VERSION "created by canmatrix"

NS_ :

BS_:

BU_: FLEA IMU_MMP2 MAP DMS VIC GWS MGW ADAS FVC CR_RL CR_RR CR_FL CR_FR FR_FC

BO_ 1970 SW_ID_Video: 8 FVC

BO_ 1983 DBC_Version: 2 MGW
 SG_ DBC_VersionIdMinor : 8|8@1+ (1,0) [0|255] ""  ADAS,FR_FC
 SG_ DBC_VersionIdMajor : 0|8@1+ (1,0) [0|255] ""  ADAS,FR_FC

BO_ 1969 SW_ID_RadarFront: 12 ADAS

BO_ 1968 SW_ID_DASy: 12 ADAS

BO_ 1793 FleaToDasyTP: 64 FLEA

BO_ 1792 DASyToFleaTP: 64 ADAS

BO_ 30 TimeSync: 8 MGW
 SG_ TimeSync_Type M : 7|8@0+ (1,0) [0|255] ""  ADAS,FVC,CR_RL,CR_RR,CR_FL,CR_FR,FR_FC
 SG_ TimeSync_CRC : 15|8@0+ (1,0) [0|255] ""  ADAS,FVC,CR_RL,CR_RR,CR_FL,CR_FR,FR_FC
 SG_ TimeSync_SequenceCounter : 19|4@0+ (1,0) [0|15] ""  ADAS,FVC,CR_RL,CR_RR,CR_FL,CR_FR,FR_FC
 SG_ TimeSync_TimeDomain : 23|4@0+ (1,0) [0|15] ""  ADAS,FVC,CR_RL,CR_RR,CR_FL,CR_FR,FR_FC
 SG_ TimeSync_UserByte0 m32 : 31|8@0+ (1,0) [0|255] ""  ADAS,FVC,CR_RL,CR_RR,CR_FL,CR_FR,FR_FC
 SG_ TimeSync_SyncTimeSec m32 : 39|32@0+ (1,0) [0|4294967295] ""  ADAS,FVC,CR_RL,CR_RR,CR_FL,CR_FR,FR_FC
 SG_ TimeSync_OverflowOfSeconds m40 : 25|2@0+ (1,0) [0|3] ""  ADAS,FVC,CR_RL,CR_RR,CR_FL,CR_FR,FR_FC
 SG_ TimeSync_SGW m40 : 26|1@0+ (1,0) [0|1] ""  ADAS,FVC,CR_RL,CR_RR,CR_FL,CR_FR,FR_FC
 SG_ TimeSync_Reserved0 m40 : 31|5@0+ (1,0) [0|31] ""  ADAS,FVC,CR_RL,CR_RR,CR_FL,CR_FR,FR_FC
 SG_ TimeSync_SyncTimeNSec m40 : 39|32@0+ (1,0) [0|4294967295] ""  ADAS,FVC,CR_RL,CR_RR,CR_FL,CR_FR,FR_FC

BO_ 1225 EHR_LOC_POSE: 16 MAP
 SG_ EHR_LOC_Status : 80|4@1+ (1,0) [0|15] ""  ADAS
 SG_ EHR_LOC_POSE_YAW : 64|16@1+ (0.01,0) [0|655.35] "degree"  ADAS
 SG_ EHR_LOC_POSE_LONG : 32|32@1+ (1E-007,-180) [-180|249.4967295] ""  ADAS
 SG_ EHR_LOC_POSE_LAT : 0|32@1+ (1E-007,-90) [-90|339.4967295] ""  ADAS

BO_ 1224 EHR_GNSS_POS: 16 MAP
 SG_ EHR_GNSS_Stddev_long : 80|16@1+ (0.001,0) [0|65.535] "m"  ADAS
 SG_ EHR_GNSS_Stddev_lat : 64|16@1+ (0.001,0) [0|65.535] "m"  ADAS
 SG_ EHR_GNSS_POS_LONG : 32|32@1+ (1E-007,-180) [-180|249.4967295] ""  ADAS
 SG_ EHR_GNSS_POS_LAT : 0|32@1+ (1E-007,-90) [-90|339.4967295] ""  ADAS

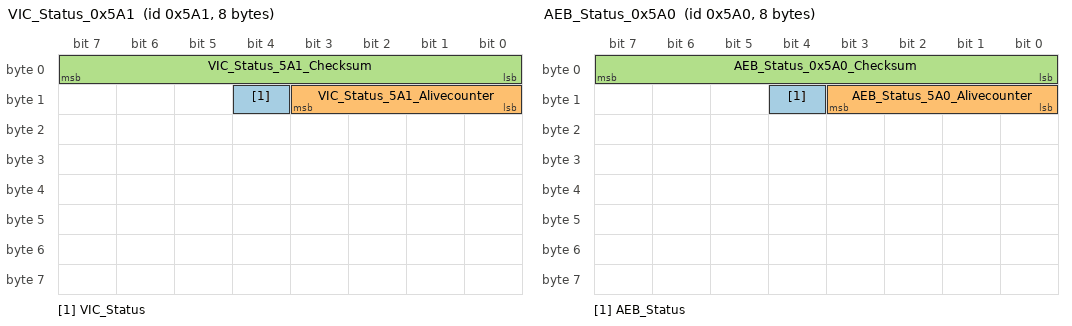
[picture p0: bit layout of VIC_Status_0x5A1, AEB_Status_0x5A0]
BO_ 1441 VIC_Status_0x5A1: 8 VIC
 SG_ VIC_Status : 12|1@1+ (1,0) [0|1] ""  MGW
 SG_ VIC_Status_5A1_Alivecounter : 8|4@1+ (1,0) [0|15] ""  MGW
 SG_ VIC_Status_5A1_Checksum : 0|8@1+ (1,0) [0|255] ""  MGW

BO_ 1440 AEB_Status_0x5A0: 8 MGW
 SG_ AEB_Status : 12|1@1+ (1,0) [0|1] ""  VIC
 SG_ AEB_Status_5A0_Alivecounter : 8|4@1+ (1,0) [0|15] ""  VIC
 SG_ AEB_Status_0x5A0_Checksum : 0|8@1+ (1,0) [0|255] ""  VIC

BO_ 1791 VariantCoding: 8 MGW
 SG_ Vehicle_Variant : 0|4@1+ (1,0) [0|15] ""  ADAS

BO_ 291 ACC_06_DASy: 16 ADAS
 SG_ ADAS_VehSecureReq : 79|2@0+ (1,0) [0|1] ""  MGW
 SG_ ADAS_LimAx_LIM : 119|16@0+ (0.000381,-12) [-12|12.968835] ""  MGW
 SG_ ADAS_ShtDwnStrat_ACC : 65|2@0+ (1,0) [0|3] ""  MGW
 SG_ ADAS_ShtDwnStrat_Lim : 77|2@0+ (1,0) [0|3] ""  MGW
 SG_ ADAS_LimActReq : 75|1@0+ (1,0) [0|1] ""  MGW
 SG_ ADAS_EngStartRun_Req : 74|1@0+ (1,0) [0|1] ""  MGW
 SG_ ADAS_CoastReq_ACC : 72|1@0+ (1,0) [0|1] ""  MGW
 SG_ ADAS_Sts_LIM : 68|3@0+ (1,0) [0|7] ""  MGW
 SG_ LIM_pos_Sollbeschl_Grad_02_D : 111|8@0+ (0.05,0) [0|12.75] "Unit_MeterPerCubicSecon"  MGW
 SG_ LIM_neg_Sollbeschl_Grad_02_D : 103|8@0+ (0.05,0) [0|12.75] "Unit_MeterPerCubicSecon"  MGW
 SG_ LIM_zul_Regelabw_unten_D : 85|6@0+ (0.024,0) [0|1.512] "Unit_MeterPerSeconSquar"  MGW
 SG_ LIM_zul_Regelabw_oben_D : 92|5@0+ (0.0625,0) [0|1.9375] "Unit_MeterPerSeconSquar"  MGW
 SG_ ACC_pos_Sollbeschl_Grad_02_D : 55|8@0+ (0.05,0) [0|12.75] "Unit_MeterPerCubicSecon"  MGW
 SG_ ACC_neg_Sollbeschl_Grad_02_D : 47|8@0+ (0.05,0) [0|12.75] "Unit_MeterPerCubicSecon"  MGW
 SG_ ACC_Minimale_Bremsung_D : 56|1@0+ (1,0) [0|1] ""  MGW
 SG_ ACC_zul_Regelabw_unten_D : 23|6@0+ (0.024,0) [0|1.512] "Unit_MeterPerSeconSquar"  MGW
 SG_ ACC_zul_Regelabw_oben_D : 36|5@0+ (0.0625,0) [0|1.9375] "Unit_MeterPerSeconSquar"  MGW
 SG_ ACC_06_CheckSum_D : 7|8@0+ (1,0) [0|255] ""  MGW
 SG_ ACC_06_AliveCounter_D : 15|4@0+ (1,0) [0|14] ""  MGW

BO_ 842 ADAS_0x34A: 8 ADAS
 SG_ ADAS_Sts_HWA : 2|3@0+ (1,0) [0|7] ""  MGW
 SG_ ADAS_HiwayExitAuxSts : 5|3@0+ (1,0) [0|7] ""  MGW
 SG_ ADAS_ActvBtnDispReq_HEA : 7|2@0+ (1,0) [0|3] ""  MGW
 SG_ ADAS_Sts_ALC : 11|4@0+ (1,0) [0|15] ""  MGW,CR_RR
 SG_ ADAS_HandsOffTakeOverReq_ALC : 15|1@0+ (1,0) [0|1] ""  MGW
 SG_ ADAS_OverMod_ALC : 16|1@0+ (1,0) [0|1] ""  MGW
 SG_ ADAS_ALCAudioWarnLe : 17|1@0+ (1,0) [0|1] ""  MGW
 SG_ ADAS_LCReturnToLane : 19|2@0+ (1,0) [0|3] ""  MGW
 SG_ ADAS_LeLaneOccupied : 20|1@0+ (1,0) [0|1] ""  MGW
 SG_ ADAS_RiLaneOccupied : 21|1@0+ (1,0) [0|1] ""  MGW
 SG_ ADAS_LeLCArrow : 23|2@0+ (1,0) [0|3] ""  MGW
 SG_ ADAS_ALCAudioWarnRi : 24|1@0+ (1,0) [0|1] ""  MGW
 SG_ ADAS_LeLaneOccupiedWarn : 25|1@0+ (1,0) [0|1] ""  MGW
 SG_ ADAS_RiLaneOccupiedWarn : 26|1@0+ (1,0) [0|1] ""  MGW
 SG_ ADAS_ALCTakeOverReq : 27|1@0+ (1,0) [0|1] ""  MGW
 SG_ ADAS_LCSysFlt : 28|1@0+ (1,0) [0|1] ""  MGW
 SG_ ADAS_TurnLampOff : 30|2@0+ (1,0) [0|3] ""  MGW
 SG_ ADAS_CtrlrFlt : 41|2@0+ (1,0) [0|3] ""  MGW,FVC,CR_RL,CR_RR,CR_FL,CR_FR,FR_FC
 SG_ ADAS_RiLCArrow : 49|2@0+ (1,0) [0|3] ""  MGW
 SG_ ADAS_Sts_ESS : 52|3@0+ (1,0) [0|7] ""  MGW
 SG_ ADAS_Warn_ESS : 54|2@0+ (1,0) [0|3] ""  MGW
 SG_ ADAS_DrvrOccpyReq : 55|1@0+ (1,0) [0|1] ""  MGW

BO_ 1184 HMI_0x4A0_ADAS: 8 VIC
 SG_ MainSwitchACC : 0|1@1+ (1,0) [0|1] ""  MGW,ADAS
 SG_ MainSwitchADC : 1|1@1+ (1,0) [0|1] ""  MGW,ADAS
 SG_ MainSwitchACCplus : 2|1@1+ (1,0) [0|1] ""  MGW,ADAS
 SG_ MainSwitchTLR : 3|1@1+ (1,0) [0|1] ""  MGW,ADAS
 SG_ ACCplusActivationSubfeature_SLA : 4|1@1+ (1,0) [0|1] ""  MGW,ADAS
 SG_ ACCplusActivationSubfeatureCSA : 5|1@1+ (1,0) [0|1] ""  MGW,ADAS
 SG_ ACCplusActivationSubfeatureSPA : 6|1@1+ (1,0) [0|1] ""  MGW,ADAS
 SG_ ACCplusActivationSubfeatureFrict : 7|1@1+ (1,0) [0|1] ""  MGW,ADAS
 SG_ ACCDriverInputTimeGapChange : 8|1@1+ (1,0) [0|1] ""  MGW,ADAS
 SG_ ACCDriverInputSet : 9|1@1+ (1,0) [0|1] ""  MGW,ADAS
 SG_ ACCDriverInputResume : 10|1@1+ (1,0) [0|1] ""  MGW,ADAS
 SG_ ACCDriverInputSetSpeedDecrease : 11|1@1+ (1,0) [0|1] ""  MGW,ADAS
 SG_ ACCDriverInputSetSpeedIncrease : 12|1@1+ (1,0) [0|1] ""  MGW,ADAS
 SG_ ACCDriverInputConfirmation : 13|1@1+ (1,0) [0|1] ""  MGW,ADAS
 SG_ ADCVariantSelection : 14|3@1+ (1,0) [0|7] ""  MGW,ADAS
 SG_ ADCDriverInputActivationDeactiva : 17|1@1+ (1,0) [0|1] ""  MGW,ADAS
 SG_ ADCParameterSelection : 18|3@1+ (1,0) [0|7] ""  MGW,ADAS
 SG_ ACFDrivingMode : 21|3@1+ (1,0) [0|7] ""  MGW,ADAS
 SG_ Measurement_label : 60|4@1+ (1,0) [0|15] ""  MGW,ADAS
 SG_ FrontCollisionWarningSensitivity : 24|2@1+ (1,0) [0|3] ""  MGW,ADAS

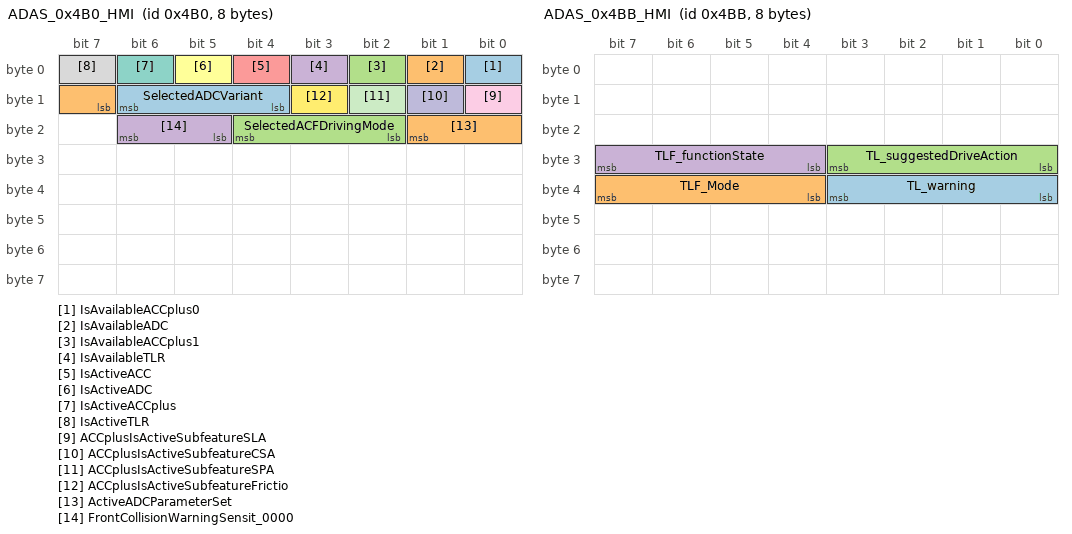
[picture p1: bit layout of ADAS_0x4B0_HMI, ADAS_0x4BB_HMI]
BO_ 1200 ADAS_0x4B0_HMI: 8 ADAS
 SG_ IsAvailableACCplus0 : 0|1@1+ (1,0) [0|1] ""  VIC,MGW
 SG_ IsAvailableADC : 1|1@1+ (1,0) [0|1] ""  VIC,MGW
 SG_ IsAvailableACCplus1 : 2|1@1+ (1,0) [0|1] ""  VIC,MGW
 SG_ IsAvailableTLR : 3|1@1+ (1,0) [0|1] ""  VIC,MGW
 SG_ IsActiveACC : 4|1@1+ (1,0) [0|1] ""  VIC,MGW
 SG_ IsActiveADC : 5|1@1+ (1,0) [0|1] ""  VIC,MGW
 SG_ IsActiveACCplus : 6|1@1+ (1,0) [0|1] ""  VIC,MGW
 SG_ IsActiveTLR : 7|1@1+ (1,0) [0|1] ""  VIC,MGW
 SG_ ACCplusIsActiveSubfeatureSLA : 8|1@1+ (1,0) [0|1] ""  VIC,MGW
 SG_ ACCplusIsActiveSubfeatureCSA : 9|1@1+ (1,0) [0|1] ""  VIC,MGW
 SG_ ACCplusIsActiveSubfeatureSPA : 10|1@1+ (1,0) [0|1] ""  VIC,MGW
 SG_ ACCplusIsActiveSubfeatureFrictio : 11|1@1+ (1,0) [0|1] ""  VIC,MGW
 SG_ SelectedADCVariant : 12|3@1+ (1,0) [0|7] ""  VIC,MGW
 SG_ ActiveADCParameterSet : 15|3@1+ (1,0) [0|7] ""  VIC,MGW
 SG_ SelectedACFDrivingMode : 18|3@1+ (1,0) [0|7] ""  VIC,MGW
 SG_ FrontCollisionWarningSensit_0000 : 21|2@1+ (1,0) [0|3] ""  VIC,MGW

BO_ 1210 ADAS_0x4BA_HMI: 64 ADAS
 SG_ TurnIndicatorSignal : 118|2@1+ (1,0) [0|3] ""  VIC,MGW
 SG_ AlcPremiumState : 116|2@1+ (1,0) [0|3] ""  VIC,MGW
 SG_ AlcPlusState : 114|2@1+ (1,0) [0|3] ""  VIC,MGW
 SG_ AlcEnhancedStatus : 112|2@1+ (1,0) [0|3] ""  VIC,MGW
 SG_ ALCFeatureStatus : 456|8@1+ (1,0) [0|31] ""  VIC,MGW
 SG_ LKAStatus : 464|4@1+ (1,0) [0|15] ""  VIC,MGW
 SG_ LDWStatus : 468|4@1+ (1,0) [0|15] ""  VIC,MGW
 SG_ ELKSLStatus : 472|4@1+ (1,0) [0|15] ""  VIC,MGW
 SG_ ELKHREStatus : 476|4@1+ (1,0) [0|15] ""  VIC,MGW
 SG_ ELKVREStatus : 480|4@1+ (1,0) [0|15] ""  VIC,MGW
 SG_ ELKOTStatus : 484|4@1+ (1,0) [0|15] ""  VIC,MGW
 SG_ ELKOCVStatus : 488|4@1+ (1,0) [0|15] ""  VIC,MGW
 SG_ OffsetReason : 451|4@1+ (1,0) [0|15] ""  VIC,MGW
 SG_ OffsetDirection : 446|2@1+ (1,0) [0|3] ""  VIC,MGW
 SG_ DisplayedLaneMarking4Y : 432|8@1- (0.06,0) [-7.68|7.62] "m"  VIC,MGW
 SG_ DisplayedLaneMarking3Y : 424|8@1- (0.06,0) [-7.68|7.62] "m"  VIC,MGW
 SG_ DisplayedLaneMarking2Y : 416|8@1- (0.06,0) [-7.68|7.62] "m"  VIC,MGW
 SG_ DisplayedLaneMarking1Y : 408|8@1- (0.06,0) [-7.68|7.62] "m"  VIC,MGW
 SG_ DisplayedLaneMarking4Type : 406|2@1+ (1,0) [0|3] ""  VIC,MGW
 SG_ DisplayedLaneMarking3Type : 404|2@1+ (1,0) [0|3] ""  VIC,MGW
 SG_ DisplayedLaneMarking2Type : 402|2@1+ (1,0) [0|3] ""  VIC,MGW
 SG_ DisplayedLaneMarking1Type : 400|2@1+ (1,0) [0|3] ""  VIC,MGW
 SG_ DisplayedLaneMarking4Color : 395|3@1+ (1,0) [0|7] ""  VIC,MGW
 SG_ DisplayedLaneMarking3Color : 392|3@1+ (1,0) [0|7] ""  VIC,MGW
 SG_ DisplayedLaneMarking2Color : 387|3@1+ (1,0) [0|7] ""  VIC,MGW
 SG_ DisplayedLaneMarking1Color : 384|3@1+ (1,0) [0|7] ""  VIC,MGW
 SG_ Number02 : 368|16@1+ (1,0) [0|65535] ""  VIC,MGW
 SG_ Number01 : 352|16@1+ (1,0) [0|65535] ""  VIC,MGW
 SG_ Indicator16 : 351|1@1+ (1,0) [0|1] ""  VIC,MGW
 SG_ Indicator15 : 350|1@1+ (1,0) [0|1] ""  VIC,MGW
 SG_ Indicator14 : 349|1@1+ (1,0) [0|1] ""  VIC,MGW
 SG_ Indicator13 : 348|1@1+ (1,0) [0|1] ""  VIC,MGW
 SG_ Indicator12 : 347|1@1+ (1,0) [0|1] ""  VIC,MGW
 SG_ Indicator11 : 346|1@1+ (1,0) [0|1] ""  VIC,MGW
 SG_ Indicator10 : 345|1@1+ (1,0) [0|1] ""  VIC,MGW
 SG_ Indicator09 : 344|1@1+ (1,0) [0|1] ""  VIC,MGW
 SG_ Indicator08 : 343|1@1+ (1,0) [0|1] ""  VIC,MGW
 SG_ Indicator07 : 342|1@1+ (1,0) [0|1] ""  VIC,MGW
 SG_ Indicator06 : 341|1@1+ (1,0) [0|1] ""  VIC,MGW
 SG_ Indicator05 : 340|1@1+ (1,0) [0|1] ""  VIC,MGW
 SG_ Indicator04 : 339|1@1+ (1,0) [0|1] ""  VIC,MGW
 SG_ Indicator03 : 338|1@1+ (1,0) [0|1] ""  VIC,MGW
 SG_ Indicator02 : 337|1@1+ (1,0) [0|1] ""  VIC,MGW
 SG_ Indicator01 : 336|1@1+ (1,0) [0|1] ""  VIC,MGW
 SG_ ACC_ICON_LADI : 334|2@1+ (1,0) [0|3] ""  VIC,MGW
 SG_ ADAS_4BA_CheckSum : 0|16@1+ (1,0) [0|65535] ""  VIC,MGW
 SG_ CurvatureInformation : 120|8@1- (25,0) [-3200|3175] "m"  VIC,MGW
 SG_ TrafficSignSpeedLimit : 128|5@1+ (5,0) [0|150] "kph"  VIC,MGW
 SG_ TrafficLightStatus : 140|2@1+ (1,0) [0|3] ""  VIC,MGW
 SG_ TrafficLightDisplayRequest : 136|2@1+ (1,0) [0|3] ""  VIC,MGW
 SG_ ACCTrafficLightReaction : 138|2@1+ (1,0) [0|3] ""  VIC,MGW
 SG_ SensorConeFrontCenter : 133|2@1+ (1,0) [0|3] ""  VIC,MGW
 SG_ NeighboringVehicle1VehicleType : 163|3@1+ (1,0) [0|7] ""  VIC,MGW
 SG_ NeighboringVehicle1X : 144|8@1+ (1.2,-50.4) [-50.4|255.6] "m"  VIC,MGW
 SG_ NeighboringVehicle1Y : 152|8@1- (0.06,0) [-7.68|7.62] "m"  VIC,MGW
 SG_ NeighboringVehicle1AugmentedData : 160|3@1+ (1,0) [0|7] ""  VIC,MGW
 SG_ NeighboringVehicle2VehicleType : 187|3@1+ (1,0) [0|7] ""  VIC,MGW
 SG_ NeighboringVehicle2X : 168|8@1+ (1.2,-50.4) [-50.4|255.6] "m"  VIC,MGW
 SG_ NeighboringVehicle2Y : 176|8@1- (0.06,0) [-7.68|7.62] "m"  VIC,MGW
 SG_ ADAS_4BA_AliveCounter : 16|8@1+ (1,0) [0|255] ""  VIC,MGW
 SG_ NeighboringVehicle2AugmentedData : 184|3@1+ (1,0) [0|7] ""  VIC,MGW
 SG_ NeighboringVehicle3VehicleType : 211|3@1+ (1,0) [0|7] ""  VIC,MGW
 SG_ NeighboringVehicle3X : 192|8@1+ (1.2,-50.4) [-50.4|255.6] "m"  VIC,MGW
 SG_ NeighboringVehicle3Y : 200|8@1- (0.06,0) [-7.68|7.62] "m"  VIC,MGW
 SG_ NeighboringVehicle3AugmentedData : 208|3@1+ (1,0) [0|7] ""  VIC,MGW
 SG_ NeighboringVehicle4VehicleType : 235|3@1+ (1,0) [0|7] ""  VIC,MGW
 SG_ NeighboringVehicle4X : 216|8@1+ (1.2,-50.4) [-50.4|255.6] "m"  VIC,MGW
 SG_ NeighboringVehicle4Y : 224|8@1- (0.06,0) [-7.68|7.62] "m"  VIC,MGW
 SG_ NeighboringVehicle4AugmentedData : 232|3@1+ (1,0) [0|7] ""  VIC,MGW
 SG_ NeighboringVehicle5VehicleType : 259|3@1+ (1,0) [0|7] ""  VIC,MGW
 SG_ NeighboringVehicle5X : 240|8@1+ (1.2,-50.4) [-50|250] "m"  VIC,MGW
 SG_ NeighboringVehicle5Y : 248|8@1- (0.06,0) [-7.68|7.62] "m"  VIC,MGW
 SG_ NeighboringVehicle5AugmentedData : 256|3@1+ (1,0) [0|7] ""  VIC,MGW
 SG_ NeighboringVehicle6VehicleType : 283|3@1+ (1,0) [0|7] ""  VIC,MGW
 SG_ NeighboringVehicle6X : 264|8@1+ (1.2,-50.4) [-50|250] "m"  VIC,MGW
 SG_ LedHadState : 24|4@1+ (1,0) [0|15] ""  VIC,MGW
 SG_ NeighboringVehicle6Y : 272|8@1- (0.06,0) [-7.68|7.62] "m"  VIC,MGW
 SG_ NeighboringVehicle6AugmentedData : 280|3@1+ (1,0) [0|7] ""  VIC,MGW
 SG_ NeighboringVehicle7VehicleType : 307|3@1+ (1,0) [0|7] ""  VIC,MGW
 SG_ NeighboringVehicle7X : 288|8@1+ (1.2,-50.4) [-50|250] "m"  VIC,MGW
 SG_ NeighboringVehicle7Y : 296|8@1- (0.06,0) [-7.68|7.62] "m"  VIC,MGW
 SG_ NeighboringVehicle7AugmentedData : 304|3@1+ (1,0) [0|7] ""  VIC,MGW
 SG_ NeighboringVehicle8VehicleType : 331|3@1+ (1,0) [0|7] ""  VIC,MGW
 SG_ HwaHfStatus : 28|3@1+ (1,0) [0|7] ""  VIC,MGW
 SG_ NeighboringVehicle8X : 312|8@1+ (1.2,-50.4) [-50.4|255.6] "m"  VIC,MGW
 SG_ NeighboringVehicle8Y : 320|8@1- (0.06,0) [-7.68|7.62] "m"  VIC,MGW
 SG_ NeighboringVehicle8AugmentedData : 328|3@1+ (1,0) [0|7] ""  VIC,MGW
 SG_ HwaHonStatus : 32|3@1+ (1,0) [0|7] ""  VIC,MGW
 SG_ HwaAccStatus : 35|3@1+ (1,0) [0|7] ""  VIC,MGW
 SG_ SetSpeed : 40|8@1+ (1,0) [0|255] "kph"  VIC,MGW
 SG_ SetSpeedColor : 48|3@1+ (1,0) [0|7] ""  VIC,MGW
 SG_ DisplayedEgoSpeed : 56|8@1+ (1,0) [0|255] "kph"  VIC,MGW
 SG_ DisplayedEgoSpeedColor : 64|3@1+ (1,0) [0|7] ""  VIC,MGW
 SG_ DisplayedLaneMarkingLeftType : 67|2@1+ (1,0) [0|3] ""  MGW
 SG_ DisplayedLaneMarkingLeftColor : 69|3@1+ (1,0) [0|7] ""  MGW
 SG_ DisplayedLaneMarkingRightType : 72|2@1+ (1,0) [0|3] ""  MGW
 SG_ DisplayedLaneMarkingRightColor : 74|3@1+ (1,0) [0|7] ""  MGW
 SG_ TimeGapSetValue : 77|3@1+ (1,0) [0|7] ""  VIC,MGW
 SG_ TimeGapColor : 80|3@1+ (1,0) [0|7] ""  VIC,MGW
 SG_ ReducedTimeGap : 440|6@1+ (1,0) [0|63] "s"  VIC,MGW
 SG_ AdcStateInformation : 448|3@1+ (1,0) [0|7] ""  VIC,MGW
 SG_ EgoLaneChange : 83|3@1+ (1,0) [0|7] ""  VIC,MGW
 SG_ DisplayedTextMessageId : 88|8@1+ (1,0) [0|255] ""  VIC,MGW
 SG_ PopupTextMessage : 86|2@1+ (1,0) [0|3] ""  VIC,MGW
 SG_ AudioNotificationId : 51|4@1+ (1,0) [0|15] ""  VIC,MGW
 SG_ AuxiliarySymbol : 96|6@1+ (1,0) [0|63] ""  VIC,MGW
 SG_ EgoLaneAssignment : 102|2@1+ (1,0) [0|3] ""  VIC,MGW
 SG_ TrafficLightDistance : 104|4@1+ (1,0) [0|15] "m"  VIC,MGW

BO_ 1211 ADAS_0x4BB_HMI: 8 MGW
 SG_ TL_warning : 35|4@0+ (1,0) [0|15] ""  ADAS,FR_FC
 SG_ TLF_Mode : 39|4@0+ (1,0) [0|15] ""  ADAS,FR_FC
 SG_ TL_suggestedDriveAction : 27|4@0+ (1,0) [0|15] ""  ADAS,FR_FC
 SG_ TLF_functionState : 31|4@0+ (1,0) [0|15] ""  ADAS,FR_FC

BO_ 1212 ADAS_0x4BC_HMI: 64 ADAS
 SG_ ADAS_TrafficSign1_Main : 0|8@1+ (1,0) [0|255] ""  VIC,MGW
 SG_ ADAS_TrafficSign1_AdditionalSign : 8|5@1+ (1,0) [0|31] ""  VIC,MGW
 SG_ ADAS_TrafficSign1_Distance : 13|5@1+ (1,0) [0|31] ""  VIC,MGW
 SG_ ADAS_TrafficSign1_Status : 18|3@1+ (1,0) [0|7] ""  VIC,MGW
 SG_ ADAS_TrafficSign2_Main : 21|8@1+ (1,0) [0|255] ""  VIC,MGW
 SG_ ADAS_TrafficSign2_AdditionalSign : 29|5@1+ (1,0) [0|31] ""  VIC,MGW
 SG_ ADAS_TrafficSign2_Distance : 34|5@1+ (1,0) [0|31] ""  VIC,MGW
 SG_ ADAS_TrafficSign2_Status : 39|3@1+ (1,0) [0|7] ""  VIC,MGW
 SG_ ADAS_TrafficSign3_Main : 42|8@1+ (1,0) [0|255] ""  VIC,MGW
 SG_ ADAS_TrafficSign3_AdditionalSign : 50|5@1+ (1,0) [0|31] ""  VIC,MGW
 SG_ ADAS_TrafficSign3_Distance : 55|5@1+ (1,0) [0|31] ""  VIC,MGW
 SG_ ADAS_TrafficSign3_Status : 60|3@1+ (1,0) [0|7] ""  VIC,MGW
 SG_ ADAS_RSF_Status : 63|3@1+ (1,0) [0|7] ""  VIC,MGW
 SG_ ADAS_Curv_1_dy_00 : 66|9@1+ (0.1,-25.6) [-25.6|25.5] "m"  VIC,MGW
 SG_ ADAS_Curv_1_dy_01 : 75|9@1+ (0.1,-25.6) [-25.6|25.5] "m"  VIC,MGW
 SG_ ADAS_Curv_1_dy_02 : 84|9@1+ (0.1,-25.6) [-25.6|25.5] "m"  VIC,MGW
 SG_ ADAS_Curv_1_dy_03 : 93|9@1+ (0.1,-25.6) [-25.6|25.5] "m"  VIC,MGW
 SG_ ADAS_Curv_1_dy_04 : 102|9@1+ (0.1,-25.6) [-25.6|25.5] "m"  VIC,MGW
 SG_ ADAS_Curv_1_dy_05 : 111|9@1+ (0.1,-25.6) [-25.6|25.5] "m"  VIC,MGW
 SG_ ADAS_Curv_1_dy_06 : 120|9@1+ (0.1,-25.6) [-25.6|25.5] "m"  VIC,MGW
 SG_ ADAS_Curv_1_dy_07 : 129|9@1+ (0.1,-25.6) [-25.6|25.5] "m"  VIC,MGW
 SG_ ADAS_Curv_1_dy_08 : 138|9@1+ (0.1,-25.6) [-25.6|25.5] "m"  VIC,MGW
 SG_ ADAS_Curv_1_dy_09 : 147|9@1+ (0.1,-25.6) [-25.6|25.5] "m"  VIC,MGW
 SG_ ADAS_Curv_1_dy_10 : 156|9@1+ (0.1,-25.6) [-25.6|25.5] "m"  VIC,MGW
 SG_ ADAS_Curv_1_dy_11 : 165|9@1+ (0.1,-25.6) [-25.6|25.5] "m"  VIC,MGW
 SG_ ADAS_Curv_1_dy_12 : 174|9@1+ (0.1,-25.6) [-25.6|25.5] "m"  VIC,MGW
 SG_ ADAS_Curv_1_dy_13 : 183|9@1+ (0.1,-25.6) [-25.6|25.5] "m"  VIC,MGW
 SG_ ADAS_Curv_1_dy_14 : 192|9@1+ (0.1,-25.6) [-25.6|25.5] "m"  VIC,MGW
 SG_ ADAS_Curv_1_dy_15 : 201|9@1+ (0.1,-25.6) [-25.6|25.5] "m"  VIC,MGW
 SG_ ADAS_Curv_2_dy_00 : 210|9@1+ (0.1,-25.6) [-25.6|25.5] "m"  VIC,MGW
 SG_ ADAS_Curv_2_dy_01 : 219|9@1+ (0.1,-25.6) [-25.6|25.5] "m"  VIC,MGW
 SG_ ADAS_Curv_2_dy_02 : 228|9@1+ (0.1,-25.6) [-25.6|25.5] "m"  VIC,MGW
 SG_ ADAS_Curv_2_dy_03 : 237|9@1+ (0.1,-25.6) [-25.6|25.5] "m"  VIC,MGW
 SG_ ADAS_Curv_2_dy_04 : 246|9@1+ (0.1,-25.6) [-25.6|25.5] "m"  VIC,MGW
 SG_ ADAS_Curv_2_dy_05 : 255|9@1+ (0.1,-25.6) [-25.6|25.5] "m"  VIC,MGW
 SG_ ADAS_Curv_2_dy_06 : 264|9@1+ (0.1,-25.6) [-25.6|25.5] "m"  VIC,MGW
 SG_ ADAS_Curv_2_dy_07 : 273|9@1+ (0.1,-25.6) [-25.6|25.5] "m"  VIC,MGW
 SG_ ADAS_Curv_2_dy_08 : 282|9@1+ (0.1,-25.6) [-25.6|25.5] "m"  VIC,MGW
 SG_ ADAS_Curv_2_dy_09 : 291|9@1+ (0.1,-25.6) [-25.6|25.5] "m"  VIC,MGW
 SG_ ADAS_Curv_2_dy_10 : 300|9@1+ (0.1,-25.6) [-25.6|25.5] "m"  VIC,MGW
 SG_ ADAS_Curv_2_dy_11 : 309|9@1+ (0.1,-25.6) [-25.6|25.5] "m"  VIC,MGW
 SG_ ADAS_Curv_2_dy_12 : 318|9@1+ (0.1,-25.6) [-25.6|25.5] "m"  VIC,MGW
 SG_ ADAS_Curv_2_dy_13 : 327|9@1+ (0.1,-25.6) [-25.6|25.5] "m"  VIC,MGW
 SG_ ADAS_Curv_2_dy_14 : 336|9@1+ (0.1,-25.6) [-25.6|25.5] "m"  VIC,MGW
 SG_ ADAS_Curv_2_dy_15 : 345|9@1+ (0.1,-25.6) [-25.6|25.5] "m"  VIC,MGW
 SG_ ADAS_Curv_3_dy_00 : 354|9@1+ (0.1,-25.6) [-25.6|25.5] "m"  VIC,MGW
 SG_ ADAS_Curv_3_dy_01 : 363|9@1+ (0.1,-25.6) [-25.6|25.5] "m"  VIC,MGW
 SG_ ADAS_Curv_3_dy_02 : 372|9@1+ (0.1,-25.6) [-25.6|25.5] "m"  VIC,MGW
 SG_ ADAS_Curv_3_dy_03 : 381|9@1+ (0.1,-25.6) [-25.6|25.5] "m"  VIC,MGW
 SG_ ADAS_Curv_3_dy_04 : 390|9@1+ (0.1,-25.6) [-25.6|25.5] "m"  VIC,MGW
 SG_ ADAS_Curv_3_dy_05 : 399|9@1+ (0.1,-25.6) [-25.6|25.5] "m"  VIC,MGW
 SG_ ADAS_Curv_3_dy_06 : 408|9@1+ (0.1,-25.6) [-25.6|25.5] "m"  VIC,MGW
 SG_ ADAS_Curv_3_dy_07 : 417|9@1+ (0.1,-25.6) [-25.6|25.5] "m"  VIC,MGW
 SG_ ADAS_Curv_3_dy_08 : 426|9@1+ (0.1,-25.6) [-25.6|25.5] "m"  VIC,MGW
 SG_ ADAS_Curv_3_dy_09 : 435|9@1+ (0.1,-25.6) [-25.6|25.5] "m"  VIC,MGW
 SG_ ADAS_Curv_3_dy_10 : 444|9@1+ (0.1,-25.6) [-25.6|25.5] "m"  VIC,MGW
 SG_ ADAS_Curv_3_dy_11 : 453|9@1+ (0.1,-25.6) [-25.6|25.5] "m"  VIC,MGW
 SG_ ADAS_Curv_3_dy_12 : 462|9@1+ (0.1,-25.6) [-25.6|25.5] "m"  VIC,MGW
 SG_ ADAS_Curv_3_dy_13 : 471|9@1+ (0.1,-25.6) [-25.6|25.5] "m"  VIC,MGW
 SG_ ADAS_Curv_3_dy_14 : 480|9@1+ (0.1,-25.6) [-25.6|25.5] "m"  VIC,MGW
 SG_ ADAS_Curv_3_dy_15 : 489|9@1+ (0.1,-25.6) [-25.6|25.5] "m"  VIC,MGW
 SG_ ADAS_Curv_1_NumValidPoints : 498|4@1+ (1,0) [0|15] ""  VIC,MGW
 SG_ ADAS_Curv_2_NumValidPoints : 502|4@1+ (1,0) [0|15] ""  VIC,MGW
 SG_ ADAS_Curv_3_NumValidPoints : 506|4@1+ (1,0) [0|15] ""  VIC,MGW

BO_ 1213 ADAS_0x4BD_HMI: 64 ADAS
 SG_ ADAS_Curv_4_NumValidPoints : 0|4@1+ (1,0) [0|15] ""  VIC,MGW
 SG_ ADAS_Curv_RefLine_NumValidPoints : 4|4@1+ (1,0) [0|15] ""  VIC,MGW
 SG_ ADAS_Curv_4_dy_00 : 8|9@1+ (0.1,-25.6) [-25.6|25.5] "m"  VIC,MGW
 SG_ ADAS_Curv_4_dy_01 : 17|9@1+ (0.1,-25.6) [-25.6|25.5] "m"  VIC,MGW
 SG_ ADAS_Curv_4_dy_02 : 26|9@1+ (0.1,-25.6) [-25.6|25.5] "m"  VIC,MGW
 SG_ ADAS_Curv_4_dy_03 : 35|9@1+ (0.1,-25.6) [-25.6|25.5] "m"  VIC,MGW
 SG_ ADAS_Curv_4_dy_04 : 44|9@1+ (0.1,-25.6) [-25.6|25.5] "m"  VIC,MGW
 SG_ ADAS_Curv_4_dy_05 : 53|9@1+ (0.1,-25.6) [-25.6|25.5] "m"  VIC,MGW
 SG_ ADAS_Curv_4_dy_06 : 62|9@1+ (0.1,-25.6) [-25.6|25.5] "m"  VIC,MGW
 SG_ ADAS_Curv_4_dy_07 : 71|9@1+ (0.1,-25.6) [-25.6|25.5] "m"  VIC,MGW
 SG_ ADAS_Curv_4_dy_08 : 80|9@1+ (0.1,-25.6) [-25.6|25.5] "m"  VIC,MGW
 SG_ ADAS_Curv_4_dy_09 : 89|9@1+ (0.1,-25.6) [-25.6|25.5] "m"  VIC,MGW
 SG_ ADAS_Curv_4_dy_10 : 98|9@1+ (0.1,-25.6) [-25.6|25.5] "m"  VIC,MGW
 SG_ ADAS_Curv_4_dy_11 : 107|9@1+ (0.1,-25.6) [-25.6|25.5] "m"  VIC,MGW
 SG_ ADAS_Curv_4_dy_12 : 116|9@1+ (0.1,-25.6) [-25.6|25.5] "m"  VIC,MGW
 SG_ ADAS_Curv_4_dy_13 : 125|9@1+ (0.1,-25.6) [-25.6|25.5] "m"  VIC,MGW
 SG_ ADAS_Curv_4_dy_14 : 134|9@1+ (0.1,-25.6) [-25.6|25.5] "m"  VIC,MGW
 SG_ ADAS_Curv_4_dy_15 : 143|9@1+ (0.1,-25.6) [-25.6|25.5] "m"  VIC,MGW
 SG_ ADAS_Curv_RefLine_dy_00 : 152|9@1+ (0.1,-25.6) [-25.6|25.5] "m"  VIC,MGW
 SG_ ADAS_Curv_RefLine_dy_01 : 161|9@1+ (0.1,-25.6) [-25.6|25.5] "m"  VIC,MGW
 SG_ ADAS_Curv_RefLine_dy_02 : 170|9@1+ (0.1,-25.6) [-25.6|25.5] "m"  VIC,MGW
 SG_ ADAS_Curv_RefLine_dy_03 : 179|9@1+ (0.1,-25.6) [-25.6|25.5] "m"  VIC,MGW
 SG_ ADAS_Curv_RefLine_dy_04 : 188|9@1+ (0.1,-25.6) [-25.6|25.5] "m"  VIC,MGW
 SG_ ADAS_Curv_RefLine_dy_05 : 197|9@1+ (0.1,-25.6) [-25.6|25.5] "m"  VIC,MGW
 SG_ ADAS_Curv_RefLine_dy_06 : 206|9@1+ (0.1,-25.6) [-25.6|25.5] "m"  VIC,MGW
 SG_ ADAS_Curv_RefLine_dy_07 : 215|9@1+ (0.1,-25.6) [-25.6|25.5] "m"  VIC,MGW
 SG_ ADAS_Curv_RefLine_dy_08 : 224|9@1+ (0.1,-25.6) [-25.6|25.5] "m"  VIC,MGW
 SG_ ADAS_Curv_RefLine_dy_09 : 233|9@1+ (0.1,-25.6) [-25.6|25.5] "m"  VIC,MGW
 SG_ ADAS_Curv_RefLine_dy_10 : 242|9@1+ (0.1,-25.6) [-25.6|25.5] "m"  VIC,MGW
 SG_ ADAS_Curv_RefLine_dy_11 : 251|9@1+ (0.1,-25.6) [-25.6|25.5] "m"  VIC,MGW
 SG_ ADAS_Curv_RefLine_dy_12 : 260|9@1+ (0.1,-25.6) [-25.6|25.5] "m"  VIC,MGW
 SG_ ADAS_Curv_RefLine_dy_13 : 269|9@1+ (0.1,-25.6) [-25.6|25.5] "m"  VIC,MGW
 SG_ ADAS_Curv_RefLine_dy_14 : 278|9@1+ (0.1,-25.6) [-25.6|25.5] "m"  VIC,MGW
 SG_ ADAS_Curv_RefLine_dy_15 : 287|9@1+ (0.1,-25.6) [-25.6|25.5] "m"  VIC,MGW

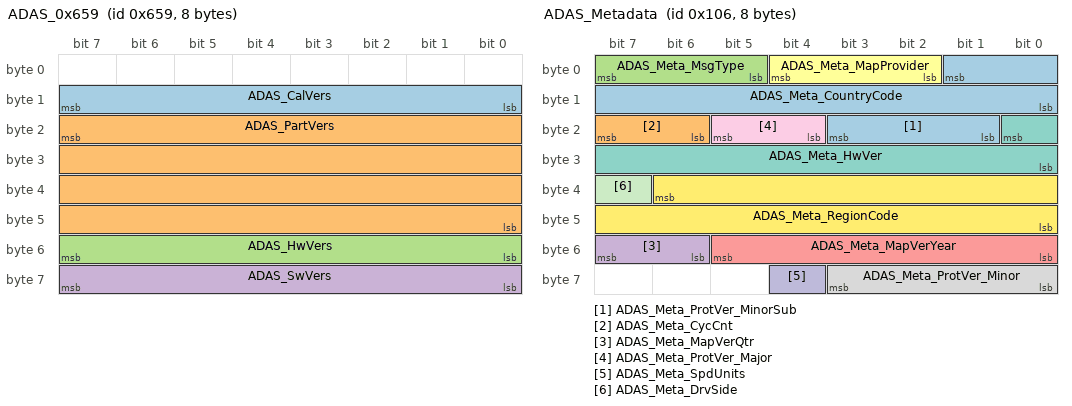
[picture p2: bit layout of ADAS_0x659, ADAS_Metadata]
BO_ 1625 ADAS_0x659: 8 ADAS
 SG_ ADAS_CalVers : 15|8@0+ (1,0) [0|255] ""  MGW
 SG_ ADAS_PartVers : 23|32@0+ (1,0) [0|4294967295] ""  MGW
 SG_ ADAS_HwVers : 55|8@0+ (1,0) [0|255] ""  MGW
 SG_ ADAS_SwVers : 63|8@0+ (1,0) [0|255] ""  MGW

BO_ 262 ADAS_Metadata: 8 MGW
 SG_ ADAS_Meta_ProtVer_MinorSub : 19|3@0+ (1,0) [0|7] ""  ADAS
 SG_ ADAS_Meta_CycCnt : 23|2@0+ (1,0) [0|3] ""  ADAS
 SG_ ADAS_Meta_MsgType : 7|3@0+ (1,0) [0|7] ""  ADAS
 SG_ ADAS_Meta_MapVerQtr : 55|2@0+ (1,1) [1|4] "Qtr"  ADAS
 SG_ ADAS_Meta_MapVerYear : 53|6@0+ (1,2000) [2000|2063] "Year"  ADAS
 SG_ ADAS_Meta_MapProvider : 4|3@0+ (1,0) [0|7] ""  ADAS
 SG_ ADAS_Meta_HwVer : 16|9@0+ (1,0) [0|511] ""  ADAS
 SG_ ADAS_Meta_ProtVer_Minor : 59|4@0+ (1,0) [0|15] ""  ADAS
 SG_ ADAS_Meta_ProtVer_Major : 21|2@0+ (1,0) [0|3] ""  ADAS
 SG_ ADAS_Meta_SpdUnits : 60|1@0+ (1,0) [0|1] ""  ADAS
 SG_ ADAS_Meta_DrvSide : 39|1@0+ (1,0) [0|1] ""  ADAS
 SG_ ADAS_Meta_RegionCode : 38|15@0+ (1,0) [0|32767] ""  ADAS
 SG_ ADAS_Meta_CountryCode : 1|10@0+ (1,0) [0|1023] ""  ADAS

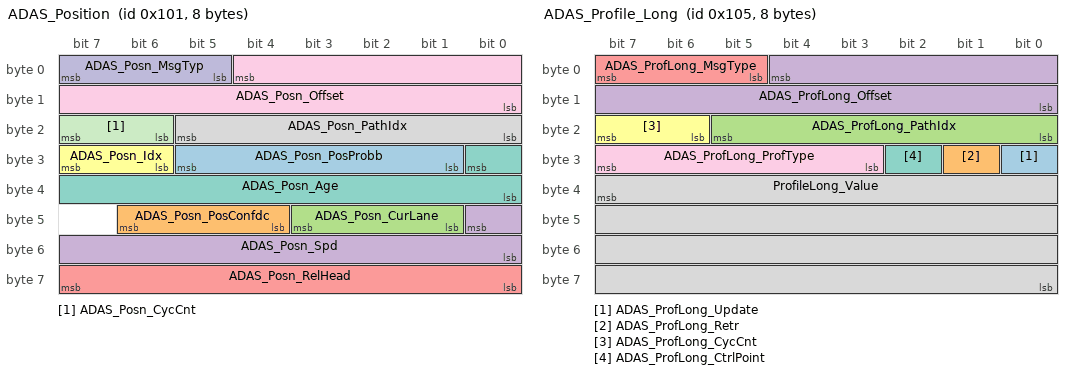
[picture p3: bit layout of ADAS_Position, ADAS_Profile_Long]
BO_ 257 ADAS_Position: 8 MGW
 SG_ ADAS_Posn_PosProbb : 29|5@0+ (3.333,0) [0|100] "%"  ADAS
 SG_ ADAS_Posn_PosConfdc : 46|3@0+ (1,0) [0|7] ""  ADAS
 SG_ ADAS_Posn_CurLane : 43|3@0+ (1,0) [0|7] ""  ADAS
 SG_ ADAS_Posn_Spd : 40|9@0+ (0.2,-12.8) [-12.8|89.2] "m/s"  ADAS
 SG_ ADAS_Posn_RelHead : 63|8@0+ (1.417,0) [0|358] "deg"  ADAS
 SG_ ADAS_Posn_Idx : 31|2@0+ (1,0) [0|3] ""  ADAS
 SG_ ADAS_Posn_Age : 24|9@0+ (5,0) [0|2545] "ms"  ADAS
 SG_ ADAS_Posn_PathIdx : 21|6@0+ (1,0) [8|63] ""  ADAS
 SG_ ADAS_Posn_Offset : 4|13@0+ (1,0) [0|8190] "m"  ADAS
 SG_ ADAS_Posn_MsgTyp : 7|3@0+ (1,0) [0|7] ""  ADAS
 SG_ ADAS_Posn_CycCnt : 23|2@0+ (1,0) [0|3] ""  ADAS

BO_ 261 ADAS_Profile_Long: 8 MGW
 SG_ ADAS_ProfLong_Update : 24|1@0+ (1,0) [0|1] ""  ADAS
 SG_ ADAS_ProfLong_Retr : 25|1@0+ (1,0) [0|1] ""  ADAS
 SG_ ADAS_ProfLong_PathIdx : 21|6@0+ (1,0) [8|63] ""  ADAS
 SG_ ADAS_ProfLong_Offset : 4|13@0+ (1,0) [0|8190] "m"  ADAS
 SG_ ADAS_ProfLong_MsgType : 7|3@0+ (1,0) [0|7] ""  ADAS
 SG_ ADAS_ProfLong_CycCnt : 23|2@0+ (1,0) [0|3] ""  ADAS
 SG_ ADAS_ProfLong_CtrlPoint : 26|1@0+ (1,0) [0|1] ""  ADAS
 SG_ ProfileLong_Value : 39|32@0+ (1,0) [0|4290000000] ""  ADAS
 SG_ ADAS_ProfLong_ProfType : 31|5@0+ (1,0) [0|31] ""  ADAS

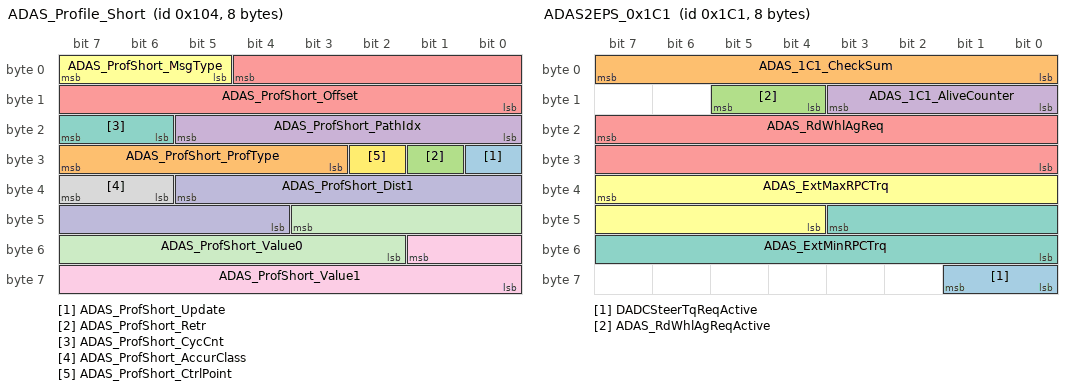
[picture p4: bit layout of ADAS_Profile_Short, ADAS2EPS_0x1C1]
BO_ 260 ADAS_Profile_Short: 8 MGW
 SG_ ADAS_ProfShort_Update : 24|1@0+ (1,0) [0|1] ""  ADAS
 SG_ ADAS_ProfShort_ProfType : 31|5@0+ (1,0) [0|31] ""  ADAS
 SG_ ADAS_ProfShort_Retr : 25|1@0+ (1,0) [0|1] ""  ADAS
 SG_ ADAS_ProfShort_PathIdx : 21|6@0+ (1,0) [8|63] ""  ADAS
 SG_ ADAS_ProfShort_Offset : 4|13@0+ (1,0) [0|8190] "m"  ADAS
 SG_ ADAS_ProfShort_MsgType : 7|3@0+ (1,0) [0|7] ""  ADAS
 SG_ ADAS_ProfShort_CycCnt : 23|2@0+ (1,0) [0|3] ""  ADAS
 SG_ ADAS_ProfShort_AccurClass : 39|2@0+ (1,0) [0|3] ""  ADAS
 SG_ ADAS_ProfShort_Value1 : 49|10@0+ (1,0) [0|1023] ""  ADAS
 SG_ ADAS_ProfShort_Dist1 : 37|10@0+ (1,0) [0|1022] "m"  ADAS
 SG_ ADAS_ProfShort_Value0 : 43|10@0+ (1,0) [0|1023] ""  ADAS
 SG_ ADAS_ProfShort_CtrlPoint : 26|1@0+ (1,0) [0|1] ""  ADAS

BO_ 258 ADAS_Segment: 8 MGW
 SG_ ADAS_Seg_PartOfCalcRoute : 47|2@0+ (1,0) [0|3] ""  ADAS
 SG_ ADAS_Seg_RelProbb : 39|5@0+ (3.333,0) [0|100] "%"  ADAS
 SG_ ADAS_Seg_Offset : 4|13@0+ (1,0) [0|8190] "m"  ADAS
 SG_ ADAS_Seg_Retr : 25|1@0+ (1,0) [0|1] ""  ADAS
 SG_ ADAS_Seg_PathIdx : 21|6@0+ (1,0) [8|63] ""  ADAS
 SG_ ADAS_Seg_MsgType : 7|3@0+ (1,0) [0|7] ""  ADAS
 SG_ ADAS_Seg_FormOfWay : 43|4@0+ (1,0) [0|14] ""  ADAS
 SG_ ADAS_Seg_CycCnt : 23|2@0+ (1,0) [0|3] ""  ADAS
 SG_ ADAS_Seg_CmplxInsct : 45|2@0+ (1,0) [0|3] ""  ADAS
 SG_ ADAS_Seg_BuildUpArea : 27|2@0+ (1,0) [0|3] ""  ADAS
 SG_ ADAS_Seg_DividedRoad : 62|2@0+ (1,0) [0|3] ""  ADAS
 SG_ ADAS_Seg_Bridge : 29|2@0+ (1,0) [0|3] ""  ADAS
 SG_ ADAS_Seg_Tunnel : 31|2@0+ (1,0) [0|3] ""  ADAS
 SG_ ADAS_Seg_NumOfLaneOppDir : 60|2@0+ (1,0) [0|3] ""  ADAS
 SG_ ADAS_Seg_NumOfLaneDrvDir : 58|3@0+ (1,0) [0|7] ""  ADAS
 SG_ ADAS_Seg_EffSpdLmtType : 50|3@0+ (1,0) [0|7] ""  ADAS
 SG_ ADAS_Seg_EffSpdLmt : 55|5@0+ (1,0) [0|255] "(k)mp/h"  ADAS
 SG_ ADAS_Seg_FuncRoadClass : 34|3@0+ (1,0) [0|6] ""  ADAS
 SG_ ADAS_Seg_Update : 24|1@0+ (1,0) [0|1] ""  ADAS

BO_ 259 ADAS_Stub: 8 MGW
 SG_ ADAS_Stub_PartOfCalcRoute : 47|2@0+ (1,0) [0|3] ""  ADAS
 SG_ ADAS_Stub_FuncRoadClass : 34|3@0+ (1,0) [0|6] ""  ADAS
 SG_ ADAS_Stub_LastStub : 63|1@0+ (1,0) [0|1] ""  ADAS
 SG_ ADAS_Stub_Update : 24|1@0+ (1,0) [0|1] ""  ADAS
 SG_ ADAS_Stub_SubPathIdx : 31|6@0+ (1,0) [8|63] ""  ADAS
 SG_ ADAS_Stub_Retr : 25|1@0+ (1,0) [0|1] ""  ADAS
 SG_ ADAS_Stub_PathIdx : 21|6@0+ (1,0) [8|63] ""  ADAS
 SG_ ADAS_Stub_Offset : 4|13@0+ (1,0) [0|8190] "m"  ADAS
 SG_ ADAS_Stub_NumOfLaneOppDir : 60|2@0+ (1,0) [0|3] ""  ADAS
 SG_ ADAS_Stub_NumOfLaneDrvDir : 58|3@0+ (1,0) [0|7] ""  ADAS
 SG_ ADAS_Stub_MsgType : 7|3@0+ (1,0) [0|7] ""  ADAS
 SG_ ADAS_Stub_FormOfWay : 43|4@0+ (1,0) [0|14] ""  ADAS
 SG_ ADAS_Stub_CycCnt : 23|2@0+ (1,0) [0|3] ""  ADAS
 SG_ ADAS_Stub_RtOfWay : 62|2@0+ (1,0) [0|3] ""  ADAS
 SG_ ADAS_Stub_CmplxInsct : 45|2@0+ (1,0) [0|3] ""  ADAS
 SG_ ADAS_Stub_RelProbb : 39|5@0+ (3.333,0) [0|100] "%"  ADAS
 SG_ ADAS_Stub_TurnAngl : 55|8@0+ (1.417,0) [0|358] "deg"  ADAS

BO_ 449 ADAS2EPS_0x1C1: 8 ADAS
 SG_ DADCSteerTqReqActive : 57|2@0+ (1,0) [0|3] ""  MGW
 SG_ ADAS_1C1_CheckSum : 7|8@0+ (1,0) [0|255] ""  MGW
 SG_ ADAS_RdWhlAgReqActive : 13|2@0+ (1,0) [0|3] ""  MGW
 SG_ ADAS_1C1_AliveCounter : 11|4@0+ (1,0) [0|15] ""  MGW
 SG_ ADAS_RdWhlAgReq : 23|16@0+ (0.005,-45) [-45|45] "degree"  MGW
 SG_ ADAS_ExtMaxRPCTrq : 39|12@0+ (0.02,-20.48) [-20.48|20.46] "Nm"  MGW
 SG_ ADAS_ExtMinRPCTrq : 43|12@0+ (0.02,-20.48) [-20.48|20.46] "Nm"  MGW

BO_ 272 ADASLong_Mux: 8 MGW
 SG_ ADASLONG_Mux_MsgTyp : 7|3@0+ (1,0) [0|7] ""  ADAS

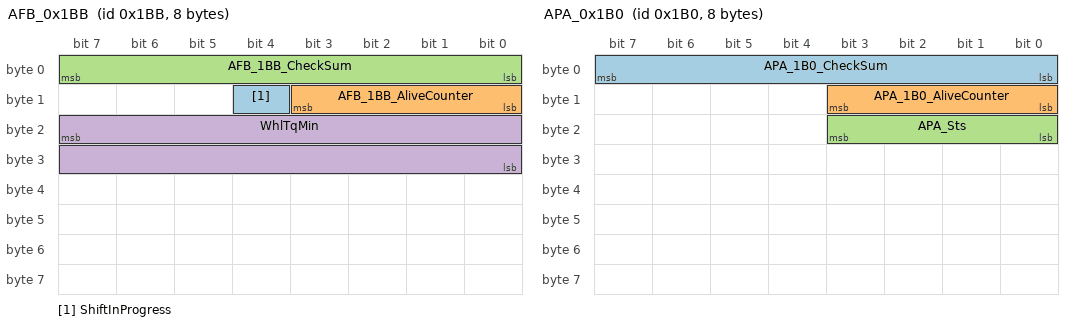
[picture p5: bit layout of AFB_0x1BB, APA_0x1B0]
BO_ 443 AFB_0x1BB: 8 MGW
 SG_ ShiftInProgress : 12|1@0+ (1,0) [0|1] ""  ADAS
 SG_ AFB_1BB_AliveCounter : 11|4@0+ (1,0) [0|14] ""  ADAS
 SG_ AFB_1BB_CheckSum : 7|8@0+ (1,0) [0|255] ""  ADAS
 SG_ WhlTqMin : 23|16@0+ (1,-32768) [-32768|32767] "Nm"  ADAS

BO_ 432 APA_0x1B0: 8 MGW
 SG_ APA_1B0_CheckSum : 7|8@0+ (1,0) [0|255] ""  ADAS
 SG_ APA_1B0_AliveCounter : 11|4@0+ (1,0) [0|14] ""  ADAS
 SG_ APA_Sts : 19|4@0+ (1,0) [0|15] ""  ADAS

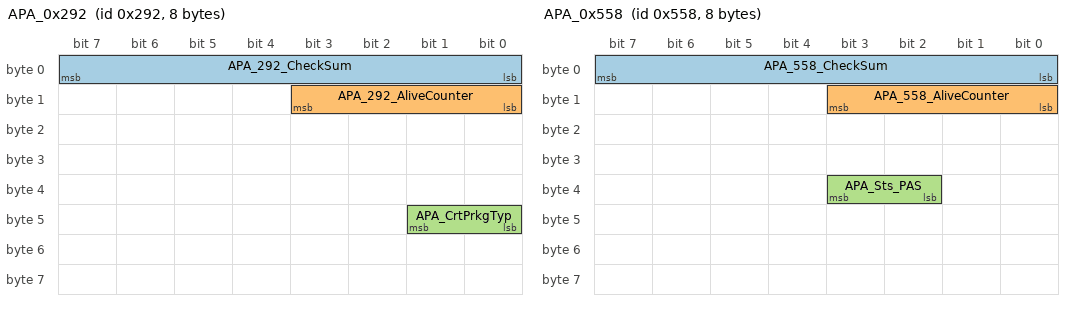
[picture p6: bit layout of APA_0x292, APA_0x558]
BO_ 658 APA_0x292: 8 MGW
 SG_ APA_292_CheckSum : 7|8@0+ (1,0) [0|255] ""  ADAS
 SG_ APA_292_AliveCounter : 11|4@0+ (1,0) [0|14] ""  ADAS
 SG_ APA_CrtPrkgTyp : 41|2@0+ (1,0) [0|3] ""  ADAS

BO_ 672 APA_0x2A0: 8 MGW
 SG_ APA_FMEBSts : 47|4@0+ (1,0) [0|15] ""  ADAS
 SG_ APA_RMEBSts : 53|4@0+ (1,0) [0|15] ""  ADAS

BO_ 1368 APA_0x558: 8 MGW
 SG_ APA_558_CheckSum : 7|8@0+ (1,0) [0|255] ""  ADAS
 SG_ APA_558_AliveCounter : 11|4@0+ (1,0) [0|14] ""  ADAS
 SG_ APA_Sts_PAS : 35|2@0+ (1,0) [0|3] ""  ADAS

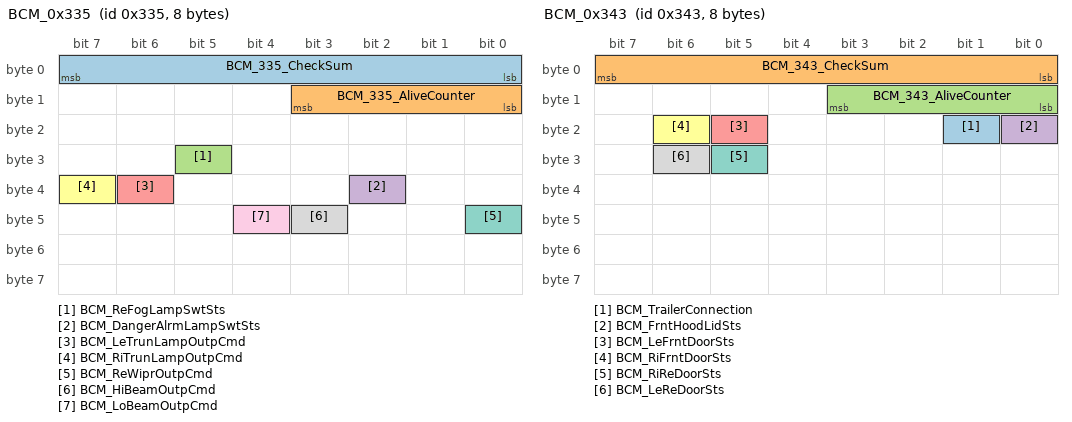
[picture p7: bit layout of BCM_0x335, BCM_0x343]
BO_ 821 BCM_0x335: 8 MGW
 SG_ BCM_335_CheckSum : 7|8@0+ (1,0) [0|255] ""  ADAS,FVC,CR_RL,CR_RR
 SG_ BCM_335_AliveCounter : 11|4@0+ (1,0) [0|14] ""  ADAS,FVC,CR_RL,CR_RR
 SG_ BCM_ReFogLampSwtSts : 29|1@0+ (1,0) [0|1] ""  ADAS,FVC
 SG_ BCM_DangerAlrmLampSwtSts : 34|1@0+ (1,0) [0|1] ""  ADAS
 SG_ BCM_LeTrunLampOutpCmd : 38|1@0+ (1,0) [0|1] ""  ADAS
 SG_ BCM_RiTrunLampOutpCmd : 39|1@0+ (1,0) [0|1] ""  ADAS
 SG_ BCM_ReWiprOutpCmd : 40|1@0+ (1,0) [0|1] ""  ADAS
 SG_ BCM_HiBeamOutpCmd : 43|1@0+ (1,0) [0|1] ""  ADAS,FVC
 SG_ BCM_LoBeamOutpCmd : 44|1@0+ (1,0) [0|1] ""  ADAS,FVC

BO_ 835 BCM_0x343: 8 MGW
 SG_ BCM_TrailerConnection : 17|1@0+ (1,0) [0|1] ""  ADAS
 SG_ BCM_343_CheckSum : 7|8@0+ (1,0) [0|255] ""  ADAS,CR_RL,CR_RR,FR_FC
 SG_ BCM_343_AliveCounter : 11|4@0+ (1,0) [0|14] ""  ADAS,CR_RL,CR_RR,FR_FC
 SG_ BCM_FrntHoodLidSts : 16|1@0+ (1,0) [0|1] ""  ADAS
 SG_ BCM_LeFrntDoorSts : 21|1@0+ (1,0) [0|1] ""  ADAS,CR_RL,FR_FC
 SG_ BCM_RiFrntDoorSts : 22|1@0+ (1,0) [0|1] ""  ADAS,CR_RR
 SG_ BCM_RiReDoorSts : 29|1@0+ (1,0) [0|1] ""  ADAS,CR_RR
 SG_ BCM_LeReDoorSts : 30|1@0+ (1,0) [0|1] ""  ADAS,CR_RL

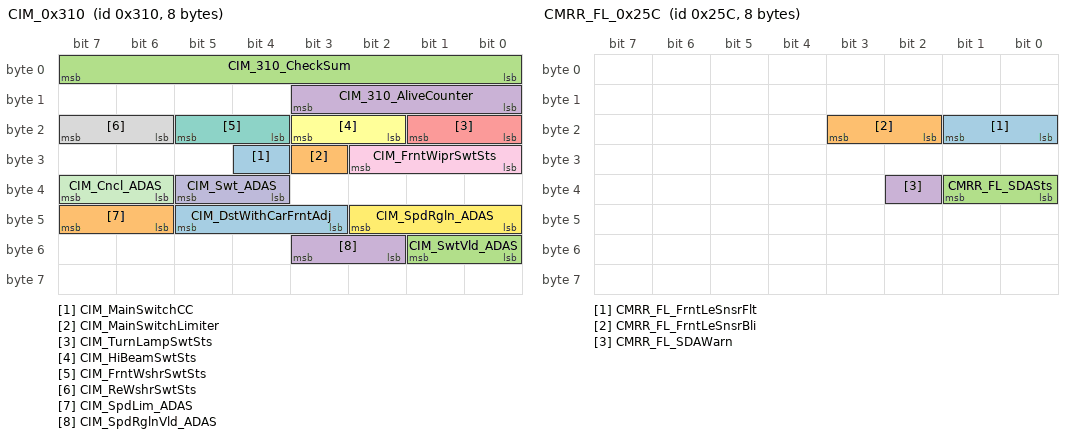
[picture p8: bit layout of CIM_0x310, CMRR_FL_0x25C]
BO_ 784 CIM_0x310: 8 MGW
 SG_ CIM_MainSwitchCC : 28|1@0+ (1,0) [0|1] ""  ADAS
 SG_ CIM_MainSwitchLimiter : 27|1@0+ (1,0) [0|1] ""  ADAS
 SG_ CIM_310_CheckSum : 7|8@0+ (1,0) [0|255] ""  ADAS,FVC,CR_RL,CR_RR,CR_FL,CR_FR,FR_FC
 SG_ CIM_310_AliveCounter : 11|4@0+ (1,0) [0|14] ""  ADAS,FVC,CR_RL,CR_RR,CR_FL,CR_FR,FR_FC
 SG_ CIM_TurnLampSwtSts : 17|2@0+ (1,0) [0|3] ""  ADAS,FVC,CR_RL,CR_RR,CR_FL,CR_FR,FR_FC
 SG_ CIM_HiBeamSwtSts : 19|2@0+ (1,0) [0|3] ""  ADAS,FVC
 SG_ CIM_FrntWshrSwtSts : 21|2@0+ (1,0) [0|3] ""  ADAS,FVC
 SG_ CIM_ReWshrSwtSts : 23|2@0+ (1,0) [0|3] ""  ADAS
 SG_ CIM_FrntWiprSwtSts : 26|3@0+ (1,0) [0|7] ""  ADAS,FVC
 SG_ CIM_Swt_ADAS : 37|2@0+ (1,0) [0|3] ""  ADAS
 SG_ CIM_Cncl_ADAS : 39|2@0+ (1,0) [0|3] ""  ADAS
 SG_ CIM_SpdRgln_ADAS : 42|3@0+ (1,0) [0|7] ""  ADAS
 SG_ CIM_DstWithCarFrntAdj : 45|3@0+ (1,0) [0|7] ""  ADAS
 SG_ CIM_SpdLim_ADAS : 47|2@0+ (1,0) [0|3] ""  ADAS,FVC
 SG_ CIM_SwtVld_ADAS : 49|2@0+ (1,0) [0|3] ""  ADAS
 SG_ CIM_SpdRglnVld_ADAS : 51|2@0+ (1,0) [0|3] ""  ADAS

BO_ 604 CMRR_FL_0x25C: 8 MGW
 SG_ CMRR_FL_FrntLeSnsrFlt : 17|2@0+ (1,0) [0|3] ""  ADAS
 SG_ CMRR_FL_FrntLeSnsrBli : 19|2@0+ (1,0) [0|3] ""  ADAS
 SG_ CMRR_FL_SDASts : 33|2@0+ (1,0) [0|3] ""  ADAS
 SG_ CMRR_FL_SDAWarn : 34|1@0+ (1,0) [0|1] ""  ADAS

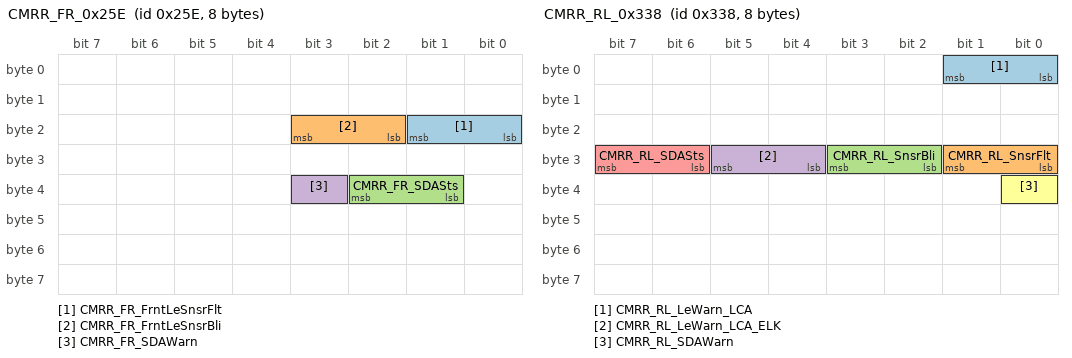
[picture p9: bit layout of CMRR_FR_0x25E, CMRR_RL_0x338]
BO_ 606 CMRR_FR_0x25E: 8 MGW
 SG_ CMRR_FR_FrntLeSnsrFlt : 17|2@0+ (1,0) [0|3] ""  ADAS
 SG_ CMRR_FR_FrntLeSnsrBli : 19|2@0+ (1,0) [0|3] ""  ADAS
 SG_ CMRR_FR_SDASts : 34|2@0+ (1,0) [0|3] ""  ADAS
 SG_ CMRR_FR_SDAWarn : 35|1@0+ (1,0) [0|1] ""  ADAS

BO_ 824 CMRR_RL_0x338: 8 MGW
 SG_ CMRR_RL_LeWarn_LCA : 1|2@0+ (1,0) [0|3] ""  ADAS
 SG_ CMRR_RL_SnsrFlt : 25|2@0+ (1,0) [0|3] ""  ADAS
 SG_ CMRR_RL_SnsrBli : 27|2@0+ (1,0) [0|3] ""  ADAS
 SG_ CMRR_RL_LeWarn_LCA_ELK : 29|2@0+ (1,0) [0|3] ""  ADAS
 SG_ CMRR_RL_SDASts : 31|2@0+ (1,0) [0|3] ""  ADAS
 SG_ CMRR_RL_SDAWarn : 32|1@0+ (1,0) [0|1] ""  ADAS

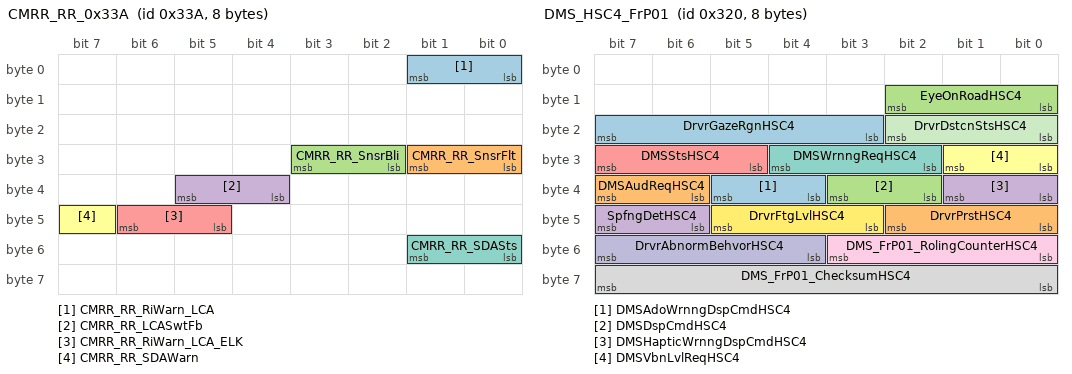
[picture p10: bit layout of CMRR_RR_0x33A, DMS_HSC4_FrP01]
BO_ 826 CMRR_RR_0x33A: 8 MGW
 SG_ CMRR_RR_RiWarn_LCA : 1|2@0+ (1,0) [0|3] ""  ADAS
 SG_ CMRR_RR_SnsrFlt : 25|2@0+ (1,0) [0|3] ""  ADAS
 SG_ CMRR_RR_SnsrBli : 27|2@0+ (1,0) [0|3] ""  ADAS
 SG_ CMRR_RR_LCASwtFb : 37|2@0+ (1,0) [0|3] ""  ADAS
 SG_ CMRR_RR_RiWarn_LCA_ELK : 46|2@0+ (1,0) [0|3] ""  ADAS
 SG_ CMRR_RR_SDAWarn : 47|1@0+ (1,0) [0|1] ""  ADAS
 SG_ CMRR_RR_SDASts : 49|2@0+ (1,0) [0|3] ""  ADAS

BO_ 1958 Diag_ADAS_Req: 64 ADAS

BO_ 1966 Diag_ADAS_Resp: 64 ADAS

BO_ 800 DMS_HSC4_FrP01: 8 DMS
 SG_ DMSAdoWrnngDspCmdHSC4 : 37|2@0+ (1,0) [0|3] ""  ADAS
 SG_ DMSAudReqHSC4 : 39|2@0+ (1,0) [0|3] ""  ADAS
 SG_ DMSDspCmdHSC4 : 35|2@0+ (1,0) [0|3] ""  ADAS
 SG_ DMSHapticWrnngDspCmdHSC4 : 33|2@0+ (1,0) [0|3] ""  ADAS
 SG_ DMSStsHSC4 : 31|3@0+ (1,0) [0|7] ""  ADAS
 SG_ DMSVbnLvlReqHSC4 : 25|2@0+ (1,0) [0|3] ""  ADAS
 SG_ DMSWrnngReqHSC4 : 28|3@0+ (1,0) [0|7] ""  ADAS
 SG_ DMS_FrP01_ChecksumHSC4 : 63|8@0+ (1,0) [0|255] ""  ADAS
 SG_ DMS_FrP01_RolingCounterHSC4 : 51|4@0+ (1,0) [0|15] "count value"  ADAS
 SG_ DrvrAbnormBehvorHSC4 : 55|4@0+ (1,0) [0|15] ""  ADAS
 SG_ DrvrDstcnStsHSC4 : 18|3@0+ (1,0) [0|7] ""  ADAS
 SG_ DrvrFtgLvlHSC4 : 45|3@0+ (1,0) [0|7] ""  ADAS
 SG_ DrvrGazeRgnHSC4 : 23|5@0+ (1,0) [0|31] ""  ADAS
 SG_ DrvrPrstHSC4 : 42|3@0+ (1,0) [0|7] ""  ADAS
 SG_ EyeOnRoadHSC4 : 10|3@0+ (1,0) [0|7] ""  ADAS
 SG_ SpfngDetHSC4 : 47|2@0+ (1,0) [0|3] ""  ADAS

BO_ 883 ECC_0x373: 8 MGW
 SG_ ECC_OutdT : 47|8@0+ (0.5,-48) [-48|79.5] "degree celsius"  ADAS,FVC,CR_RL,CR_RR,CR_FL,CR_FR,FR_FC
 SG_ ECC_OutdTVld : 49|2@0+ (1,0) [0|3] ""  ADAS,FVC,CR_RL,CR_RR,CR_FL,CR_FR,FR_FC

BO_ 1410 ECC_0x582: 8 MGW
 SG_ ECC_InsdT : 7|8@0+ (0.5,-48) [-48|79] "degree celsius"  ADAS

BO_ 1228 EHR_Ego_Lane_Info1_0x4CC: 48 MAP
 SG_ Ego_Lane_Info1_CRC : 0|16@1+ (1,0) [0|65535] ""  ADAS
 SG_ Ego_Lane_Info1_AliveCtr : 16|8@1+ (1,0) [0|255] ""  ADAS
 SG_ Ego_Lane_Info1_TimeStamp : 24|20@1+ (0.00065536,0) [0|687.194112] "s"  ADAS
 SG_ Ego_Lane_Map_Status : 44|2@1+ (1,0) [0|1] ""  ADAS
 SG_ Ego_Lane_CurrentSpeedLimit : 46|5@1+ (5,0) [0|130] "km/h"  ADAS
 SG_ Ego_Lane_CurrentSpeedLimit_Type : 51|2@1+ (1,0) [0|3] ""  ADAS
 SG_ Ego_Lane_NextSpeedLimit_Value_1 : 53|5@1+ (5,0) [0|130] "km/h"  ADAS
 SG_ Ego_Lane_NextSpeedLimit_Loc_1 : 58|12@1+ (1,0) [0|4000] "m"  ADAS
 SG_ Ego_Lane_NextSpeedLimit_Type_1 : 70|2@1+ (1,0) [0|3] ""  ADAS
 SG_ Ego_Lane_NextSpeedLimit_Value_2 : 72|5@1+ (5,0) [0|130] "km/h"  ADAS
 SG_ Ego_Lane_NextSpeedLimit_Loc_2 : 77|12@1+ (1,0) [0|4000] "m"  ADAS
 SG_ Ego_Lane_NextSpeedLimit_Type_2 : 89|2@1+ (1,0) [0|3] ""  ADAS
 SG_ Ego_Lane_NextSpeedLimit_Value_3 : 91|5@1+ (5,0) [0|130] "km/h"  ADAS
 SG_ Ego_Lane_NextSpeedLimit_Loc_3 : 96|12@1+ (1,0) [0|4000] "m"  ADAS
 SG_ Ego_Lane_NextSpeedLimit_Type_3 : 108|2@1+ (1,0) [0|3] ""  ADAS
 SG_ Ego_Lane_NextSpeedLimit_Value_4 : 110|5@1+ (5,0) [0|130] "km/h"  ADAS
 SG_ Ego_Lane_NextSpeedLimit_Loc_4 : 115|12@1+ (1,0) [0|4000] "m"  ADAS
 SG_ Ego_Lane_NextSpeedLimit_Type_4 : 127|2@1+ (1,0) [0|3] ""  ADAS
 SG_ Ego_Lane_NextTopoLocation_1 : 129|11@1+ (1,0) [0|2000] "m"  ADAS
 SG_ Ego_Lane_NextTopoType_1 : 140|3@1+ (1,0) [0|6] ""  ADAS
 SG_ Ego_Lane_NextTopoSide_1 : 143|1@1+ (1,0) [0|1] ""  ADAS
 SG_ Ego_Lane_NextTopoLocation_2 : 144|11@1+ (1,0) [0|2000] "m"  ADAS
 SG_ Ego_Lane_NextTopoType_2 : 155|3@1+ (1,0) [0|6] ""  ADAS
 SG_ Ego_Lane_NextTopoSide_2 : 158|1@1+ (1,0) [0|1] ""  ADAS
 SG_ Ego_Lane_NextTopoLocation_3 : 159|11@1+ (1,0) [0|2000] "m"  ADAS
 SG_ Ego_Lane_NextTopoType_3 : 170|3@1+ (1,0) [0|6] ""  ADAS
 SG_ Ego_Lane_NextTopoSide_3 : 173|1@1+ (1,0) [0|1] ""  ADAS
 SG_ Ego_Lane_NextTopoLocation_4 : 174|11@1+ (1,0) [0|2000] "m"  ADAS
 SG_ Ego_Lane_NextTopoType_4 : 185|3@1+ (1,0) [0|6] ""  ADAS
 SG_ Ego_Lane_NextTopoSide_4 : 188|1@1+ (1,0) [0|1] ""  ADAS
 SG_ Ego_Lane_CurrBoundary_Type_R : 189|5@1+ (1,0) [0|19] ""  ADAS
 SG_ Ego_Lane_NextBoundary_Loc_R_1 : 194|11@1+ (1,0) [0|2000] "m"  ADAS
 SG_ Ego_Lane_NextBoundary_Type_R_1 : 205|5@1+ (1,0) [0|19] ""  ADAS
 SG_ Ego_Lane_NextBoundary_Loc_R_2 : 210|11@1+ (1,0) [0|2000] "m"  ADAS
 SG_ Ego_Lane_NextBoundary_Type_R_2 : 221|5@1+ (1,0) [0|19] ""  ADAS
 SG_ Ego_Lane_NextBoundary_Loc_R_3 : 226|11@1+ (1,0) [0|2000] "m"  ADAS
 SG_ Ego_Lane_NextBoundary_Type_R_3 : 237|5@1+ (1,0) [0|19] ""  ADAS
 SG_ Ego_Lane_NextBoundary_Loc_R_4 : 242|11@1+ (1,0) [0|2000] "m"  ADAS
 SG_ Ego_Lane_NextBoundary_Type_R_4 : 253|5@1+ (1,0) [0|19] ""  ADAS
 SG_ Ego_Lane_CurrBoundary_Type_L : 258|5@1+ (1,0) [0|19] ""  ADAS
 SG_ Ego_Lane_NextBoundary_Loc_L_1 : 263|11@1+ (1,0) [0|2000] "m"  ADAS
 SG_ Ego_Lane_NextBoundary_Type_L_1 : 274|5@1+ (1,0) [0|19] ""  ADAS
 SG_ Ego_Lane_NextBoundary_Loc_L_2 : 279|11@1+ (1,0) [0|2000] "m"  ADAS
 SG_ Ego_Lane_NextBoundary_Type_L_2 : 290|5@1+ (1,0) [0|19] ""  ADAS
 SG_ Ego_Lane_NextBoundary_Loc_L_3 : 295|11@1+ (1,0) [0|2000] "m"  ADAS
 SG_ Ego_Lane_NextBoundary_Type_L_3 : 306|5@1+ (1,0) [0|19] ""  ADAS
 SG_ Ego_Lane_NextBoundary_Loc_L_4 : 311|11@1+ (1,0) [0|2000] "m"  ADAS
 SG_ Ego_Lane_NextBoundary_Type_L_4 : 322|5@1+ (1,0) [0|19] ""  ADAS

BO_ 1229 EHR_Ego_Lane_Info2_0x4CD: 64 MAP
 SG_ Ego_Lane_Info2_CRC : 0|16@1+ (1,0) [0|65535] ""  ADAS
 SG_ Ego_Lane_Info2_AliveCtr : 16|8@1+ (1,0) [0|255] ""  ADAS
 SG_ Ego_Lane_Info2_TimeStamp : 24|20@1+ (0.00065536,0) [0|687.194112] "s"  ADAS
 SG_ Ego_Lane_SpeedProfile_Near_N : 44|5@1+ (1,0) [0|31] ""  ADAS
 SG_ Ego_Lane_SpeedProfile_Near_00 : 49|7@1+ (2,0) [0|200] "km/h"  ADAS
 SG_ Ego_Lane_SpeedProfile_Near_01 : 56|7@1+ (2,0) [0|200] "km/h"  ADAS
 SG_ Ego_Lane_SpeedProfile_Near_02 : 63|7@1+ (2,0) [0|200] "km/h"  ADAS
 SG_ Ego_Lane_SpeedProfile_Near_03 : 70|7@1+ (2,0) [0|200] "km/h"  ADAS
 SG_ Ego_Lane_SpeedProfile_Near_04 : 77|7@1+ (2,0) [0|200] "km/h"  ADAS
 SG_ Ego_Lane_SpeedProfile_Near_05 : 84|7@1+ (2,0) [0|200] "km/h"  ADAS
 SG_ Ego_Lane_SpeedProfile_Near_06 : 91|7@1+ (2,0) [0|200] "km/h"  ADAS
 SG_ Ego_Lane_SpeedProfile_Near_07 : 98|7@1+ (2,0) [0|200] "km/h"  ADAS
 SG_ Ego_Lane_SpeedProfile_Near_08 : 105|7@1+ (2,0) [0|200] "km/h"  ADAS
 SG_ Ego_Lane_SpeedProfile_Near_09 : 112|7@1+ (2,0) [0|200] "km/h"  ADAS
 SG_ Ego_Lane_SpeedProfile_Near_10 : 119|7@1+ (2,0) [0|200] "km/h"  ADAS
 SG_ Ego_Lane_SpeedProfile_Near_11 : 126|7@1+ (2,0) [0|200] "km/h"  ADAS
 SG_ Ego_Lane_SpeedProfile_Near_12 : 133|7@1+ (2,0) [0|200] "km/h"  ADAS
 SG_ Ego_Lane_SpeedProfile_Near_13 : 140|7@1+ (2,0) [0|200] "km/h"  ADAS
 SG_ Ego_Lane_SpeedProfile_Near_14 : 147|7@1+ (2,0) [0|200] "km/h"  ADAS
 SG_ Ego_Lane_SpeedProfile_Near_15 : 154|7@1+ (2,0) [0|200] "km/h"  ADAS
 SG_ Ego_Lane_SpeedProfile_Near_16 : 161|7@1+ (2,0) [0|200] "km/h"  ADAS
 SG_ Ego_Lane_SpeedProfile_Near_17 : 168|7@1+ (2,0) [0|200] "km/h"  ADAS
 SG_ Ego_Lane_SpeedProfile_Near_18 : 175|7@1+ (2,0) [0|200] "km/h"  ADAS
 SG_ Ego_Lane_SpeedProfile_Near_19 : 182|7@1+ (2,0) [0|200] "km/h"  ADAS
 SG_ Ego_Lane_SpeedProfile_Near_20 : 189|7@1+ (2,0) [0|200] "km/h"  ADAS
 SG_ Ego_Lane_SpeedProfile_Near_21 : 196|7@1+ (2,0) [0|200] "km/h"  ADAS
 SG_ Ego_Lane_SpeedProfile_Near_22 : 203|7@1+ (2,0) [0|200] "km/h"  ADAS
 SG_ Ego_Lane_SpeedProfile_Far_N : 210|5@1+ (1,0) [0|31] ""  ADAS
 SG_ Ego_Lane_SpeedProfile_Far_00 : 215|7@1+ (2,0) [0|200] "km/h"  ADAS
 SG_ Ego_Lane_SpeedProfile_Far_01 : 222|7@1+ (2,0) [0|200] "km/h"  ADAS
 SG_ Ego_Lane_SpeedProfile_Far_02 : 229|7@1+ (2,0) [0|200] "km/h"  ADAS
 SG_ Ego_Lane_SpeedProfile_Far_03 : 236|7@1+ (2,0) [0|200] "km/h"  ADAS
 SG_ Ego_Lane_SpeedProfile_Far_04 : 243|7@1+ (2,0) [0|200] "km/h"  ADAS
 SG_ Ego_Lane_SpeedProfile_Far_05 : 250|7@1+ (2,0) [0|200] "km/h"  ADAS
 SG_ Ego_Lane_SpeedProfile_Far_06 : 257|7@1+ (2,0) [0|200] "km/h"  ADAS
 SG_ Ego_Lane_SpeedProfile_Far_07 : 264|7@1+ (2,0) [0|200] "km/h"  ADAS
 SG_ Ego_Lane_SpeedProfile_Far_08 : 271|7@1+ (2,0) [0|200] "km/h"  ADAS
 SG_ Ego_Lane_SpeedProfile_Far_09 : 278|7@1+ (2,0) [0|200] "km/h"  ADAS
 SG_ Ego_Lane_SpeedProfile_Far_10 : 285|7@1+ (2,0) [0|200] "km/h"  ADAS
 SG_ Ego_Lane_SpeedProfile_Far_11 : 292|7@1+ (2,0) [0|200] "km/h"  ADAS
 SG_ Ego_Lane_SpeedProfile_Far_12 : 299|7@1+ (2,0) [0|200] "km/h"  ADAS
 SG_ Ego_Lane_SpeedProfile_Far_13 : 306|7@1+ (2,0) [0|200] "km/h"  ADAS
 SG_ Ego_Lane_SpeedProfile_Far_14 : 313|7@1+ (2,0) [0|200] "km/h"  ADAS
 SG_ Ego_Lane_SpeedProfile_Far_15 : 320|7@1+ (2,0) [0|200] "km/h"  ADAS
 SG_ Ego_Lane_SpeedProfile_Far_16 : 327|7@1+ (2,0) [0|200] "km/h"  ADAS
 SG_ Ego_Lane_NextHotspot_Type_1 : 334|3@1+ (1,0) [0|3] ""  ADAS
 SG_ Ego_Lane_NextHotspot_Loc_1 : 337|11@1+ (1,0) [0|2000] "m"  ADAS
 SG_ Ego_Lane_NextHotspot_Length_1 : 348|8@1+ (10,0) [0|2000] "m"  ADAS
 SG_ Ego_Lane_NextHotspot_Int_1 : 356|6@1+ (0.015873,0) [0|1] ""  ADAS
 SG_ Ego_Lane_NextHotspot_Prob_1 : 362|8@1+ (0.00392157,0) [0|1] ""  ADAS
 SG_ Ego_Lane_NextHotspot_Side_1 : 370|1@1+ (1,0) [0|1] ""  ADAS
 SG_ Ego_Lane_NextHotspot_Type_2 : 371|3@1+ (1,0) [0|3] ""  ADAS
 SG_ Ego_Lane_NextHotspot_Loc_2 : 374|11@1+ (1,0) [0|2000] "m"  ADAS
 SG_ Ego_Lane_NextHotspot_Length_2 : 385|8@1+ (10,0) [0|2000] "m"  ADAS
 SG_ Ego_Lane_NextHotspot_Int_2 : 393|6@1+ (0.015873,0) [0|1] ""  ADAS
 SG_ Ego_Lane_NextHotspot_Prob_2 : 399|8@1+ (0.00392157,0) [0|1] ""  ADAS
 SG_ Ego_Lane_NextHotspot_Side_2 : 407|1@1+ (1,0) [0|1] ""  ADAS
 SG_ Ego_Lane_NextHotspot_Type_3 : 408|3@1+ (1,0) [0|3] ""  ADAS
 SG_ Ego_Lane_NextHotspot_Loc_3 : 411|11@1+ (1,0) [0|2000] "m"  ADAS
 SG_ Ego_Lane_NextHotspot_Length_3 : 422|8@1+ (10,0) [0|2000] "m"  ADAS
 SG_ Ego_Lane_NextHotspot_Int_3 : 430|6@1+ (0.015873,0) [0|1] ""  ADAS
 SG_ Ego_Lane_NextHotspot_Prob_3 : 436|8@1+ (0.00392157,0) [0|1] ""  ADAS
 SG_ Ego_Lane_NextHotspot_Side_3 : 444|1@1+ (1,0) [0|1] ""  ADAS
 SG_ Ego_Lane_NextHotspot_Type_4 : 445|3@1+ (1,0) [0|3] ""  ADAS
 SG_ Ego_Lane_NextHotspot_Loc_4 : 448|11@1+ (1,0) [0|2000] "m"  ADAS
 SG_ Ego_Lane_NextHotspot_Length_4 : 459|8@1+ (10,0) [0|2000] "m"  ADAS
 SG_ Ego_Lane_NextHotspot_Int_4 : 467|6@1+ (0.015873,0) [0|1] ""  ADAS
 SG_ Ego_Lane_NextHotspot_Prob_4 : 473|8@1+ (0.00392157,0) [0|1] ""  ADAS
 SG_ Ego_Lane_NextHotspot_Side_4 : 481|1@1+ (1,0) [0|1] ""  ADAS

BO_ 1230 EHR_Left_Lane_info_0x4CE: 48 MAP
 SG_ Left_Lane_Info_CRC : 0|16@1+ (1,0) [0|65535] ""  ADAS
 SG_ Left_Lane_Info_AliveCtr : 16|8@1+ (1,0) [0|255] ""  ADAS
 SG_ Left_Lane_Info_TimeStamp : 24|20@1+ (0.00065536,0) [0|687.194112] "s"  ADAS
 SG_ Left_Lane_Exists : 44|1@1+ (1,0) [0|1] ""  ADAS
 SG_ Left_Lane_isOvertakeLane : 45|1@1+ (1,0) [0|1] ""  ADAS
 SG_ Left_Lane_Start_dx : 46|12@1+ (1,0) [0|4000] ""  ADAS
 SG_ Left_CurrentSpeedLimit : 58|5@1+ (5,0) [0|130] "km/h"  ADAS
 SG_ Left_CurrentSpeedLimit_Type : 63|2@1+ (1,0) [0|3] ""  ADAS
 SG_ Left_NextSpeedLimit_Value_1 : 65|5@1+ (5,0) [0|130] "km/h"  ADAS
 SG_ Left_NextSpeedLimit_Location_1 : 70|12@1+ (1,0) [0|4000] "m"  ADAS
 SG_ Left_NextSpeedLimit_Type_1 : 82|2@1+ (1,0) [0|3] ""  ADAS
 SG_ Left_NextSpeedLimit_Value_2 : 84|5@1+ (5,0) [0|130] "km/h"  ADAS
 SG_ Left_NextSpeedLimit_Location_2 : 89|12@1+ (1,0) [0|4000] "m"  ADAS
 SG_ Left_NextSpeedLimit_Type_2 : 101|2@1+ (1,0) [0|3] ""  ADAS
 SG_ Left_NextSpeedLimit_Value_3 : 103|5@1+ (5,0) [0|130] "km/h"  ADAS
 SG_ Left_NextSpeedLimit_Location_3 : 108|12@1+ (1,0) [0|4000] "m"  ADAS
 SG_ Left_NextSpeedLimit_Type_3 : 120|2@1+ (1,0) [0|3] ""  ADAS
 SG_ Left_NextSpeedLimit_Value_4 : 122|5@1+ (5,0) [0|130] "km/h"  ADAS
 SG_ Left_NextSpeedLimit_Location_4 : 127|12@1+ (1,0) [0|4000] "m"  ADAS
 SG_ Left_NextSpeedLimit_Type_4 : 139|2@1+ (1,0) [0|3] ""  ADAS
 SG_ Left_SpeedProfile_Far_N : 141|5@1+ (1,0) [0|31] ""  ADAS
 SG_ Left_SpeedProfile_Far_00 : 146|7@1+ (2,0) [0|200] "km/h"  ADAS
 SG_ Left_SpeedProfile_Far_01 : 153|7@1+ (2,0) [0|200] "km/h"  ADAS
 SG_ Left_SpeedProfile_Far_02 : 160|7@1+ (2,0) [0|200] "km/h"  ADAS
 SG_ Left_SpeedProfile_Far_03 : 167|7@1+ (2,0) [0|200] "km/h"  ADAS
 SG_ Left_SpeedProfile_Far_04 : 174|7@1+ (2,0) [0|200] "km/h"  ADAS
 SG_ Left_SpeedProfile_Far_05 : 181|7@1+ (2,0) [0|200] "km/h"  ADAS
 SG_ Left_SpeedProfile_Far_06 : 188|7@1+ (2,0) [0|200] "km/h"  ADAS
 SG_ Left_SpeedProfile_Far_07 : 195|7@1+ (2,0) [0|200] "km/h"  ADAS
 SG_ Left_SpeedProfile_Far_08 : 202|7@1+ (2,0) [0|200] "km/h"  ADAS
 SG_ Left_SpeedProfile_Far_09 : 209|7@1+ (2,0) [0|200] "km/h"  ADAS
 SG_ Left_SpeedProfile_Far_10 : 216|7@1+ (2,0) [0|200] "km/h"  ADAS
 SG_ Left_SpeedProfile_Far_11 : 223|7@1+ (2,0) [0|200] "km/h"  ADAS
 SG_ Left_SpeedProfile_Far_12 : 230|7@1+ (2,0) [0|200] "km/h"  ADAS
 SG_ Left_SpeedProfile_Far_13 : 237|7@1+ (2,0) [0|200] "km/h"  ADAS
 SG_ Left_SpeedProfile_Far_14 : 244|7@1+ (2,0) [0|200] "km/h"  ADAS
 SG_ Left_SpeedProfile_Far_15 : 251|7@1+ (2,0) [0|200] "km/h"  ADAS
 SG_ Left_SpeedProfile_Far_16 : 258|7@1+ (2,0) [0|200] "km/h"  ADAS
 SG_ Left_NextTopo_Loc_1 : 265|11@1+ (1,0) [0|2000] "m"  ADAS
 SG_ Left_NextTopo_Type_1 : 276|3@1+ (1,0) [0|6] ""  ADAS
 SG_ Left_NextTopo_Side_1 : 279|1@1+ (1,0) [0|1] ""  ADAS
 SG_ Left_NextTopo_Loc_2 : 280|11@1+ (1,0) [0|2000] "m"  ADAS
 SG_ Left_NextTopo_Type_2 : 291|3@1+ (1,0) [0|6] ""  ADAS
 SG_ Left_NextTopo_Side_2 : 294|1@1+ (1,0) [0|1] ""  ADAS
 SG_ Left_NextTopo_Loc_3 : 295|11@1+ (1,0) [0|2000] "m"  ADAS
 SG_ Left_NextTopo_Type_3 : 306|3@1+ (1,0) [0|6] ""  ADAS
 SG_ Left_NextTopo_Side_3 : 309|1@1+ (1,0) [0|1] ""  ADAS
 SG_ Left_NextTopo_Loc_4 : 310|11@1+ (1,0) [0|2000] "m"  ADAS
 SG_ Left_NextTopo_Type_4 : 321|3@1+ (1,0) [0|6] ""  ADAS
 SG_ Left_NextTopo_Side_4 : 324|1@1+ (1,0) [0|1] ""  ADAS

BO_TX_BU_ 1970 : MGW,FVC;

CM_ "dbc based on BJEV ADAS-CANFD (BJEV_N60AB(EP2)_ADASBUS_V2.2_ODS)";
CM_ BU_ IMU_MMP2 "Additional reference inertial sensor Bosch MMP2";
CM_ BU_ MAP "HD map data from MAP PC (for Geofence, Centerline)";
CM_ BU_ DMS "Driver Monitoring Sensor
only for Golf architecture, for Defender DMS is on HMI-CANFD over MGW";
CM_ BU_ VIC "Visualization Computer
only for Golf architecture, for Defender VIC is on HMI-CANFD over MGW";
CM_ BU_ GWS "Gateway Safety (AEB GW on Golf)";
CM_ BU_ MGW "Mapping Gateway between vehicle and ADAS layer";
CM_ BU_ ADAS "DASy";
CM_ BU_ FVC "Front Video Camera - MPC3/SVC3";
CM_ BU_ CR_RL "Corner Radar - Rear Left";
CM_ BU_ CR_RR "Corner Radar - Rear Right";
CM_ BU_ CR_FL "Corner Radar - Front Left";
CM_ BU_ CR_FR "Corner Radar - Front Right";
CM_ BU_ FR_FC "Front Radar - Front Center";
CM_ BO_ 1970 "8 byte short commit ID from Video: converted ASCII Text String, written in little-endian byte order (Intel)
Byte order has to be reversed when converting HEX bytes to ASCII";
CM_ BO_ 1983 "Version information of the interface. e. g. version 1.0: Major = 1. ISO 23150:2022(E): Interface version ID {major, minor, patch} (A.1.1)";
CM_ SG_ 1983 DBC_VersionIdMinor "Version information of the interface. e. g. version 1.0: Major = 1. ISO 23150:2022(E): Interface version ID {major, minor, patch} (A.1.1)";
CM_ SG_ 1983 DBC_VersionIdMajor "Version information of the interface. e. g. version 1.0: Major = 1. ISO 23150:2022(E): Interface version ID {major, minor, patch} (A.1.1)";
CM_ BO_ 1969 "12 byte short commit ID from Front Radar: converted ASCII Text String, written in little-endian byte order (Intel)
Byte order has to be reversed when converting HEX bytes to ASCII";
CM_ BO_ 1968 "12 byte short commit ID from DASy: converted ASCII Text String, written in little-endian byte order (Intel)
Byte order has to be reversed when converting HEX bytes to ASCII";
CM_ BO_ 1793 "Fleabox communication to DASy to set up communication, uses AUTOSAR CAN Transport Layer";
CM_ BO_ 1792 "DASy field data collection for Fleabox, uses AUTOSAR CAN Transport Layer";
CM_ BO_ 30 "TimeSync for Sensors on public CAN (MGW is Master)";
CM_ SG_ 30 TimeSync_Type "Multiplexer: 0x20 = SYNC with CRC, 0x28 = FUP with CRC, 0x10 = SYNC, 0x18 = FUP";
CM_ SG_ 30 TimeSync_CRC "CRC calculation: AUTOSAR_SWS_CRCLibrary.pdf number 490
10, 90, 149, 154, 192, 228, 12, 92, 225, 93, 230, 6, 173, 5, 236, 55";
CM_ SG_ 30 TimeSync_SequenceCounter "SC = Sequence Counter";
CM_ SG_ 30 TimeSync_TimeDomain "Time Domain 0 to 15";
CM_ SG_ 30 TimeSync_UserByte0 "UserByte0";
CM_ SG_ 30 TimeSync_SyncTimeSec "SyncTime: seconds";
CM_ SG_ 30 TimeSync_OverflowOfSeconds "OVS = Overflow of seconds, must be added to SyncTimeSec";
CM_ SG_ 30 TimeSync_SGW "SyncToGTM = 0
SyncToSubDomain = 1";
CM_ SG_ 30 TimeSync_Reserved0 "FUP Byte3: Bit7 to Bit3 reserved area";
CM_ SG_ 30 TimeSync_SyncTimeNSec "SyncTime: nanoseconds";
CM_ BO_ 1225 "MAP info for HF and BDA";
CM_ SG_ 1225 EHR_LOC_Status "Init state, Active state, etc.";
CM_ SG_ 1225 EHR_LOC_POSE_YAW "Localization yaw angle (heading)";
CM_ SG_ 1225 EHR_LOC_POSE_LONG "Localization position coordinate longitude";
CM_ SG_ 1225 EHR_LOC_POSE_LAT "Localization position coordinate latitude";
CM_ BO_ 1224 "MAP info for HF and BDA";
CM_ SG_ 1224 EHR_GNSS_Stddev_long "GNSS receiver expected error of longitude";
CM_ SG_ 1224 EHR_GNSS_Stddev_lat "GNSS receiver expected error of latitude";
CM_ SG_ 1224 EHR_GNSS_POS_LONG "Raw GNSS Position coordinate longitude from ADMA";
CM_ SG_ 1224 EHR_GNSS_POS_LAT "Raw GNSS Position coordinate latitude from ADMA";
CM_ BO_ 1441 "VIC status - computer and docker for visualization (Safety concept)";
CM_ SG_ 1441 VIC_Status "VIC availability for feedback to Safety GW (MGW)  for AEB enabling";
CM_ SG_ 1441 VIC_Status_5A1_Alivecounter "Alivecounter VIC_Status_5A1 E2E profile02";
CM_ SG_ 1441 VIC_Status_5A1_Checksum "Checksum VIC_Status_5A1 Autosar E2E profile 2 DataID=0";
CM_ BO_ 1440 "AEB status - for visualization on cluster intrument (Safety concept)";
CM_ SG_ 1440 AEB_Status "AEB availability for visualization on HMI (over VIC)";
CM_ SG_ 1440 AEB_Status_5A0_Alivecounter "Alivecounter AEB_Status_5A0 E2E profile02";
CM_ SG_ 1440 AEB_Status_0x5A0_Checksum "Checksum AEB_Status_0x5A0 Autosar E2E profile 2 DataID=0";
CM_ BO_ 1791 "Variant coding Golf or Defender";
CM_ SG_ 1791 Vehicle_Variant "Type of vehicle - signal defined in MGW or HASy";
CM_ BO_ 291 "Longitudinal actuation request DASy to brake (ACC and LIM interfaces)
TBD if rename of message to a more apropriate name, e.g. ADAS_VMC_Long";
CM_ SG_ 291 ADAS_VehSecureReq "Request to secure the vehicle activating the park brake after comming in standstill
Mapped to JLR Flexray::DADCVehSecureReq
internal EMG output.m_portLongitudinalKinematicRequest.get().m_targetRequest.m_stationaryHoldMode";
CM_ SG_ 291 ADAS_LimAx_LIM "Longitudinal Acceleration Limit Request from DASy
Takeover JLR Flexray::DADCAxLmtIT4";
CM_ SG_ 291 ADAS_ShtDwnStrat_ACC "Shutdown Strategy
Takeover JLR Flexray::MTLongShutdwnStrat";
CM_ SG_ 291 ADAS_ShtDwnStrat_Lim "Shutdown Strategy
Takeover JLR Flexray::MTLongLmtShutdwnStrat";
CM_ SG_ 291 ADAS_LimActReq "Signal indicating the DADC speed limiter is active
Takeover JLR Flexray::DADCAxLmtActive";
CM_ SG_ 291 ADAS_EngStartRun_Req "Information if EnablePwtrnTrq is requested by VMC in DASy. If requested, then no engine stop / engine start desired (control of start/stop feature)
Takeover JLR Flexray::DADCCoastReq";
CM_ SG_ 291 ADAS_CoastReq_ACC "Information if Coast is requested by VMC in DASy
Takeover JLR Flexray::DADCCoastReq";
CM_ SG_ 291 ADAS_Sts_LIM "Status LIM";
CM_ SG_ 291 LIM_pos_Sollbeschl_Grad_02_D "Empfehlung an den Triebstrangkoordinator , mit welchem betragsmaessig maximalen positiven Gradienten eine ACC-Anforderung 'ACC_Sollbeschleunigung_02' einzuregeln ist.";
CM_ SG_ 291 LIM_neg_Sollbeschl_Grad_02_D "Empfehlung an den Triebstrangkoordinator , mit welchem betragsmaessig maximalen negativen Gradienten eine ACC-Anforderung 'ACC_Sollbeschleunigung_02' einzuregeln ist.";
CM_ SG_ 291 LIM_zul_Regelabw_unten_D "Anforderung an den Triebstrangkoordinator. Zulaessiger Betrag der Abweichung zwischen angeforderter 'ACC_Sollbeschleunigung(_02)' und umzusetzender Sollbeschleunigung  im TSK. Im TSK wird, abhaengig vom Arbeitspunkt die Toleranz und die Sollbeschleunigung f";
CM_ SG_ 291 LIM_zul_Regelabw_oben_D "Anforderung an den Triebstrangkoordinator. Zulaessiger Betrag der Abweichung zwischen angeforderter 'ACC_Sollbeschleunigung(_02)' und umzusetzender Sollbeschleunigung  im TSK. Im TSK wird, abhaengig vom Arbeitspunkt die Toleranz und die Sollbeschleunigung f";
CM_ SG_ 291 ACC_pos_Sollbeschl_Grad_02_D "Empfehlung an den Triebstrangkoordinator , mit welchem betragsmaessig maximalen positiven Gradienten eine ACC-Anforderung 'ACC_Sollbeschleunigung_02' einzuregeln ist.";
CM_ SG_ 291 ACC_neg_Sollbeschl_Grad_02_D "Empfehlung an den Triebstrangkoordinator , mit welchem betragsmaessig maximalen negativen Gradienten eine ACC-Anforderung 'ACC_Sollbeschleunigung_02' einzuregeln ist.";
CM_ SG_ 291 ACC_Minimale_Bremsung_D "Im Falle eines gesetzten Bits wird vom ACC dem TSK angezeigt, dass es sich im Resume_Suspend_Mode befindet. In diesem Mode darf der TSK keine ECD-Bremsung anfordern, unabhaengig von der 'ACC_Sollbeschleunigungsanforderung'.";
CM_ SG_ 291 ACC_zul_Regelabw_unten_D "Anforderung an den Triebstrangkoordinator. Zulaessiger Betrag der Abweichung zwischen angeforderter 'ACC_Sollbeschleunigung(_02)' und umzusetzender Sollbeschleunigung  im TSK. Im TSK wird, abhaengig vom Arbeitspunkt die Toleranz und die Sollbeschleunigung f";
CM_ SG_ 291 ACC_zul_Regelabw_oben_D "Anforderung an den Triebstrangkoordinator. Zulaessiger Betrag der Abweichung zwischen angeforderter 'ACC_Sollbeschleunigung(_02)' und umzusetzender Sollbeschleunigung  im TSK. Im TSK wird, abhaengig vom Arbeitspunkt die Toleranz und die Sollbeschleunigung f";
CM_ SG_ 291 ACC_06_CheckSum_D "CheckSum ACC_06 - AUTOSAR E2E Profile 1";
CM_ SG_ 291 ACC_06_AliveCounter_D "AliveCounter ACC_06 - AUTOSAR E2E Profile 1";
CM_ BO_ 842 "TDB if still needed
old HMI interface, not linked in Flux";
CM_ SG_ 842 ADAS_Sts_HWA "HWA status (observed quantity)";
CM_ SG_ 842 ADAS_HiwayExitAuxSts "Freeway exit assist status";
CM_ SG_ 842 ADAS_ActvBtnDispReq_HEA "TBD
HEA Activate button to display request";
CM_ SG_ 842 ADAS_Sts_ALC "ALC Status";
CM_ SG_ 842 ADAS_HandsOffTakeOverReq_ALC "ALC off-hand takeover request (reserved)";
CM_ SG_ 842 ADAS_OverMod_ALC "ALC override mode (reserved, not addressed by ICC at this time)";
CM_ SG_ 842 ADAS_ALCAudioWarnLe "ADAS Active lane change sound warning left";
CM_ SG_ 842 ADAS_LCReturnToLane "Target lane occupied, change lanes back to home lane";
CM_ SG_ 842 ADAS_LeLaneOccupied "ADAS Active Lane Change Left Occupancy";
CM_ SG_ 842 ADAS_RiLaneOccupied "ADAS Active Lane Change Right Occupancy";
CM_ SG_ 842 ADAS_LeLCArrow "Left lane change arrow";
CM_ SG_ 842 ADAS_ALCAudioWarnRi "ADAS Active lane change sound warning right";
CM_ SG_ 842 ADAS_LeLaneOccupiedWarn "Left lane occupied, wait until free before changing lanes";
CM_ SG_ 842 ADAS_RiLaneOccupiedWarn "Right lane occupied, wait until free before changing lanes";
CM_ SG_ 842 ADAS_ALCTakeOverReq "ALC Request for driver takeover (reserved, ICC is not processing for now)";
CM_ SG_ 842 ADAS_LCSysFlt "System failure during lane change (observation)";
CM_ SG_ 842 ADAS_TurnLampOff "Turn off turn signal alert";
CM_ SG_ 842 ADAS_CtrlrFlt "ADAS controller failure";
CM_ SG_ 842 ADAS_RiLCArrow "Right lane change arrow";
CM_ SG_ 842 ADAS_Sts_ESS "ESS status (reserved)";
CM_ SG_ 842 ADAS_Warn_ESS "ESS alarm (reserved)";
CM_ SG_ 842 ADAS_DrvrOccpyReq "ADAS request for DMC seat do-it-yourself testing (reserved)";
CM_ BO_ 1184 "HMI touch interface - requests from user over display";
CM_ SG_ 1184 MainSwitchACC "Indicates ACC mainSwitch state";
CM_ SG_ 1184 MainSwitchADC "Indicates ADC mainSwitch state";
CM_ SG_ 1184 MainSwitchACCplus "Indicates ACCplus mainSwitch state";
CM_ SG_ 1184 MainSwitchTLR "Indicates Treffic Sign Reaction mainSwitch state";
CM_ SG_ 1184 ACCplusActivationSubfeature_SLA "Indicates ACC mainSwitch state";
CM_ SG_ 1184 ACCplusActivationSubfeatureCSA "Indicates ACC mainSwitch state";
CM_ SG_ 1184 ACCplusActivationSubfeatureSPA "Indicates ACC mainSwitch state";
CM_ SG_ 1184 ACCplusActivationSubfeatureFrict "Indicates ACC mainSwitch state";
CM_ SG_ 1184 ACCDriverInputTimeGapChange "Not yet used";
CM_ SG_ 1184 ACCDriverInputSet "Not yet used";
CM_ SG_ 1184 ACCDriverInputResume "Not yet used";
CM_ SG_ 1184 ACCDriverInputSetSpeedDecrease "Not yet used";
CM_ SG_ 1184 ACCDriverInputSetSpeedIncrease "Not yet used";
CM_ SG_ 1184 ADCDriverInputActivationDeactiva "Not yet used";
CM_ SG_ 1184 ADCParameterSelection "Indicates selected ADC parameter Set";
CM_ SG_ 1184 Measurement_label "This signal can be used for endurance/Apollo run labelling purposes";
CM_ BO_ 1200 "HMI touch interface - response and display info from ADAS";
CM_ SG_ 1200 IsAvailableACCplus0 "Indicates ACC availability";
CM_ SG_ 1200 IsAvailableADC "Indicates ADC availability";
CM_ SG_ 1200 IsAvailableACCplus1 "Indicates ACCplus availability";
CM_ SG_ 1200 IsAvailableTLR "Indicates TLR availability";
CM_ SG_ 1200 IsActiveACC "Indicates active ACC";
CM_ SG_ 1200 IsActiveADC "Indicates active ADC";
CM_ SG_ 1200 IsActiveACCplus "Indicates active ACCplus";
CM_ SG_ 1200 IsActiveTLR "Indicates active TLR";
CM_ SG_ 1200 ACCplusIsActiveSubfeatureSLA "Indicates active SLA subfeature";
CM_ SG_ 1200 ACCplusIsActiveSubfeatureCSA "Indicates active CSA subfeature";
CM_ SG_ 1200 ACCplusIsActiveSubfeatureSPA "Indicates active SPA subfeature";
CM_ SG_ 1200 ACCplusIsActiveSubfeatureFrictio "Indicates active Friction subfeature";
CM_ SG_ 1200 SelectedADCVariant "Indicates selected ADC variant";
CM_ SG_ 1200 ActiveADCParameterSet "Indicates selected ADC parameter set";
CM_ SG_ 1200 SelectedACFDrivingMode "Indicates selected ACF driving mode";
CM_ SG_ 1200 FrontCollisionWarningSensit_0000 "Indicates selected FCW sensitivity";
CM_ BO_ 1210 "HMI interface for ADAS Tx information";
CM_ SG_ 1210 TurnIndicatorSignal "Information on turn indicator state";
CM_ SG_ 1210 AlcPremiumState "status information on AlcPremium function";
CM_ SG_ 1210 AlcPlusState "status information on AlcPlus function";
CM_ SG_ 1210 AlcEnhancedStatus "status information on AlcEnhanced function";
CM_ SG_ 1210 ALCFeatureStatus "bit array for indicating ALC status
    0 bit: Left feasibility (false = not feasible: true = feasible)
    1 bit: Right feasibility (false = not feasible: true = feasible)
    2 bit: TAD premium status (false = disabled: true = enabled)
    3 bit: ALC side (false = left: true = right)
    4-7 bit: Backup";
CM_ SG_ 1210 LKAStatus "Indicates status / availability of the Lane Keeping Assist";
CM_ SG_ 1210 LDWStatus "Indicates status / availability of the Lane Depature Warning";
CM_ SG_ 1210 ELKSLStatus "Indicates status / availability of the Emergency Lane Keeping Solid Line";
CM_ SG_ 1210 ELKHREStatus "Indicates status / availability of the Emergency Lane Keeping Horizontal Road Edge";
CM_ SG_ 1210 ELKVREStatus "Indicates status / availability of the Emergency Lane Keeping Vertical Road Edge";
CM_ SG_ 1210 ELKOTStatus "Indicates status / availability of the Emergency Lane Keeping Overtaking";
CM_ SG_ 1210 ELKOCVStatus "Indicates status / availability of the Emergency Lane Keeping Oncoming Vehicle";
CM_ SG_ 1210 OffsetReason "VehicleLateralOffset offset reason";
CM_ SG_ 1210 OffsetDirection "VehicleLateralOffset offset direction";
CM_ SG_ 1210 DisplayedLaneMarking4Y "Provides the location of the lane 4 as a lateral distance from ego center";
CM_ SG_ 1210 DisplayedLaneMarking3Y "Provides the location of lane 3 as a lateral distance from ego center";
CM_ SG_ 1210 DisplayedLaneMarking2Y "Provides the location of lane 2 as a lateral distance from ego center";
CM_ SG_ 1210 DisplayedLaneMarking1Y "Provides the location of lane 1 as a lateral distance from ego center";
CM_ SG_ 1210 DisplayedLaneMarking4Type "Indicates the style of lane 4 marking";
CM_ SG_ 1210 DisplayedLaneMarking3Type "Indicates the style of lane 3 marking";
CM_ SG_ 1210 DisplayedLaneMarking2Type "Indicates the style of lane 2 marking";
CM_ SG_ 1210 DisplayedLaneMarking1Type "Indicates the style of lane 1 marking";
CM_ SG_ 1210 DisplayedLaneMarking4Color "Indicates the color of lane 4 marking";
CM_ SG_ 1210 DisplayedLaneMarking3Color "Indicates the color of lane 3 marking";
CM_ SG_ 1210 DisplayedLaneMarking2Color "Indicates the color of lane 1 marking";
CM_ SG_ 1210 DisplayedLaneMarking1Color "Indicates the color of lane1  marking";
CM_ SG_ 1210 Number02 "Representation of a displayed number - Speed profile ACC+";
CM_ SG_ 1210 Number01 "Representation of a displayed number - NextSpeedLimit ACC+";
CM_ SG_ 1210 Indicator16 "display indicator";
CM_ SG_ 1210 Indicator15 "display indicator";
CM_ SG_ 1210 Indicator14 "display indicator";
CM_ SG_ 1210 Indicator13 "display indicator";
CM_ SG_ 1210 Indicator12 "display indicator";
CM_ SG_ 1210 Indicator11 "display indicator";
CM_ SG_ 1210 Indicator10 "display indicator";
CM_ SG_ 1210 Indicator09 "display indicator";
CM_ SG_ 1210 Indicator08 "display indicator - ACC+ roundabout icon";
CM_ SG_ 1210 Indicator07 "display indicator - ACC+ cloud off icon";
CM_ SG_ 1210 Indicator06 "display indicator - ACC+ cloud icon";
CM_ SG_ 1210 Indicator05 "display indicator - adc_icon";
CM_ SG_ 1210 Indicator04 "display indicator - friction_icon";
CM_ SG_ 1210 Indicator03 "display indicator - csa_icon";
CM_ SG_ 1210 Indicator02 "display indicator - sla_icon";
CM_ SG_ 1210 Indicator01 "display indicator - lss_elk_icon";
CM_ SG_ 1210 ACC_ICON_LADI "Displays the LADI-Icon in the bottom row as an indicator for lateral-danger";
CM_ SG_ 1210 ADAS_4BA_CheckSum "CheckSum ADAS_4BA";
CM_ SG_ 1210 CurvatureInformation "Provides the curve radius in m";
CM_ SG_ 1210 TrafficSignSpeedLimit "Displays the legal speed limit according to traffic signs";
CM_ SG_ 1210 TrafficLightStatus "Status of relevant traffic light";
CM_ SG_ 1210 TrafficLightDisplayRequest "Request signal for visualizing traffic light symbol";
CM_ SG_ 1210 ACCTrafficLightReaction "Display state of the ACC+ Traffic light reaction feature";
CM_ SG_ 1210 SensorConeFrontCenter "Displays the sensing area of the front center radar";
CM_ SG_ 1210 NeighboringVehicle1VehicleType "Provides the type of the neihboring vehicle no. 1";
CM_ SG_ 1210 NeighboringVehicle1X "Provides the location of the neighboring vehicle no.1 as a longitudinal distance from ego center";
CM_ SG_ 1210 NeighboringVehicle1Y "Provides the location of the neighboring vehicle no.1 as a lateral distance from ego center";
CM_ SG_ 1210 NeighboringVehicle1AugmentedData "Provides additional information of the surrounding vehicle no. 1";
CM_ SG_ 1210 NeighboringVehicle2VehicleType "Provides the type of the neihboring vehicle no. 2";
CM_ SG_ 1210 NeighboringVehicle2X "Provides the location of the neighboring vehicle no.2 as a longitudinal distance from ego center";
CM_ SG_ 1210 NeighboringVehicle2Y "Provides the location of the neighboring vehicle no.2 as a lateral distance from ego center";
CM_ SG_ 1210 ADAS_4BA_AliveCounter "AliveCounter ADAS_4BA";
CM_ SG_ 1210 NeighboringVehicle2AugmentedData "Provides additional information of the surrounding vehicle no. 2";
CM_ SG_ 1210 NeighboringVehicle3VehicleType "Provides the type of the neihboring vehicle no. 3";
CM_ SG_ 1210 NeighboringVehicle3X "Provides the location of the neighboring vehicle no.3 as a longitudinal distance from ego center";
CM_ SG_ 1210 NeighboringVehicle3Y "Provides the location of the neighboring vehicle no.3 as a lateral distance from ego center";
CM_ SG_ 1210 NeighboringVehicle3AugmentedData "Provides additional information of the surrounding vehicle no. 3";
CM_ SG_ 1210 NeighboringVehicle4VehicleType "Provides the type of the neihboring vehicle no. 4";
CM_ SG_ 1210 NeighboringVehicle4X "Provides the location of the neighboring vehicle no.4 as a longitudinal distance from ego center";
CM_ SG_ 1210 NeighboringVehicle4Y "Provides the location of the neighboring vehicle no.4 as a lateral distance from ego center";
CM_ SG_ 1210 NeighboringVehicle4AugmentedData "Provides additional information of the surrounding vehicle no. 4";
CM_ SG_ 1210 NeighboringVehicle5VehicleType "Provides the type of the neihboring vehicle no. 5";
CM_ SG_ 1210 NeighboringVehicle5X "Provides the location of the neighboring vehicle no.5 as a longitudinal distance from ego center";
CM_ SG_ 1210 NeighboringVehicle5Y "Provides the location of the neighboring vehicle no.5 as a lateral distance from ego center";
CM_ SG_ 1210 NeighboringVehicle5AugmentedData "Provides additional information of the surrounding vehicle no. 5";
CM_ SG_ 1210 NeighboringVehicle6VehicleType "Provides the type of the neihboring vehicle no. 6";
CM_ SG_ 1210 NeighboringVehicle6X "Provides the location of the neighboring vehicle no.6 as a longitudinal distance from ego center";
CM_ SG_ 1210 LedHadState "Displays the HWA-hf system state visually by using two LED-panels on the cockpit";
CM_ SG_ 1210 NeighboringVehicle6Y "Provides the location of the neighboring vehicle no.6 as a lateral distance from ego center";
CM_ SG_ 1210 NeighboringVehicle6AugmentedData "Provides additional information of the surrounding vehicle no. 6";
CM_ SG_ 1210 NeighboringVehicle7VehicleType "Provides the type of the neihboring vehicle no. 7";
CM_ SG_ 1210 NeighboringVehicle7X "Provides the location of the neighboring vehicle no.7 as a longitudinal distance from ego center";
CM_ SG_ 1210 NeighboringVehicle7Y "Provides the location of the neighboring vehicle no.7 as a lateral distance from ego center";
CM_ SG_ 1210 NeighboringVehicle7AugmentedData "Provides additional information of the surrounding vehicle no. 7";
CM_ SG_ 1210 NeighboringVehicle8VehicleType "Provides the type of the neihboring vehicle no. 8";
CM_ SG_ 1210 HwaHfStatus "Indicates status / availability of the hands free control";
CM_ SG_ 1210 NeighboringVehicle8X "Provides the location of the neighboring vehicle no.8 as a longitudinal distance from ego center";
CM_ SG_ 1210 NeighboringVehicle8Y "Provides the location of the neighboring vehicle no.8 as a lateral distance from ego center";
CM_ SG_ 1210 NeighboringVehicle8AugmentedData "Provides additional information of the surrounding vehicle no. 8";
CM_ SG_ 1210 HwaHonStatus "Indicates status / availability of the hands on control";
CM_ SG_ 1210 HwaAccStatus "Indicates status / availability of the ACC control";
CM_ SG_ 1210 SetSpeed "Indicates the set speed for hands free control";
CM_ SG_ 1210 SetSpeedColor "Sets the color of the set speed digits";
CM_ SG_ 1210 DisplayedEgoSpeed "Indicates the actual speed";
CM_ SG_ 1210 DisplayedEgoSpeedColor "Sets the color of the set speed digits";
CM_ SG_ 1210 DisplayedLaneMarkingLeftType "Indicates the style of left lane marking";
CM_ SG_ 1210 DisplayedLaneMarkingLeftColor "Indicates the color of left lane marking";
CM_ SG_ 1210 DisplayedLaneMarkingRightType "Indicates the style of right lane marking";
CM_ SG_ 1210 DisplayedLaneMarkingRightColor "Indicates the color of right lane marking";
CM_ SG_ 1210 TimeGapSetValue "Indicates the set value for the time gap by using visual bars and/or a range symbol in front of the ego vehicle";
CM_ SG_ 1210 TimeGapColor "Sets the color of the displayed time gap";
CM_ SG_ 1210 ReducedTimeGap "The amount by how much the time gap should be reduced. Time gap change between 0s and 3,15s. The factor/min/max to reach that range will be coded in DASy.";
CM_ SG_ 1210 AdcStateInformation "Represents the current state of the ADC feature (off, active, failure etc...)";
CM_ SG_ 1210 EgoLaneChange "Indicates when the ego vehicle plans or performs a lane change";
CM_ SG_ 1210 DisplayedTextMessageId "Displays visual text notfications on the cockpit";
CM_ SG_ 1210 PopupTextMessage "Displays the text notification of ADAS_hmiDisplayedTextMessageId in pop-up style";
CM_ SG_ 1210 AudioNotificationId "Plays back an auditory sound notification, e.g. warning sound or speech message";
CM_ SG_ 1210 AuxiliarySymbol "Displays additional symbols or animations, e.g. coffee cup (fatigue detection), collision warning, hands-on animation, etc.)";
CM_ SG_ 1210 EgoLaneAssignment "determines in which lane ego is driving";
CM_ SG_ 1210 TrafficLightDistance "Distance information from ACC+ traffic light reaction feature";
CM_ BO_ 1211 "HMI interface for ADAS Tx information";
CM_ SG_ 1211 TL_warning "Traffic lights";
CM_ SG_ 1211 TLF_Mode "Traffic lights";
CM_ SG_ 1211 TL_suggestedDriveAction "Traffic lights";
CM_ SG_ 1211 TLF_functionState "Traffic lights";
CM_ BO_ 1212 "HMI interface for ADAS Tx information - traffic rule and lane curvature";
CM_ SG_ 1212 ADAS_TrafficSign1_Main "Traffic Sign to be visualized in TS1 Slot";
CM_ SG_ 1212 ADAS_TrafficSign1_AdditionalSign "Type of the additional sign corresponding to TS1 Slot";
CM_ SG_ 1212 ADAS_TrafficSign1_Distance "Distance information corresponding to TS1 Additional sign";
CM_ SG_ 1212 ADAS_TrafficSign1_Status "Requested visualization mode for TS1 slot";
CM_ SG_ 1212 ADAS_TrafficSign2_Main "Traffic Sign to be visualized in TS2 Slot";
CM_ SG_ 1212 ADAS_TrafficSign2_AdditionalSign "Type of the additional sign corresponding to TS2 Slot";
CM_ SG_ 1212 ADAS_TrafficSign2_Distance "Distance information corresponding to TS2 Additional sign";
CM_ SG_ 1212 ADAS_TrafficSign2_Status "Requested visualization mode for TS2 slot";
CM_ SG_ 1212 ADAS_TrafficSign3_Main "Traffic Sign to be visualized in TS3 Slot";
CM_ SG_ 1212 ADAS_TrafficSign3_AdditionalSign "Type of the additional sign corresponding to TS3 Slot";
CM_ SG_ 1212 ADAS_TrafficSign3_Distance "Distance information corresponding to TS3 Additional sign";
CM_ SG_ 1212 ADAS_TrafficSign3_Status "Requested visualization mode for TS3 slot";
CM_ SG_ 1212 ADAS_RSF_Status "Status of RSF function";
CM_ BO_ 1213 "HMI interface for ADAS Tx information - lane curvature";
CM_ BO_ 1625 "TDF if still needed";
CM_ SG_ 1625 ADAS_PartVers "ADAS part number";
CM_ SG_ 1625 ADAS_HwVers "Last two digits of ADAS hardware version number";
CM_ BO_ 262 "HEP data transfered over MGW";
CM_ SG_ 262 ADAS_Meta_ProtVer_MinorSub "Contains Sub-Minor protocol version";
CM_ SG_ 262 ADAS_Meta_CycCnt "Cyclic counter of this message type: reconstructor can use this value to detect missing messages";
CM_ SG_ 262 ADAS_Meta_MsgType "Used for multiplexed ADASIS messages or for verification purposes. See value descriptions for details";
CM_ SG_ 262 ADAS_Meta_MapVerQtr "Content of this field is Year quarter of release of map of current area.
For example, Q4/2007 map will be
MAP VERSION (Y) = 7
MAP VERSION (Q) = 3
Value of this field could vary between messages if map uses data with different release dates";
CM_ SG_ 262 ADAS_Meta_MapVerYear "Content of this field is Year of release of map of current area. For 2007, this field will contain value 7.
Value of this field could vary between messages if map uses data with different release dates";
CM_ SG_ 262 ADAS_Meta_MapProvider "Map Provider of current area (map tile, region, country, etc)";
CM_ SG_ 262 ADAS_Meta_HwVer "This field is ADAS Horizon Provider specific.";
CM_ SG_ 262 ADAS_Meta_ProtVer_Minor "Contains Minor protocol version;
For instance, for protocol version 0.15 Major Protocol Version will be 0 and Minor Protocol Version 15.";
CM_ SG_ 262 ADAS_Meta_ProtVer_Major "Contains Minor protocol version;
For instance, for protocol version 0.15 Major Protocol Version will be 0 and Minor Protocol Version 15.";
CM_ SG_ 262 ADAS_Meta_SpdUnits "Specifies whether miles or kilometers are used as units (speed limits, etc.)";
CM_ SG_ 262 ADAS_Meta_DrvSide "Specifies the driving side of the road";
CM_ SG_ 262 ADAS_Meta_RegionCode "For a given Country Code, specifies region of a country.
0 stands for unknown, all other values are system specific.";
CM_ SG_ 262 ADAS_Meta_CountryCode "ISO 3166-1 country code";
CM_ BO_ 257 "HEP data transfered over MGW";
CM_ SG_ 257 ADAS_Posn_PosProbb "Probability of this position candidate";
CM_ SG_ 257 ADAS_Posn_PosConfdc "Position confidence: this field contain Av2HP implementation specific values. Use 0 for highest confidence, 6 for lowest confidence, 7 means SNA.";
CM_ SG_ 257 ADAS_Posn_CurLane "Current lane; for details, see value descriptions for current Lane values";
CM_ SG_ 257 ADAS_Posn_Spd "Speed of the vehicle projected to the path";
CM_ SG_ 257 ADAS_Posn_RelHead "Heading relative to path:
0 in path direction
1 .. 126: right from path direction
253 .. 128: left from link direction
127 in opposite direction
253 unknown";
CM_ SG_ 257 ADAS_Posn_Idx "If Av2HP supports positioning alternatives, contains index of this Position Candidate. Candidate 0 is always most probable position candidate,
candidate 1 second etc. If Av2HP does not support positioning alternatives, it will be always 0.";
CM_ SG_ 257 ADAS_Posn_Age "Time difference between the moment the message is sent and the moment the vehicle position is calculated by the positioning sub-system.  510 means older than 2545 ms, 511 means invalid.";
CM_ SG_ 257 ADAS_Posn_PathIdx "Index of current path: If this number differs from one specified in previous POSITION message, vehicle left the original path
Indices 0-7 have special meaning: see value descriptions for details";
CM_ SG_ 257 ADAS_Posn_Offset "Offset of current position from the current path's start point modulo 8191. Offset 8191 is invalid.";
CM_ SG_ 257 ADAS_Posn_MsgTyp "Used for multiplexed ADASIS messages or for verification purposes. See value descriptions for details";
CM_ SG_ 257 ADAS_Posn_CycCnt "Cyclic counter of this message type: reconstructor can use this value to detect missing messages";
CM_ BO_ 261 "HEP data transfered over MGW";
CM_ SG_ 261 ADAS_ProfLong_Retr "If true, this message was sent already at least once before";
CM_ SG_ 261 ADAS_ProfLong_PathIdx "Index of current path: If this number differs from one specified in previous PROFILE message, vehicle left the original path
Indices 0-7 have special meaning: see value descriptions for details";
CM_ SG_ 261 ADAS_ProfLong_Offset "Offset of position of the first profile spot from start position modulo 8191. Offset 8191 is invalid.";
CM_ SG_ 261 ADAS_ProfLong_MsgType "Used for multiplexed ADASIS messages or for verification purposes. See value descriptions for details";
CM_ SG_ 261 ADAS_ProfLong_CycCnt "Cyclic counter of this message type: reconstructor can use this value to detect missing messages";
CM_ SG_ 261 ADAS_ProfLong_CtrlPoint "If true, values in this message specifies additional control points required for certain interpolation types;
if false, actual profile values are specified";
CM_ SG_ 261 ProfileLong_Value "Profile value at Offset";
CM_ SG_ 261 ADAS_ProfLong_ProfType "Type of the Profile. See value descriptions for details";
CM_ BO_ 260 "HEP data transfered over MGW";
CM_ SG_ 260 ADAS_ProfShort_ProfType "Type of the Profile. See value descriptions for details";
CM_ SG_ 260 ADAS_ProfShort_Retr "If true, this message was sent already at least once before";
CM_ SG_ 260 ADAS_ProfShort_PathIdx "Index of current path: If this number differs from one specified in previous PROFILE message, vehicle left the original path
Indices 0-7 have special meaning: see value descriptions for details";
CM_ SG_ 260 ADAS_ProfShort_Offset "Offset of position of the first profile spot from start position modulo 8191. Offset 8191 is invalid.";
CM_ SG_ 260 ADAS_ProfShort_MsgType "Used for multiplexed ADASIS messages or for verification purposes. See value descriptions for details";
CM_ SG_ 260 ADAS_ProfShort_CycCnt "Cyclic counter of this message type: reconstructor can use this value to detect missing messages";
CM_ SG_ 260 ADAS_ProfShort_Value1 "Profile value at Offset+Distance1, if Distance1 > 0";
CM_ SG_ 260 ADAS_ProfShort_Dist1 "Distance from first profile spot to the second one.
If 0, no other profile values are defined in this message.";
CM_ SG_ 260 ADAS_ProfShort_Value0 "Profile value at Offset";
CM_ SG_ 260 ADAS_ProfShort_CtrlPoint "If true, values in this message specifies additional control points required for certain interpolation types;
if false, actual profile values are specified";
CM_ BO_ 258 "HEP data transfered over MGW";
CM_ SG_ 258 ADAS_Seg_PartOfCalcRoute "Whether segment is part of calculated route";
CM_ SG_ 258 ADAS_Seg_RelProbb "Relative probability of the path on the crossing: continuation of the path at an intersection can be calculated as 100 - sum (probability of all stubs)
Value 0 indicates that turn is not allowed.
Value 30 is not allowed.
Value 31 means unknown";
CM_ SG_ 258 ADAS_Seg_Offset "Offset of position of the first profile spot from start position modulo 8191. Offset 8191 is invalid.";
CM_ SG_ 258 ADAS_Seg_Retr "If true, this message was sent already at least once before";
CM_ SG_ 258 ADAS_Seg_PathIdx "Index of current path: If this number differs from one specified in previous SEGMENT message, vehicle left the original path
Indices 0-7 have special meaning: see value descriptions for details";
CM_ SG_ 258 ADAS_Seg_MsgType "Used for multiplexed ADASIS messages or for verification purposes. See value descriptions for details";
CM_ SG_ 258 ADAS_Seg_FormOfWay "Describes the form of way of the segment. See value descriptions for details";
CM_ SG_ 258 ADAS_Seg_CycCnt "Cyclic counter of this message type: reconstructor can use this value to detect missing messages";
CM_ SG_ 258 ADAS_Seg_CmplxInsct "Whether segment is part of a complex intersection";
CM_ SG_ 258 ADAS_Seg_BuildUpArea "Whether segment is part of a build-up area (driving in city)";
CM_ SG_ 258 ADAS_Seg_DividedRoad "Whether segment is part of a divided road";
CM_ SG_ 258 ADAS_Seg_Bridge "Whether segment is part of a bridge";
CM_ SG_ 258 ADAS_Seg_Tunnel "Whether segment is part of a tunnel";
CM_ SG_ 258 ADAS_Seg_NumOfLaneOppDir "Number of lanes in opposite direction. 0 denotes one-direction road, 1 for one lane only; 2 indicates 2 or more lanes.
Value 3 means unknown.";
CM_ SG_ 258 ADAS_Seg_NumOfLaneDrvDir "Number of lanes in driving direction: also implies driving direction. 0 denotes driving in wrong direction, 1-5 are verbatim values, and 6 indicate 6 or more lanes.
Value 7 means unknown.";
CM_ SG_ 258 ADAS_Seg_EffSpdLmtType "Describes what kind of Speed Limit is in effect. See value descriptions for details";
CM_ SG_ 258 ADAS_Seg_EffSpdLmt "Current Speed Limit: May be implicit (for instance, in cities), or explicit.
Current time of day, day of week and weather conditions are taken in account by Horizon Provider in determining effective speed limit.";
CM_ SG_ 258 ADAS_Seg_FuncRoadClass "Functional class of the segment";
CM_ SG_ 258 ADAS_Seg_Update "Value true indicates that this message contains updated information of already transmitted SEGMENT";
CM_ BO_ 259 "HEP data transfered over MGW";
CM_ SG_ 259 ADAS_Stub_PartOfCalcRoute "Whether segment is part of calculated route";
CM_ SG_ 259 ADAS_Stub_FuncRoadClass "Functional class of the segment";
CM_ SG_ 259 ADAS_Stub_LastStub "Indicates that this STUB message is the last one that refers to given path and offset; if false more STUB messages for this offset will be sent.";
CM_ SG_ 259 ADAS_Stub_Update "Value true indicates that this message contains updated information of already transmitted STUB.";
CM_ SG_ 259 ADAS_Stub_SubPathIdx "This is Index of new path.";
CM_ SG_ 259 ADAS_Stub_Retr "If true, this message was sent already at least once before";
CM_ SG_ 259 ADAS_Stub_PathIdx "This is Index of parent path.";
CM_ SG_ 259 ADAS_Stub_Offset "Offset of position of the first profile spot from start position modulo 8191. Offset 8191 is invalid.";
CM_ SG_ 259 ADAS_Stub_NumOfLaneOppDir "Number of lanes in opposite direction. 0 denotes one-direction road, 1 for one lane only; 2 indicates 2 or more lanes.
Value 3 means unknown.";
CM_ SG_ 259 ADAS_Stub_NumOfLaneDrvDir "Number of lanes in driving direction: also implies driving direction. 0 denotes driving in wrong direction, 1-5 are verbatim values, and 6 indicate 6 or more lanes.
Value 7 means unknown.";
CM_ SG_ 259 ADAS_Stub_MsgType "Used for multiplexed ADASIS messages or for verification purposes. See value descriptions for details";
CM_ SG_ 259 ADAS_Stub_FormOfWay "Describes the form of way of the stub. See value descriptions for details";
CM_ SG_ 259 ADAS_Stub_CycCnt "Cyclic counter of this message type: reconstructor can use this value to detect missing messages";
CM_ SG_ 259 ADAS_Stub_RtOfWay "Whether this stub has the right of way. See value descriptions for details";
CM_ SG_ 259 ADAS_Stub_CmplxInsct "Describes whether stub is part of a complex intersection";
CM_ SG_ 259 ADAS_Stub_RelProbb "Relative probability of the path on the crossing: continuation of the path at an intersection can be calculated as 100 - sum (probability of all stubs)
Value 0 indicates that turn is not allowed.
Value 30 is not allowed.
Value 31 means unknown";
CM_ SG_ 259 ADAS_Stub_TurnAngl "Turn angle of the stub
0 = straight
90 = right turn
180 = U-turn
270 = left turn
etc";
CM_ BO_ 449 "Lateral actuation request DASy to Steering";
CM_ SG_ 449 DADCSteerTqReqActive "DADC request flag for Hands-on/Hands-Free steering torque control to be enabled";
CM_ SG_ 449 ADAS_1C1_CheckSum "CheckSum ADAS_1C1";
CM_ SG_ 449 ADAS_RdWhlAgReqActive "DASy request flag for road wheel angle control to be enabled
(expected calibration setting from the Lateral Motion Controller)";
CM_ SG_ 449 ADAS_1C1_AliveCounter "AliveCounter ADAS_1C1 - AUTOSAR E2E Profile 1";
CM_ SG_ 449 ADAS_RdWhlAgReq "DASy send road wheel angle request to EPS";
CM_ SG_ 449 ADAS_ExtMaxRPCTrq "Maximum externally allowed RPC torque for Level 2 (TBT Level)";
CM_ SG_ 449 ADAS_ExtMinRPCTrq "Minimum externally allowed RPC torque for Level 2 (TBT Level)";
CM_ BO_ 272 "Fully multiplexed long ADASIS horizon (values to be interpreted depending on MsgTyp)";
CM_ SG_ 272 ADASLONG_Mux_MsgTyp "Used for multiplexed ADASIS messages or for verification purposes. See value descriptions for details";
CM_ BO_ 443 "AFB: Actuator Feedback";
CM_ SG_ 443 AFB_1BB_AliveCounter "AliveCounter AFB_1BB
overtaken from VCU_1BA_AliveCounter";
CM_ SG_ 443 AFB_1BB_CheckSum "CheckSum AFB_1BB
overtaken from VCU_1BA_CheckSum";
CM_ BO_ 432 "TBD if still needed
Automated parking - status";
CM_ SG_ 432 APA_1B0_CheckSum "CheckSum APA_1B0";
CM_ SG_ 432 APA_1B0_AliveCounter "AliveCounter APA_1B0";
CM_ SG_ 432 APA_Sts "APA Status - System provides the current state of the Active Feature.";
CM_ BO_ 658 "TBD if still needed
Automated parking - type, not linked in Flux";
CM_ SG_ 658 APA_292_CheckSum "CheckSum APA_292";
CM_ SG_ 658 APA_292_AliveCounter "AliveCounter APA_292";
CM_ SG_ 658 APA_CrtPrkgTyp "Indicates current parking type, as APA, RPA, Assist.";
CM_ BO_ 672 "TBD if still needed
Automated parking - type, not linked in Flux";
CM_ SG_ 672 APA_FMEBSts "Front low-speed auxiliary brake system status signal";
CM_ SG_ 672 APA_RMEBSts "Rear low-speed auxiliary brake system status signal";
CM_ BO_ 1368 "TBD if still needed
Automated parking - type, not linked in Flux";
CM_ SG_ 1368 APA_558_CheckSum "CheckSum APA_558";
CM_ SG_ 1368 APA_558_AliveCounter "AliveCounter APA_558";
CM_ SG_ 1368 APA_Sts_PAS "Parking Assistant System Status";
CM_ BO_ 821 "Vehicle info (wiper, turn indication, lights status)";
CM_ SG_ 821 BCM_335_CheckSum "CheckSum BCM_335";
CM_ SG_ 821 BCM_335_AliveCounter "AliveCounter BCM_335";
CM_ SG_ 821 BCM_ReFogLampSwtSts "Rear fog light switch status";
CM_ SG_ 821 BCM_DangerAlrmLampSwtSts "Danger warning light switch status";
CM_ SG_ 821 BCM_LeTrunLampOutpCmd "Left turn signal output command";
CM_ SG_ 821 BCM_RiTrunLampOutpCmd "Right turn signal output command";
CM_ SG_ 821 BCM_ReWiprOutpCmd "Rear wiper output command";
CM_ SG_ 821 BCM_HiBeamOutpCmd "High beam output command";
CM_ SG_ 821 BCM_LoBeamOutpCmd "Low beam output command";
CM_ BO_ 835 "Vehicle info (door open/close)";
CM_ SG_ 835 BCM_TrailerConnection "Trailer connection status";
CM_ SG_ 835 BCM_343_CheckSum "CheckSum BCM_0x343";
CM_ SG_ 835 BCM_343_AliveCounter "AliveCounter BCM_0x343";
CM_ SG_ 835 BCM_FrntHoodLidSts "Front hood (engine bonnet) opening status";
CM_ SG_ 835 BCM_LeFrntDoorSts "Front left door opening status";
CM_ SG_ 835 BCM_RiFrntDoorSts "Front right door opening status";
CM_ SG_ 835 BCM_RiReDoorSts "Rear right door opening status";
CM_ SG_ 835 BCM_LeReDoorSts "Rear left door opening status";
CM_ BO_ 784 "Vehicle information (ADAS buttons, turn indication, wiper)";
CM_ SG_ 784 CIM_MainSwitchCC "Main switch to activate / deactivate limiter feature";
CM_ SG_ 784 CIM_MainSwitchLimiter "Main switch to activate / deactivate limiter feature";
CM_ SG_ 784 CIM_310_CheckSum "CheckSum CIM_0x310";
CM_ SG_ 784 CIM_310_AliveCounter "AliveCounter CIM_0x310";
CM_ SG_ 784 CIM_TurnLampSwtSts "Turn indication lever status";
CM_ SG_ 784 CIM_HiBeamSwtSts "TBD if used?
High beam switch status";
CM_ SG_ 784 CIM_FrntWshrSwtSts "TBD if used?
Front window washer status";
CM_ SG_ 784 CIM_ReWshrSwtSts "TBD if used?
Rear window washer status";
CM_ SG_ 784 CIM_FrntWiprSwtSts "TBD if used?
front wiper status";
CM_ SG_ 784 CIM_Swt_ADAS "ADAS button for Long and Lat";
CM_ SG_ 784 CIM_Cncl_ADAS "ADAS cancel button used for Long features";
CM_ SG_ 784 CIM_SpdRgln_ADAS "ADAS speed setting for Long features";
CM_ SG_ 784 CIM_DstWithCarFrntAdj "ADAS time gap for Long features";
CM_ SG_ 784 CIM_SpdLim_ADAS "ADAS limiter button switches between Long features CC ACC LIM ADC";
CM_ SG_ 784 CIM_SwtVld_ADAS "TBD if used?
ADAS control button validity signal";
CM_ SG_ 784 CIM_SpdRglnVld_ADAS "TBD if used?
ADAS speed setting validity";
CM_ BO_ 604 "TBD if still needed
Corner sensor status and blindness. Not transmitted by CR, but hard coded in MGW, as the info is now transmitted over CR-private-CANFD
not linked in Flux";
CM_ SG_ 604 CMRR_FL_FrntLeSnsrFlt "Front left radar malfunction (ICC not dealing with it yet)";
CM_ SG_ 604 CMRR_FL_FrntLeSnsrBli "Front left corner radar obscured (ICC not dealing with it yet)";
CM_ SG_ 604 CMRR_FL_SDASts "SDA Status";
CM_ SG_ 604 CMRR_FL_SDAWarn "SDA Alarm";
CM_ BO_ 606 "TBD if still needed
Corner sensor status and blindness. Not transmitted by CR, but hard coded in MGW, as the info is now transmitted over CR-private-CANFD
not linked in Flux";
CM_ SG_ 606 CMRR_FR_FrntLeSnsrFlt "Front right radar malfunction (ICC not dealing with it yet)";
CM_ SG_ 606 CMRR_FR_FrntLeSnsrBli "Front right corner radar obscured (ICC not dealing with it yet)";
CM_ SG_ 606 CMRR_FR_SDASts "SDA Status";
CM_ SG_ 606 CMRR_FR_SDAWarn "SDA Alarm";
CM_ BO_ 824 "TBD if still needed
Corner sensor status and blindness. Not transmitted by CR, but hard coded in MGW, as the info is now transmitted over CR-private-CANFD
not linked in Flux";
CM_ SG_ 824 CMRR_RL_LeWarn_LCA "LCA left side alarm";
CM_ SG_ 824 CMRR_RL_SnsrFlt "Rear left radar failure (ICC not dealing with it yet)";
CM_ SG_ 824 CMRR_RL_SnsrBli "Rear left radar obscured (ICC not dealing with it yet)";
CM_ SG_ 824 CMRR_RL_LeWarn_LCA_ELK "LCA left side alarm_ELK";
CM_ SG_ 824 CMRR_RL_SDASts "SDA Status";
CM_ SG_ 824 CMRR_RL_SDAWarn "SDA Alarm";
CM_ BO_ 826 "TBD if still needed
Corner sensor status and blindness. Not transmitted by CR, but hard coded in MGW, as the info is now transmitted over CR-private-CANFD
not linked in Flux";
CM_ SG_ 826 CMRR_RR_RiWarn_LCA "LCA right side alarm";
CM_ SG_ 826 CMRR_RR_SnsrFlt "Rear right radar failure (ICC not dealing with it yet)";
CM_ SG_ 826 CMRR_RR_SnsrBli "Rear right radar obscured (ICC not dealing with it yet)";
CM_ SG_ 826 CMRR_RR_LCASwtFb "Lane change warning switch feedback";
CM_ SG_ 826 CMRR_RR_RiWarn_LCA_ELK "LCA right alarm_ELK";
CM_ SG_ 826 CMRR_RR_SDAWarn "SDA Alarm";
CM_ SG_ 826 CMRR_RR_SDASts "SDA Status";
CM_ BO_ 1958 "Diagnostic request for ADAS (e.g. front radar coding and SDA)";
CM_ BO_ 1966 "Diagnostic response for ADAS (e.g. front radar coding and SDA)";
CM_ BO_ 800 "DMS information (status, gaze zones, eyes on road)";
CM_ BO_ 883 "TBD if still needed
not linked in Flux";
CM_ SG_ 883 ECC_OutdT "Ambient temperature outside the vehicle";
CM_ SG_ 883 ECC_OutdTVld "Ambient temperature outside the vehicle effective level";
CM_ BO_ 1410 "TBD if still needed
not linked in Flux";
CM_ SG_ 1410 ECC_InsdT "Temperature inside the car";
CM_ BO_ 1228 "MAP info for HF and BDA";
CM_ SG_ 1228 Ego_Lane_Info1_CRC "CRC - Autosar E2E Profile 5";
CM_ SG_ 1228 Ego_Lane_Info1_AliveCtr "Alive counter - Autosar E2E Profile 5";
CM_ SG_ 1228 Ego_Lane_Info1_TimeStamp "Map data timestamp for synchronization";
CM_ SG_ 1228 Ego_Lane_Map_Status "Validity of RSD map";
CM_ SG_ 1228 Ego_Lane_CurrentSpeedLimit "Current speed limit on the Ego Lane
159 indicates an unknown speed";
CM_ SG_ 1228 Ego_Lane_CurrentSpeedLimit_Type "type of the speed limit";
CM_ SG_ 1228 Ego_Lane_NextSpeedLimit_Value_1 "Next speed limit on ego lane";
CM_ SG_ 1228 Ego_Lane_NextSpeedLimit_Loc_1 "Next speed limit location on ego lane";
CM_ SG_ 1228 Ego_Lane_NextTopoLocation_1 "Next location of topology change";
CM_ SG_ 1228 Ego_Lane_NextTopoType_1 "Next type of topology change";
CM_ SG_ 1228 Ego_Lane_NextTopoSide_1 "Side of the next topology change";
CM_ SG_ 1228 Ego_Lane_NextTopoSide_2 "Side of the next topology change";
CM_ SG_ 1228 Ego_Lane_NextTopoSide_3 "Side of the next topology change";
CM_ SG_ 1228 Ego_Lane_NextTopoSide_4 "Side of the next topology change";
CM_ SG_ 1228 Ego_Lane_CurrBoundary_Type_R "Type of the boundary";
CM_ SG_ 1228 Ego_Lane_NextBoundary_Loc_R_1 "location of the next lane boundary change";
CM_ SG_ 1228 Ego_Lane_NextBoundary_Type_R_1 "Type of the boundary";
CM_ SG_ 1228 Ego_Lane_NextBoundary_Loc_R_2 "location of the next lane boundary change";
CM_ SG_ 1228 Ego_Lane_NextBoundary_Type_R_2 "Type of the boundary";
CM_ SG_ 1228 Ego_Lane_NextBoundary_Loc_R_3 "location of the next lane boundary change";
CM_ SG_ 1228 Ego_Lane_NextBoundary_Type_R_3 "Type of the boundary";
CM_ SG_ 1228 Ego_Lane_NextBoundary_Loc_R_4 "location of the next lane boundary change";
CM_ SG_ 1228 Ego_Lane_NextBoundary_Type_R_4 "Type of the boundary";
CM_ SG_ 1228 Ego_Lane_CurrBoundary_Type_L "Type of the boundary";
CM_ SG_ 1228 Ego_Lane_NextBoundary_Loc_L_1 "location of the next lane boundary change";
CM_ SG_ 1228 Ego_Lane_NextBoundary_Type_L_1 "Type of the boundary";
CM_ SG_ 1228 Ego_Lane_NextBoundary_Loc_L_2 "location of the next lane boundary change";
CM_ SG_ 1228 Ego_Lane_NextBoundary_Type_L_2 "Type of the boundary";
CM_ SG_ 1228 Ego_Lane_NextBoundary_Loc_L_3 "location of the next lane boundary change";
CM_ SG_ 1228 Ego_Lane_NextBoundary_Type_L_3 "Type of the boundary";
CM_ SG_ 1228 Ego_Lane_NextBoundary_Loc_L_4 "location of the next lane boundary change";
CM_ SG_ 1228 Ego_Lane_NextBoundary_Type_L_4 "Type of the boundary";
CM_ BO_ 1229 "MAP info for HF and BDA";
CM_ SG_ 1229 Ego_Lane_Info2_CRC "CRC - Autosar E2E Profile 5";
CM_ SG_ 1229 Ego_Lane_Info2_AliveCtr "Alive counter - Autosar E2E Profile 5";
CM_ SG_ 1229 Ego_Lane_Info2_TimeStamp "Map data timestamp for synchronization";
CM_ SG_ 1229 Ego_Lane_SpeedProfile_Near_N "Number of valid elements in speed profile";
CM_ SG_ 1229 Ego_Lane_SpeedProfile_Near_00 "Speed Profile from vehicle crowd";
CM_ SG_ 1229 Ego_Lane_SpeedProfile_Far_N "Number of valid elements in speed profile";
CM_ SG_ 1229 Ego_Lane_NextHotspot_Int_1 "intensity of the hotspot";
CM_ SG_ 1229 Ego_Lane_NextHotspot_Prob_1 "probability of the hotspot";
CM_ SG_ 1229 Ego_Lane_NextHotspot_Side_1 "Side of the lane change";
CM_ SG_ 1229 Ego_Lane_NextHotspot_Int_2 "intensity of the hotspot";
CM_ SG_ 1229 Ego_Lane_NextHotspot_Prob_2 "probability of the hotspot";
CM_ SG_ 1229 Ego_Lane_NextHotspot_Side_2 "Side of the lane change";
CM_ SG_ 1229 Ego_Lane_NextHotspot_Int_3 "intensity of the hotspot";
CM_ SG_ 1229 Ego_Lane_NextHotspot_Prob_3 "probability of the hotspot";
CM_ SG_ 1229 Ego_Lane_NextHotspot_Side_3 "Side of the lane change";
CM_ SG_ 1229 Ego_Lane_NextHotspot_Int_4 "intensity of the hotspot";
CM_ SG_ 1229 Ego_Lane_NextHotspot_Prob_4 "probability of the hotspot";
CM_ SG_ 1229 Ego_Lane_NextHotspot_Side_4 "Side of the lane change";
CM_ BO_ 1230 "MAP info for HF and BDA";
CM_ SG_ 1230 Left_Lane_Info_CRC "CRC - Autosar E2E Profile 5";
CM_ SG_ 1230 Left_Lane_Info_AliveCtr "Alive counter - Autosar E2E Profile 5";
CM_ SG_ 1230 Left_Lane_Info_TimeStamp "Map data timestamp for synchronization";
CM_ SG_ 1230 Left_Lane_Exists "Indicates if the lane exists";
CM_ SG_ 1230 Left_Lane_isOvertakeLane "Indicates if the lane is the overtake lane";
CM_ SG_ 1230 Left_Lane_Start_dx "Indicates when this lane starts";
CM_ SG_ 1230 Left_CurrentSpeedLimit "Current speed limit on the Ego Lane
159 indicates an unknown speed";
CM_ SG_ 1230 Left_CurrentSpeedLimit_Type "type of the speed limit";
CM_ SG_ 1230 Left_NextSpeedLimit_Value_1 "Next speed limit on left lane";
CM_ SG_ 1230 Left_NextSpeedLimit_Location_1 "Next speed limit location on left lane";
CM_ SG_ 1230 Left_NextSpeedLimit_Type_1 "type of the next speed limit";
CM_ SG_ 1230 Left_SpeedProfile_Far_N "Number of valid elements in speed profile";
CM_ SG_ 1230 Left_NextTopo_Loc_1 "Next location of topology change";
CM_ SG_ 1230 Left_NextTopo_Type_1 "Next type of topology change";
CM_ SG_ 1230 Left_NextTopo_Side_1 "Side of the next topology change";
CM_ SG_ 1230 Left_NextTopo_Side_2 "Side of the next topology change";
CM_ SG_ 1230 Left_NextTopo_Loc_3 "Next location of topology change";
CM_ SG_ 1230 Left_NextTopo_Type_3 "Next type of topology change";
CM_ SG_ 1230 Left_NextTopo_Side_3 "Side of the next topology change";
CM_ SG_ 1230 Left_NextTopo_Loc_4 "Next location of topology change";
CM_ SG_ 1230 Left_NextTopo_Type_4 "Next type of topology change";
CM_ SG_ 1230 Left_NextTopo_Side_4 "Side of the next topology change";
BA_DEF_ SG_  "GenSigSendType" ENUM  "Cyclic","OnWrite","OnWriteWithRepetition","OnChange","OnChangeWithRepetition","IfActive","IfActiveWithRepetition";
BA_DEF_ BO_  "GenMsgCycleTimeFast" INT 2 50000;
BA_DEF_ BO_  "GenMsgILSupport" ENUM  "No","Yes";
BA_DEF_ BU_  "NodeLayerModules" STRING ;
BA_DEF_ BU_  "ILUsed" ENUM  "No","Yes";
BA_DEF_  "NmBaseAddress" HEX 1024 1087;
BA_DEF_ BO_  "CANFD_BRS" ENUM  "0","1";
BA_DEF_ BO_  "GenMsgCycleTime" INT 0 65535;
BA_DEF_ BO_  "GenMsgSendType" ENUM  "cyclic","NoMsgSendType";
BA_DEF_ BO_  "VFrameFormat" ENUM  "StandardCAN","ExtendedCAN","reserved","reserved","reserved","reserved","reserved","reserved","reserved","reserved","reserved","reserved","reserved","reserved","StandardCAN_FD","ExtendedCAN_FD";
BA_DEF_ SG_  "GenSigStartValue" FLOAT 0 100000000000;
BA_DEF_  "BusType" STRING ;
BA_DEF_  "DBName" STRING ;
BA_DEF_ SG_  "SystemSignalLongSymbol" STRING ;
BA_DEF_DEF_  "GenSigSendType" "Cyclic";
BA_DEF_DEF_  "GenMsgCycleTimeFast" 100;
BA_DEF_DEF_  "GenMsgILSupport" "Yes";
BA_DEF_DEF_  "NodeLayerModules" "CANoeILNLVector.dll";
BA_DEF_DEF_  "ILUsed" "Yes";
BA_DEF_DEF_  "NmBaseAddress" 1024;
BA_DEF_DEF_  "CANFD_BRS" "1";
BA_DEF_DEF_  "GenMsgCycleTime" 0;
BA_DEF_DEF_  "GenMsgSendType" "";
BA_DEF_DEF_  "VFrameFormat" "";
BA_DEF_DEF_  "GenSigStartValue" 0;
BA_DEF_DEF_  "BusType" "";
BA_DEF_DEF_  "DBName" "ChooseYourNameHere";
BA_DEF_DEF_  "SystemSignalLongSymbol" "";
BA_ "BusType" "CAN FD";
BA_ "DBName" "OD_ADAS_Public_CANFD";
BA_ "GenMsgCycleTime" BO_ 1970 5000;
BA_ "GenMsgSendType" BO_ 1970 0;
BA_ "VFrameFormat" BO_ 1970 14;
BA_ "GenMsgSendType" BO_ 1983 0;
BA_ "GenMsgCycleTime" BO_ 1983 5000;
BA_ "VFrameFormat" BO_ 1983 14;
BA_ "GenMsgSendType" BO_ 1969 0;
BA_ "GenMsgCycleTime" BO_ 1969 5000;
BA_ "VFrameFormat" BO_ 1969 14;
BA_ "GenMsgSendType" BO_ 1968 0;
BA_ "GenMsgCycleTime" BO_ 1968 5000;
BA_ "VFrameFormat" BO_ 1968 14;
BA_ "GenMsgSendType" BO_ 1793 1;
BA_ "VFrameFormat" BO_ 1793 14;
BA_ "GenMsgSendType" BO_ 1792 1;
BA_ "VFrameFormat" BO_ 1792 14;
BA_ "GenMsgSendType" BO_ 30 0;
BA_ "GenMsgCycleTime" BO_ 30 500;
BA_ "VFrameFormat" BO_ 30 14;
BA_ "GenMsgSendType" BO_ 1225 0;
BA_ "GenMsgCycleTime" BO_ 1225 40;
BA_ "VFrameFormat" BO_ 1225 14;
BA_ "GenMsgSendType" BO_ 1224 0;
BA_ "GenMsgCycleTime" BO_ 1224 40;
BA_ "VFrameFormat" BO_ 1224 14;
BA_ "GenMsgSendType" BO_ 1441 0;
BA_ "GenMsgCycleTime" BO_ 1441 500;
BA_ "VFrameFormat" BO_ 1441 14;
BA_ "GenMsgSendType" BO_ 1440 0;
BA_ "GenMsgCycleTime" BO_ 1440 500;
BA_ "VFrameFormat" BO_ 1440 14;
BA_ "GenMsgSendType" BO_ 1791 0;
BA_ "GenMsgCycleTime" BO_ 1791 1000;
BA_ "VFrameFormat" BO_ 1791 14;
BA_ "GenMsgSendType" BO_ 291 0;
BA_ "GenMsgCycleTime" BO_ 291 20;
BA_ "VFrameFormat" BO_ 291 14;
BA_ "GenMsgSendType" BO_ 842 0;
BA_ "GenMsgCycleTime" BO_ 842 50;
BA_ "VFrameFormat" BO_ 842 14;
BA_ "GenMsgSendType" BO_ 1184 0;
BA_ "GenMsgCycleTime" BO_ 1184 100;
BA_ "VFrameFormat" BO_ 1184 14;
BA_ "GenMsgSendType" BO_ 1200 0;
BA_ "GenMsgCycleTime" BO_ 1200 100;
BA_ "VFrameFormat" BO_ 1200 14;
BA_ "GenMsgSendType" BO_ 1210 0;
BA_ "GenMsgCycleTime" BO_ 1210 50;
BA_ "VFrameFormat" BO_ 1210 14;
BA_ "GenMsgSendType" BO_ 1211 0;
BA_ "GenMsgCycleTime" BO_ 1211 50;
BA_ "VFrameFormat" BO_ 1211 14;
BA_ "GenMsgSendType" BO_ 1212 0;
BA_ "GenMsgCycleTime" BO_ 1212 50;
BA_ "VFrameFormat" BO_ 1212 14;
BA_ "GenMsgSendType" BO_ 1213 0;
BA_ "GenMsgCycleTime" BO_ 1213 50;
BA_ "VFrameFormat" BO_ 1213 14;
BA_ "GenMsgSendType" BO_ 1625 0;
BA_ "GenMsgCycleTime" BO_ 1625 1000;
BA_ "VFrameFormat" BO_ 1625 14;
BA_ "VFrameFormat" BO_ 262 0;
BA_ "GenMsgSendType" BO_ 262 0;
BA_ "GenMsgCycleTime" BO_ 262 5000;
BA_ "VFrameFormat" BO_ 257 0;
BA_ "GenMsgSendType" BO_ 257 0;
BA_ "GenMsgCycleTime" BO_ 257 500;
BA_ "VFrameFormat" BO_ 261 0;
BA_ "GenMsgSendType" BO_ 261 0;
BA_ "GenMsgCycleTime" BO_ 261 500;
BA_ "VFrameFormat" BO_ 260 0;
BA_ "GenMsgSendType" BO_ 260 0;
BA_ "GenMsgCycleTime" BO_ 260 500;
BA_ "VFrameFormat" BO_ 258 0;
BA_ "GenMsgSendType" BO_ 258 0;
BA_ "GenMsgCycleTime" BO_ 258 4000;
BA_ "VFrameFormat" BO_ 259 0;
BA_ "GenMsgSendType" BO_ 259 0;
BA_ "GenMsgCycleTime" BO_ 259 500;
BA_ "GenMsgSendType" BO_ 449 0;
BA_ "GenMsgCycleTime" BO_ 449 10;
BA_ "VFrameFormat" BO_ 449 14;
BA_ "VFrameFormat" BO_ 272 0;
BA_ "GenMsgSendType" BO_ 272 0;
BA_ "GenMsgCycleTime" BO_ 272 500;
BA_ "GenMsgSendType" BO_ 443 0;
BA_ "GenMsgCycleTime" BO_ 443 10;
BA_ "VFrameFormat" BO_ 443 14;
BA_ "GenMsgSendType" BO_ 432 0;
BA_ "GenMsgCycleTime" BO_ 432 20;
BA_ "VFrameFormat" BO_ 432 14;
BA_ "GenMsgSendType" BO_ 658 0;
BA_ "GenMsgCycleTime" BO_ 658 20;
BA_ "VFrameFormat" BO_ 658 14;
BA_ "GenMsgSendType" BO_ 672 0;
BA_ "GenMsgCycleTime" BO_ 672 20;
BA_ "VFrameFormat" BO_ 672 14;
BA_ "GenMsgSendType" BO_ 1368 0;
BA_ "GenMsgCycleTime" BO_ 1368 100;
BA_ "VFrameFormat" BO_ 1368 14;
BA_ "GenMsgSendType" BO_ 821 0;
BA_ "GenMsgCycleTime" BO_ 821 50;
BA_ "VFrameFormat" BO_ 821 14;
BA_ "GenMsgSendType" BO_ 835 0;
BA_ "GenMsgCycleTime" BO_ 835 50;
BA_ "VFrameFormat" BO_ 835 14;
BA_ "GenMsgSendType" BO_ 784 0;
BA_ "GenMsgCycleTime" BO_ 784 20;
BA_ "VFrameFormat" BO_ 784 14;
BA_ "GenMsgSendType" BO_ 604 0;
BA_ "GenMsgCycleTime" BO_ 604 20;
BA_ "VFrameFormat" BO_ 604 14;
BA_ "GenMsgSendType" BO_ 606 0;
BA_ "GenMsgCycleTime" BO_ 606 20;
BA_ "VFrameFormat" BO_ 606 14;
BA_ "GenMsgSendType" BO_ 824 0;
BA_ "GenMsgCycleTime" BO_ 824 50;
BA_ "VFrameFormat" BO_ 824 14;
BA_ "GenMsgSendType" BO_ 826 0;
BA_ "GenMsgCycleTime" BO_ 826 50;
BA_ "VFrameFormat" BO_ 826 14;
BA_ "GenMsgSendType" BO_ 1958 1;
BA_ "VFrameFormat" BO_ 1958 14;
BA_ "GenMsgSendType" BO_ 1966 1;
BA_ "VFrameFormat" BO_ 1966 14;
BA_ "GenMsgSendType" BO_ 800 0;
BA_ "GenMsgCycleTime" BO_ 800 50;
BA_ "VFrameFormat" BO_ 800 14;
BA_ "GenMsgSendType" BO_ 883 0;
BA_ "GenMsgCycleTime" BO_ 883 100;
BA_ "VFrameFormat" BO_ 883 14;
BA_ "GenMsgSendType" BO_ 1410 0;
BA_ "GenMsgCycleTime" BO_ 1410 100;
BA_ "VFrameFormat" BO_ 1410 14;
BA_ "GenMsgSendType" BO_ 1228 0;
BA_ "GenMsgCycleTime" BO_ 1228 100;
BA_ "VFrameFormat" BO_ 1228 14;
BA_ "GenMsgSendType" BO_ 1229 0;
BA_ "GenMsgCycleTime" BO_ 1229 100;
BA_ "VFrameFormat" BO_ 1229 14;
BA_ "GenMsgSendType" BO_ 1230 0;
BA_ "GenMsgCycleTime" BO_ 1230 100;
BA_ "VFrameFormat" BO_ 1230 14;
BA_ "GenSigStartValue" SG_ 1983 DBC_VersionIdMinor 17;
BA_ "GenSigStartValue" SG_ 1983 DBC_VersionIdMajor 2;
BA_ "GenSigStartValue" SG_ 1225 EHR_LOC_POSE_LONG 1800000000;
BA_ "GenSigStartValue" SG_ 1225 EHR_LOC_POSE_LAT 900000000;
BA_ "GenSigStartValue" SG_ 1224 EHR_GNSS_POS_LONG 1800000000;
BA_ "GenSigStartValue" SG_ 1224 EHR_GNSS_POS_LAT 900000000;
BA_ "GenSigStartValue" SG_ 291 ADAS_LimAx_LIM 31496;
BA_ "SystemSignalLongSymbol" SG_ 1184 ACCplusActivationSubfeatureFrict "ACCplusActivationSubfeatureFriction";
BA_ "SystemSignalLongSymbol" SG_ 1184 ADCDriverInputActivationDeactiva "ADCDriverInputActivationDeactivation";
BA_ "SystemSignalLongSymbol" SG_ 1200 ACCplusIsActiveSubfeatureFrictio "ACCplusIsActiveSubfeatureFriction";
BA_ "SystemSignalLongSymbol" SG_ 1200 FrontCollisionWarningSensit_0000 "FrontCollisionWarningSensitivitySelection";
BA_ "GenSigStartValue" SG_ 1210 NeighboringVehicle1X 42;
BA_ "GenSigStartValue" SG_ 1210 NeighboringVehicle2X 42;
BA_ "GenSigStartValue" SG_ 1210 NeighboringVehicle3X 42;
BA_ "GenSigStartValue" SG_ 1210 NeighboringVehicle4X 42;
BA_ "GenSigStartValue" SG_ 1210 NeighboringVehicle5X 42;
BA_ "GenSigStartValue" SG_ 1210 NeighboringVehicle6X 42;
BA_ "GenSigStartValue" SG_ 1210 NeighboringVehicle7X 42;
BA_ "GenSigStartValue" SG_ 1210 NeighboringVehicle8X 42;
BA_ "GenSigStartValue" SG_ 1212 ADAS_Curv_1_dy_00 256;
BA_ "GenSigStartValue" SG_ 1212 ADAS_Curv_1_dy_01 256;
BA_ "GenSigStartValue" SG_ 1212 ADAS_Curv_1_dy_02 256;
BA_ "GenSigStartValue" SG_ 1212 ADAS_Curv_1_dy_03 256;
BA_ "GenSigStartValue" SG_ 1212 ADAS_Curv_1_dy_04 256;
BA_ "GenSigStartValue" SG_ 1212 ADAS_Curv_1_dy_05 256;
BA_ "GenSigStartValue" SG_ 1212 ADAS_Curv_1_dy_06 256;
BA_ "GenSigStartValue" SG_ 1212 ADAS_Curv_1_dy_07 256;
BA_ "GenSigStartValue" SG_ 1212 ADAS_Curv_1_dy_08 256;
BA_ "GenSigStartValue" SG_ 1212 ADAS_Curv_1_dy_09 256;
BA_ "GenSigStartValue" SG_ 1212 ADAS_Curv_1_dy_10 256;
BA_ "GenSigStartValue" SG_ 1212 ADAS_Curv_1_dy_11 256;
BA_ "GenSigStartValue" SG_ 1212 ADAS_Curv_1_dy_12 256;
BA_ "GenSigStartValue" SG_ 1212 ADAS_Curv_1_dy_13 256;
BA_ "GenSigStartValue" SG_ 1212 ADAS_Curv_1_dy_14 256;
BA_ "GenSigStartValue" SG_ 1212 ADAS_Curv_1_dy_15 256;
BA_ "GenSigStartValue" SG_ 1212 ADAS_Curv_2_dy_00 256;
BA_ "GenSigStartValue" SG_ 1212 ADAS_Curv_2_dy_01 256;
BA_ "GenSigStartValue" SG_ 1212 ADAS_Curv_2_dy_02 256;
BA_ "GenSigStartValue" SG_ 1212 ADAS_Curv_2_dy_03 256;
BA_ "GenSigStartValue" SG_ 1212 ADAS_Curv_2_dy_04 256;
BA_ "GenSigStartValue" SG_ 1212 ADAS_Curv_2_dy_05 256;
BA_ "GenSigStartValue" SG_ 1212 ADAS_Curv_2_dy_06 256;
BA_ "GenSigStartValue" SG_ 1212 ADAS_Curv_2_dy_07 256;
BA_ "GenSigStartValue" SG_ 1212 ADAS_Curv_2_dy_08 256;
BA_ "GenSigStartValue" SG_ 1212 ADAS_Curv_2_dy_09 256;
BA_ "GenSigStartValue" SG_ 1212 ADAS_Curv_2_dy_10 256;
BA_ "GenSigStartValue" SG_ 1212 ADAS_Curv_2_dy_11 256;
BA_ "GenSigStartValue" SG_ 1212 ADAS_Curv_2_dy_12 256;
BA_ "GenSigStartValue" SG_ 1212 ADAS_Curv_2_dy_13 256;
BA_ "GenSigStartValue" SG_ 1212 ADAS_Curv_2_dy_14 256;
BA_ "GenSigStartValue" SG_ 1212 ADAS_Curv_2_dy_15 256;
BA_ "GenSigStartValue" SG_ 1212 ADAS_Curv_3_dy_00 256;
BA_ "GenSigStartValue" SG_ 1212 ADAS_Curv_3_dy_01 256;
BA_ "GenSigStartValue" SG_ 1212 ADAS_Curv_3_dy_02 256;
BA_ "GenSigStartValue" SG_ 1212 ADAS_Curv_3_dy_03 256;
BA_ "GenSigStartValue" SG_ 1212 ADAS_Curv_3_dy_04 256;
BA_ "GenSigStartValue" SG_ 1212 ADAS_Curv_3_dy_05 256;
BA_ "GenSigStartValue" SG_ 1212 ADAS_Curv_3_dy_06 256;
BA_ "GenSigStartValue" SG_ 1212 ADAS_Curv_3_dy_07 256;
BA_ "GenSigStartValue" SG_ 1212 ADAS_Curv_3_dy_08 256;
BA_ "GenSigStartValue" SG_ 1212 ADAS_Curv_3_dy_09 256;
BA_ "GenSigStartValue" SG_ 1212 ADAS_Curv_3_dy_10 256;
BA_ "GenSigStartValue" SG_ 1212 ADAS_Curv_3_dy_11 256;
BA_ "GenSigStartValue" SG_ 1212 ADAS_Curv_3_dy_12 256;
BA_ "GenSigStartValue" SG_ 1212 ADAS_Curv_3_dy_13 256;
BA_ "GenSigStartValue" SG_ 1212 ADAS_Curv_3_dy_14 256;
BA_ "GenSigStartValue" SG_ 1212 ADAS_Curv_3_dy_15 256;
BA_ "GenSigStartValue" SG_ 1213 ADAS_Curv_4_dy_00 256;
BA_ "GenSigStartValue" SG_ 1213 ADAS_Curv_4_dy_01 256;
BA_ "GenSigStartValue" SG_ 1213 ADAS_Curv_4_dy_02 256;
BA_ "GenSigStartValue" SG_ 1213 ADAS_Curv_4_dy_03 256;
BA_ "GenSigStartValue" SG_ 1213 ADAS_Curv_4_dy_04 256;
BA_ "GenSigStartValue" SG_ 1213 ADAS_Curv_4_dy_05 256;
BA_ "GenSigStartValue" SG_ 1213 ADAS_Curv_4_dy_06 256;
BA_ "GenSigStartValue" SG_ 1213 ADAS_Curv_4_dy_07 256;
BA_ "GenSigStartValue" SG_ 1213 ADAS_Curv_4_dy_08 256;
BA_ "GenSigStartValue" SG_ 1213 ADAS_Curv_4_dy_09 256;
BA_ "GenSigStartValue" SG_ 1213 ADAS_Curv_4_dy_10 256;
BA_ "GenSigStartValue" SG_ 1213 ADAS_Curv_4_dy_11 256;
BA_ "GenSigStartValue" SG_ 1213 ADAS_Curv_4_dy_12 256;
BA_ "GenSigStartValue" SG_ 1213 ADAS_Curv_4_dy_13 256;
BA_ "GenSigStartValue" SG_ 1213 ADAS_Curv_4_dy_14 256;
BA_ "GenSigStartValue" SG_ 1213 ADAS_Curv_4_dy_15 256;
BA_ "GenSigStartValue" SG_ 1213 ADAS_Curv_RefLine_dy_00 256;
BA_ "GenSigStartValue" SG_ 1213 ADAS_Curv_RefLine_dy_01 256;
BA_ "GenSigStartValue" SG_ 1213 ADAS_Curv_RefLine_dy_02 256;
BA_ "GenSigStartValue" SG_ 1213 ADAS_Curv_RefLine_dy_03 256;
BA_ "GenSigStartValue" SG_ 1213 ADAS_Curv_RefLine_dy_04 256;
BA_ "GenSigStartValue" SG_ 1213 ADAS_Curv_RefLine_dy_05 256;
BA_ "GenSigStartValue" SG_ 1213 ADAS_Curv_RefLine_dy_06 256;
BA_ "GenSigStartValue" SG_ 1213 ADAS_Curv_RefLine_dy_07 256;
BA_ "GenSigStartValue" SG_ 1213 ADAS_Curv_RefLine_dy_08 256;
BA_ "GenSigStartValue" SG_ 1213 ADAS_Curv_RefLine_dy_09 256;
BA_ "GenSigStartValue" SG_ 1213 ADAS_Curv_RefLine_dy_10 256;
BA_ "GenSigStartValue" SG_ 1213 ADAS_Curv_RefLine_dy_11 256;
BA_ "GenSigStartValue" SG_ 1213 ADAS_Curv_RefLine_dy_12 256;
BA_ "GenSigStartValue" SG_ 1213 ADAS_Curv_RefLine_dy_13 256;
BA_ "GenSigStartValue" SG_ 1213 ADAS_Curv_RefLine_dy_14 256;
BA_ "GenSigStartValue" SG_ 1213 ADAS_Curv_RefLine_dy_15 256;
BA_ "GenSigStartValue" SG_ 449 ADAS_RdWhlAgReq 9000;
BA_ "GenSigStartValue" SG_ 449 ADAS_ExtMaxRPCTrq 1024;
BA_ "GenSigStartValue" SG_ 449 ADAS_ExtMinRPCTrq 1024;
BA_ "GenSigStartValue" SG_ 443 WhlTqMin 32768;
BA_ "GenSigStartValue" SG_ 883 ECC_OutdT 48;
BA_ "GenSigStartValue" SG_ 1410 ECC_InsdT 48;
VAL_ 1225 EHR_LOC_Status 0 "ESTIMATE_STATUS_UNKNOWN" 1 "ESTIMATE_STATUS_OK" 2 "ESTIMATE_STATUS_LOW" 3 "ESTIMATE_STATUS_CONVERGING" 4 "ESTIMATE_STATUS_ERROR" 5 "ESTIMATE_STATUS_OUT_OF_RANGE" ;
VAL_ 1441 VIC_Status 0 "VIC not available" 1 "VIC available" ;
VAL_ 1440 AEB_Status 0 "AEB not available" 1 "AEB available" ;
VAL_ 1791 Vehicle_Variant 0 "Golf" 1 "Defender" 2 "reserved" 3 "reserved" 4 "reserved" 5 "reserved" 6 "reserved" 7 "reserved" 8 "reserved" 9 "reserved" 10 "reserved" 11 "reserved" 12 "reserved" 13 "reserved" 14 "reserved" 15 "reserved" ;
VAL_ 291 ADAS_VehSecureReq 0 "normal" 1 "secure" 2 "secure_lock" 3 "reserved" ;
VAL_ 291 ADAS_ShtDwnStrat_ACC 0 "Immediate" 1 "Soft" 2 "Fast" 3 "StandStillOff" ;
VAL_ 291 ADAS_ShtDwnStrat_Lim 0 "Immediate" 1 "Soft" 2 "Fast" 3 "StandStillOff" ;
VAL_ 291 ADAS_LimActReq 0 "Ax Limit not active" 1 "Ax Limit active" ;
VAL_ 291 ADAS_EngStartRun_Req 0 "No Request" 1 "Request" ;
VAL_ 291 ADAS_CoastReq_ACC 0 "No Request" 1 "Request" ;
VAL_ 291 ADAS_Sts_LIM 0 "Off" 1 "Standby" 2 "EST Active_Control" 3 "Override" 4 "temp_Failure" 5 "perm. Failure" 6 "ADC_Active_Control" 7 "ADC_Override" ;
VAL_ 291 ACC_Minimale_Bremsung_D 0 "Anford_Min_Bremsung_nicht_aktiv" 1 "Anford_Min_Bremsung_aktiv" ;
VAL_ 842 ADAS_Sts_HWA 0 "Off" 1 "Passive" 2 "Standby" 3 "Active" 4 "Fault" 5 "Reserved" 6 "Reserved" 7 "Reserved" ;
VAL_ 842 ADAS_HiwayExitAuxSts 0 "Off" 1 "Passive" 2 "Standby" 3 "Active" 4 "Fault" 5 "Reserved" 6 "Reserved" 7 "Reserved" ;
VAL_ 842 ADAS_ActvBtnDispReq_HEA 0 "No Request" 1 "Request" 2 "Flash" 3 "Reserved" ;
VAL_ 842 ADAS_Sts_ALC 0 "No Ready" 1 "Ready" 2 "Active" 3 "Return To Lane By Driver" 4 "Return To Lane By System" 5 "Manual Override" 6 "Failure" 7 "Reserved" 8 "Reserved" 9 "Reserved" 10 "Reserved" 11 "Reserved" 12 "Reserved" 13 "Reserved" 14 "Reserved" 15 "Reserved" ;
VAL_ 842 ADAS_HandsOffTakeOverReq_ALC 0 "Inactive" 1 "Active" ;
VAL_ 842 ADAS_OverMod_ALC 0 "No Override" 1 "Driver Override" ;
VAL_ 842 ADAS_ALCAudioWarnLe 0 "No Warning" 1 "Warning" ;
VAL_ 842 ADAS_LCReturnToLane 0 "No Display" 1 "Display" 2 "Reserved" 3 "Reserved" ;
VAL_ 842 ADAS_LeLaneOccupied 0 "No Obj" 1 "Not Active By Obj" ;
VAL_ 842 ADAS_RiLaneOccupied 0 "No Obj" 1 "Not Active By Obj" ;
VAL_ 842 ADAS_LeLCArrow 0 "No Display" 1 "Display Gray" 2 "Display Green" 3 "Reserved" ;
VAL_ 842 ADAS_ALCAudioWarnRi 0 "No Warning" 1 "Warning" ;
VAL_ 842 ADAS_LeLaneOccupiedWarn 0 "No Display" 1 "Display" ;
VAL_ 842 ADAS_RiLaneOccupiedWarn 0 "No Display" 1 "Display" ;
VAL_ 842 ADAS_ALCTakeOverReq 0 "Inactive" 1 "Active" ;
VAL_ 842 ADAS_LCSysFlt 0 "No Failure" 1 "Failure" ;
VAL_ 842 ADAS_TurnLampOff 0 "No Request" 1 "Please turn off your left turn signal." 2 "Please turn off your right turn signal." 3 "Reserved" ;
VAL_ 842 ADAS_CtrlrFlt 0 "No Failure" 1 "Reversible Failure" 2 "Irrversible Failure" 3 "Reserved" ;
VAL_ 842 ADAS_RiLCArrow 0 "No Display" 1 "Display Gray" 2 "Display Green" 3 "Reserved" ;
VAL_ 842 ADAS_Sts_ESS 0 "Off" 1 "Reserved" 2 "Standby" 3 "Active" 4 "Fault" 5 "Reserved" 6 "Reserved" 7 "Reserved" ;
VAL_ 842 ADAS_Warn_ESS 0 "No Warning" 1 "Warning Left" 2 "Warning Right" 3 "Reserved" ;
VAL_ 842 ADAS_DrvrOccpyReq 0 "No Request" 1 "Request" ;
VAL_ 1184 MainSwitchACC 0 "Not pressed" 1 "Pressed" ;
VAL_ 1184 MainSwitchADC 0 "Not pressed" 1 "Pressed" ;
VAL_ 1184 MainSwitchACCplus 0 "Not pressed" 1 "Pressed" ;
VAL_ 1184 MainSwitchTLR 0 "Not pressed" 1 "Pressed" ;
VAL_ 1184 ACCplusActivationSubfeature_SLA 0 "Not pressed" 1 "Pressed" ;
VAL_ 1184 ACCplusActivationSubfeatureCSA 0 "Not pressed" 1 "Pressed" ;
VAL_ 1184 ACCplusActivationSubfeatureSPA 0 "Not pressed" 1 "Pressed" ;
VAL_ 1184 ACCplusActivationSubfeatureFrict 0 "Not pressed" 1 "Pressed" ;
VAL_ 1184 ACCDriverInputTimeGapChange 0 "Not pressed" 1 "Pressed" ;
VAL_ 1184 ACCDriverInputSet 0 "Not pressed" 1 "Pressed" ;
VAL_ 1184 ACCDriverInputResume 0 "Not pressed" 1 "Pressed" ;
VAL_ 1184 ACCDriverInputSetSpeedDecrease 0 "Not pressed" 1 "Pressed" ;
VAL_ 1184 ACCDriverInputSetSpeedIncrease 0 "Not pressed" 1 "Pressed" ;
VAL_ 1184 ACCDriverInputConfirmation 0 "Not pressed" 1 "Pressed" ;
VAL_ 1184 ADCVariantSelection 0 "ADC_Selection_Variant_Base" 1 "ADC_Selection_Variant_Plus" 2 "ADC_Selection_Variant_Demo1" 3 "ADC_Selection_Variant_Demo2" 4 "Reserved4" 5 "Reserved5" 6 "Reserved6" 7 "Reserved7" ;
VAL_ 1184 ADCDriverInputActivationDeactiva 0 "Not pressed" 1 "Pressed" ;
VAL_ 1184 ACFDrivingMode 0 "Normal" 1 "ECO" 2 "Sport" 3 "Comfort" 4 "Dynamic" 5 "Reserved5" 6 "Reserved6" 7 "Reserved7" ;
VAL_ 1184 FrontCollisionWarningSensitivity 0 "Low" 1 "High" 2 "Mid" 3 "Reserved" ;
VAL_ 1200 IsAvailableACCplus0 0 "Not available" 1 "Available" ;
VAL_ 1200 IsAvailableADC 0 "Not available" 1 "Available" ;
VAL_ 1200 IsAvailableACCplus1 0 "Not available" 1 "Available" ;
VAL_ 1200 IsAvailableTLR 0 "Not available" 1 "Available" ;
VAL_ 1200 IsActiveACC 0 "Not active" 1 "Active" ;
VAL_ 1200 IsActiveADC 0 "Not active" 1 "Active" ;
VAL_ 1200 IsActiveACCplus 0 "Not active" 1 "Active" ;
VAL_ 1200 IsActiveTLR 0 "Not active" 1 "Active" ;
VAL_ 1200 ACCplusIsActiveSubfeatureSLA 0 "Not active" 1 "Active" ;
VAL_ 1200 ACCplusIsActiveSubfeatureCSA 0 "Not active" 1 "Active" ;
VAL_ 1200 ACCplusIsActiveSubfeatureSPA 0 "Not active" 1 "Active" ;
VAL_ 1200 ACCplusIsActiveSubfeatureFrictio 0 "Not active" 1 "Active" ;
VAL_ 1200 SelectedADCVariant 0 "ADC_IsSelected_Variant_Base" 1 "ADC_IsSelected_Variant_Plus" 2 "ADC_IsSelected_Variant_Demo1" 3 "ADC_IsSelected_Variant_Demo2" 4 "Reserved4" 5 "Reserved5" 6 "Reserved6" 7 "Reserved7" ;
VAL_ 1200 SelectedACFDrivingMode 0 "Normal" 1 "ECO" 2 "Sport" 3 "Comfort" 4 "Dynamic" 5 "Reserved5" 6 "Reserved6" 7 "Reserved7" ;
VAL_ 1200 FrontCollisionWarningSensit_0000 0 "Low" 1 "High" 2 "Mid" 3 "Reserved" ;
VAL_ 1210 TurnIndicatorSignal 0 "Off" 1 "Left" 2 "Right" 3 "Hazard light" ;
VAL_ 1210 AlcPremiumState 0 "Off" 1 "Available" 2 "Stand-By" 3 "In-Progress / Active" ;
VAL_ 1210 AlcPlusState 0 "Off" 1 "Available" 2 "Stand-By" 3 "In-Progress / Active" ;
VAL_ 1210 AlcEnhancedStatus 0 "Off" 1 "Available" 2 "Stand-By" 3 "In-Progress / Active" ;
VAL_ 1210 LKAStatus 0 "0x00: off" 1 "0x01: passive" 2 "0x02: available both sides" 3 "0x03: available left only" 4 "0x04: available right only" 5 "0x05: active control" 6 "0x06: active control left" 7 "0x07: active control right" 8 "0x08: failure" 9 "0x09: blindness" 10 "0x10: not coded" 11 "ReservedB" 12 "ReservedC" 13 "ReservedD" 14 "ReservedE" 15 "ReservedF" ;
VAL_ 1210 LDWStatus 0 "0x00: off" 1 "0x01: passive" 2 "0x02: available both sides" 3 "0x03: available left only" 4 "0x04: available right only" 5 "0x05: active control" 6 "0x06: active control left" 7 "0x07: active control right" 8 "0x08: failure" 9 "0x09: blindness" 10 "0x10: not coded" 11 "ReservedB" 12 "ReservedC" 13 "ReservedD" 14 "ReservedE" 15 "ReservedF" ;
VAL_ 1210 ELKSLStatus 0 "0x00: off" 1 "0x01: passive" 2 "0x02: available both sides" 3 "0x03: available left only" 4 "0x04: available right only" 5 "0x05: active control" 6 "0x06: active control left" 7 "0x07: active control right" 8 "0x08: failure" 9 "0x09: blindness" 10 "0x10: not coded" 11 "ReservedB" 12 "ReservedC" 13 "ReservedD" 14 "ReservedE" 15 "ReservedF" ;
VAL_ 1210 ELKHREStatus 0 "0x00: off" 1 "0x01: passive" 2 "0x02: available both sides" 3 "0x03: available left only" 4 "0x04: available right only" 5 "0x05: active control" 6 "0x06: active control left" 7 "0x07: active control right" 8 "0x08: failure" 9 "0x09: blindness" 10 "0x10: not coded" 11 "ReservedB" 12 "ReservedC" 13 "ReservedD" 14 "ReservedE" 15 "ReservedF" ;
VAL_ 1210 ELKVREStatus 0 "0x00: off" 1 "0x01: passive" 2 "0x02: available both sides" 3 "0x03: available left only" 4 "0x04: available right only" 5 "0x05: active control" 6 "0x06: active control left" 7 "0x07: active control right" 8 "0x08: failure" 9 "0x09: blindness" 10 "0x10: not coded" 11 "ReservedB" 12 "ReservedC" 13 "ReservedD" 14 "ReservedE" 15 "ReservedF" ;
VAL_ 1210 ELKOTStatus 0 "0x00: off" 1 "0x01: passive" 2 "0x02: available both sides" 3 "0x03: available left only" 4 "0x04: available right only" 5 "0x05: active control" 6 "0x06: active control left" 7 "0x07: active control right" 8 "0x08: failure" 9 "0x09: blindness" 10 "0x10: not coded" 11 "ReservedB" 12 "ReservedC" 13 "ReservedD" 14 "ReservedE" 15 "ReservedF" ;
VAL_ 1210 ELKOCVStatus 0 "0x00: off" 1 "0x01: passive" 2 "0x02: available both sides" 3 "0x03: available left only" 4 "0x04: available right only" 5 "0x05: active control" 6 "0x06: active control left" 7 "0x07: active control right" 8 "0x08: failure" 9 "0x09: blindness" 10 "0x10: not coded" 11 "ReservedB" 12 "ReservedC" 13 "ReservedD" 14 "ReservedE" 15 "ReservedF" ;
VAL_ 1210 OffsetReason 0 "undefined" 1 "Truck" 2 "Guard Rail" 3 "Urban" 4 "Rescue Alley" 5 "Reserved5" 6 "Reserved6" 7 "Reserved7" 8 "Reserved8" 9 "Reserved9" 10 "ReservedA" 11 "ReservedB" 12 "ReservedC" 13 "ReservedD" 14 "ReservedE" 15 "ReservedF" ;
VAL_ 1210 OffsetDirection 0 "not active" 1 "left" 2 "right" 3 "reserved" ;
VAL_ 1210 DisplayedLaneMarking4Y 1 "0x00...0x7F: distance left from ego center" 2 "0x80...0xFF: distance right from ego center" ;
VAL_ 1210 DisplayedLaneMarking3Y 1 "0x00...0x7F: distance left from ego center" 2 "0x80...0xFF: distance right from ego center" ;
VAL_ 1210 DisplayedLaneMarking2Y 1 "0x00...0x7F: distance left from ego center" 2 "0x80...0xFF: distance right from ego center" ;
VAL_ 1210 DisplayedLaneMarking1Y 1 "0x00...0x7F: distance left from ego center" 2 "0x80...0xFF: distance right from ego center" ;
VAL_ 1210 DisplayedLaneMarking4Type 0 "0x00: dashed line" 1 "0x01: solid line" 2 "0x02: verticalRoadEdge" 3 "0x03: horizontalRoadEdge" ;
VAL_ 1210 DisplayedLaneMarking3Type 0 "0x00: dashed line" 1 "0x01: solid line" 2 "0x02: verticalRoadEdge" 3 "0x03: horizontalRoadEdge" ;
VAL_ 1210 DisplayedLaneMarking2Type 0 "0x00: dashed line" 1 "0x01: solid line" 2 "0x02: verticalRoadEdge" 3 "0x03: horizontalRoadEdge" ;
VAL_ 1210 DisplayedLaneMarking1Type 0 "0x00: dashed line" 1 "0x01: solid line" 2 "0x02: verticalRoadEdge" 3 "0x03: horizontalRoadEdge" ;
VAL_ 1210 DisplayedLaneMarking4Color 0 "0x00: no display" 1 "0x01: gray" 2 "0x02: white" 3 "0x03: green" 4 "0x04: yellow" 5 "0x05: red" 6 "0x06: blue" 7 "0x07: red flashing" ;
VAL_ 1210 DisplayedLaneMarking3Color 0 "0x00: no display" 1 "0x01: gray" 2 "0x02: white" 3 "0x03: green" 4 "0x04: yellow" 5 "0x05: red" 6 "0x06: blue" 7 "0x07: red flashing" ;
VAL_ 1210 DisplayedLaneMarking2Color 0 "0x00: no display" 1 "0x01: gray" 2 "0x02: white" 3 "0x03: green" 4 "0x04: yellow" 5 "0x05: red" 6 "0x06: blue" 7 "0x07: red flashing" ;
VAL_ 1210 DisplayedLaneMarking1Color 0 "0x00: no display" 1 "0x01: gray" 2 "0x02: white" 3 "0x03: green" 4 "0x04: yellow" 5 "0x05: red" 6 "0x06: blue" 7 "0x07: red flashing" ;
VAL_ 1210 Indicator16 0 "no display" 1 "display icon" ;
VAL_ 1210 Indicator15 0 "no display" 1 "display icon" ;
VAL_ 1210 Indicator14 0 "no display" 1 "display icon" ;
VAL_ 1210 Indicator13 0 "no display" 1 "display icon" ;
VAL_ 1210 Indicator12 0 "no display" 1 "display icon" ;
VAL_ 1210 Indicator11 0 "no display" 1 "display icon" ;
VAL_ 1210 Indicator10 0 "no display" 1 "display icon" ;
VAL_ 1210 Indicator09 0 "no display" 1 "display icon" ;
VAL_ 1210 Indicator08 0 "no display" 1 "display icon" ;
VAL_ 1210 Indicator07 0 "no display" 1 "display icon" ;
VAL_ 1210 Indicator06 0 "no display" 1 "display icon" ;
VAL_ 1210 Indicator05 0 "no display" 1 "display icon" ;
VAL_ 1210 Indicator04 0 "no display" 1 "display icon" ;
VAL_ 1210 Indicator03 0 "no display" 1 "display icon" ;
VAL_ 1210 Indicator02 0 "no display" 1 "display icon" ;
VAL_ 1210 Indicator01 0 "no display" 1 "display icon" ;
VAL_ 1210 ACC_ICON_LADI 0 "Not shown" 1 "Shown" 2 "Blinking" ;
VAL_ 1210 CurvatureInformation 1 "0x00...0x3F: distance positive" 2 "0x40...0x7F: distance negative" ;
VAL_ 1210 TrafficSignSpeedLimit 1 "0x00: no speed limit" 2 "0x01...0x1E: value of speed limit" ;
VAL_ 1210 TrafficLightStatus 0 "red" 1 "yellow" 2 "green" 3 "blinking yellow" ;
VAL_ 1210 TrafficLightDisplayRequest 0 "no display" 1 "displayed - inactive (grey/opaque)" 2 "displayed - active" 3 "blinking" ;
VAL_ 1210 ACCTrafficLightReaction 0 "automatic speed/stop control (TICK)" 1 "manual confirmation for speed/stop control (SET)" 2 "function is unsure, no speed/stop control proposed" 3 "reserved" ;
VAL_ 1210 SensorConeFrontCenter 0 "0x00: no display" 1 "0x01: short cone gray" 2 "0x02: long cone gray" 3 "0x03: short cone red" ;
VAL_ 1210 NeighboringVehicle1VehicleType 0 "0x00: vehicle not present" 1 "0x01: passenger car" 2 "0x02: truck" 3 "0x03: motorbike" 4 "0x04: other" 5 "0x05: reserved" 6 "0x06: reserved" 7 "0x07: error" ;
VAL_ 1210 NeighboringVehicle1X 1 "0x00...0xFF: distance (positive values are left, negative values right from ego center)" ;
VAL_ 1210 NeighboringVehicle1Y 1 "0x00...0x7F: distance left from ego center" 2 "0x80...0xFF: distance right from ego center" ;
VAL_ 1210 NeighboringVehicle1AugmentedData 0 "0x00: normalDriving" 1 "0x01: selected as lead vehicle" 2 "0x02: located in ego blind spot" 3 "0x03: close distance to ego" 4 "0x04: strong deceleration" 5 "0x05: strong acceleration" 6 "0x06: lane change to left" 7 "0x07: lane change to right" ;
VAL_ 1210 NeighboringVehicle2VehicleType 0 "0x00: vehicle not present" 1 "0x01: passenger car" 2 "0x02: truck" 3 "0x03: motorbike" 4 "0x04: other" 5 "0x05: reserved" 6 "0x06: reserved" 7 "0x07: error" ;
VAL_ 1210 NeighboringVehicle2X 1 "0x00...0xFF: distance (positive values are left, negative values right from ego center)" ;
VAL_ 1210 NeighboringVehicle2Y 1 "0x00...0x7F: distance left from ego center" 2 "0x80...0xFF: distance right from ego center" ;
VAL_ 1210 NeighboringVehicle2AugmentedData 0 "0x00: normalDriving" 1 "0x01: selected as lead vehicle" 2 "0x02: located in ego blind spot" 3 "0x03: close distance to ego" 4 "0x04: strong deceleration" 5 "0x05: strong acceleration" 6 "0x06: lane change to left" 7 "0x07: lane change to right" ;
VAL_ 1210 NeighboringVehicle3VehicleType 0 "0x00: vehicle not present" 1 "0x01: passenger car" 2 "0x02: truck" 3 "0x03: motorbike" 4 "0x04: other" 5 "0x05: reserved" 6 "0x06: reserved" 7 "0x07: error" ;
VAL_ 1210 NeighboringVehicle3X 1 "0x00...0xFF: distance (positive values are left, negative values right from ego center)" ;
VAL_ 1210 NeighboringVehicle3Y 1 "0x00...0x7F: distance left from ego center" 2 "0x80...0xFF: distance right from ego center" ;
VAL_ 1210 NeighboringVehicle3AugmentedData 0 "0x00: normalDriving" 1 "0x01: selected as lead vehicle" 2 "0x02: located in ego blind spot" 3 "0x03: close distance to ego" 4 "0x04: strong deceleration" 5 "0x05: strong acceleration" 6 "0x06: lane change to left" 7 "0x07: lane change to right" ;
VAL_ 1210 NeighboringVehicle4VehicleType 0 "0x00: vehicle not present" 1 "0x01: passenger car" 2 "0x02: truck" 3 "0x03: motorbike" 4 "0x04: other" 5 "0x05: reserved" 6 "0x06: reserved" 7 "0x07: error" ;
VAL_ 1210 NeighboringVehicle4X 1 "0x00...0xFF: distance (positive values are left, negative values right from ego center)" ;
VAL_ 1210 NeighboringVehicle4Y 1 "0x00...0x7F: distance left from ego center" 2 "0x80...0xFF: distance right from ego center" ;
VAL_ 1210 NeighboringVehicle4AugmentedData 0 "0x00: normalDriving" 1 "0x01: selected as lead vehicle" 2 "0x02: located in ego blind spot" 3 "0x03: close distance to ego" 4 "0x04: strong deceleration" 5 "0x05: strong acceleration" 6 "0x06: lane change to left" 7 "0x07: lane change to right" ;
VAL_ 1210 NeighboringVehicle5VehicleType 0 "0x00: vehicle not present" 1 "0x01: passenger car" 2 "0x02: truck" 3 "0x03: motorbike" 4 "0x04: other" 5 "0x05: reserved" 6 "0x06: reserved" 7 "0x07: error" ;
VAL_ 1210 NeighboringVehicle5X 1 "0x00...0xFF: distance (positive values are left, negative values right from ego center)" ;
VAL_ 1210 NeighboringVehicle5Y 1 "0x00...0x7F: distance left from ego center" 2 "0x80...0xFF: distance right from ego center" ;
VAL_ 1210 NeighboringVehicle5AugmentedData 0 "0x00: normalDriving" 1 "0x01: selected as lead vehicle" 2 "0x02: located in ego blind spot" 3 "0x03: close distance to ego" 4 "0x04: strong deceleration" 5 "0x05: strong acceleration" 6 "0x06: lane change to left" 7 "0x07: lane change to right" ;
VAL_ 1210 NeighboringVehicle6VehicleType 0 "0x00: vehicle not present" 1 "0x01: passenger car" 2 "0x02: truck" 3 "0x03: motorbike" 4 "0x04: other" 5 "0x05: reserved" 6 "0x06: reserved" 7 "0x07: error" ;
VAL_ 1210 NeighboringVehicle6X 1 "0x00...0xFF: distance (positive values are left, negative values right from ego center)" ;
VAL_ 1210 LedHadState 0 "offState" 1 "initState" 2 "passiveState" 3 "readyState" 4 "requestState" 5 "activeControlState" 6 "activePreWarningState" 7 "handsOnState" 8 "takeOverRequestState" 9 "takeOverRequestEmergencyState" 10 "minimalRiskManeuverState" 11 "reserved1" 12 "reserved2" 13 "reserved3" 14 "reserved4" 15 "reserved5" ;
VAL_ 1210 NeighboringVehicle6Y 1 "0x00...0x7F: distance left from ego center" 2 "0x80...0xFF: distance right from ego center" ;
VAL_ 1210 NeighboringVehicle6AugmentedData 0 "0x00: normalDriving" 1 "0x01: selected as lead vehicle" 2 "0x02: located in ego blind spot" 3 "0x03: close distance to ego" 4 "0x04: strong deceleration" 5 "0x05: strong acceleration" 6 "0x06: lane change to left" 7 "0x07: lane change to right" ;
VAL_ 1210 NeighboringVehicle7VehicleType 0 "0x00: vehicle not present" 1 "0x01: passenger car" 2 "0x02: truck" 3 "0x03: motorbike" 4 "0x04: other" 5 "0x05: reserved" 6 "0x06: reserved" 7 "0x07: error" ;
VAL_ 1210 NeighboringVehicle7X 1 "0x00...0xFF: distance (positive values are left, negative values right from ego center)" ;
VAL_ 1210 NeighboringVehicle7Y 1 "0x00...0x7F: distance left from ego center" 2 "0x80...0xFF: distance right from ego center" ;
VAL_ 1210 NeighboringVehicle7AugmentedData 0 "0x00: normalDriving" 1 "0x01: selected as lead vehicle" 2 "0x02: located in ego blind spot" 3 "0x03: close distance to ego" 4 "0x04: strong deceleration" 5 "0x05: strong acceleration" 6 "0x06: lane change to left" 7 "0x07: lane change to right" ;
VAL_ 1210 NeighboringVehicle8VehicleType 0 "0x00: vehicle not present" 1 "0x01: passenger car" 2 "0x02: truck" 3 "0x03: motorbike" 4 "0x04: other" 5 "0x05: reserved" 6 "0x06: reserved" 7 "0x07: error" ;
VAL_ 1210 HwaHfStatus 0 "0x00: no display" 1 "0x01: not availabe" 2 "0x02: available" 3 "0x03: active" 4 "0x04: longitudinal override" 5 "0x05: lateral override" 6 "0x06: error" 7 "0x07: reserved" ;
VAL_ 1210 NeighboringVehicle8X 1 "0x00...0xFF: distance (positive values are left, negative values right from ego center)" ;
VAL_ 1210 NeighboringVehicle8Y 1 "0x00...0x7F: distance left from ego center" 2 "0x80...0xFF: distance right from ego center" ;
VAL_ 1210 NeighboringVehicle8AugmentedData 0 "0x00: normalDriving" 1 "0x01: selected as lead vehicle" 2 "0x02: located in ego blind spot" 3 "0x03: close distance to ego" 4 "0x04: strong deceleration" 5 "0x05: strong acceleration" 6 "0x06: lane change to left" 7 "0x07: lane change to right" ;
VAL_ 1210 HwaHonStatus 0 "0x00: no display" 1 "0x01: not availabe" 2 "0x02: available" 3 "0x03: active" 4 "0x04: longitudinal override" 5 "0x05: lateral override" 6 "0x06: error" 7 "0x07: reserved" ;
VAL_ 1210 HwaAccStatus 0 "0x00: no display" 1 "0x01: not availabe" 2 "0x02: available" 3 "0x03: active" 4 "0x04: longitudinal override" 5 "0x05: lateral override" 6 "0x06: error" 7 "0x07: reserved" ;
VAL_ 1210 SetSpeed 1 "0...254: set speed" 2 "255: reserved" ;
VAL_ 1210 SetSpeedColor 0 "0x00: no display" 1 "0x01: gray" 2 "0x02: white" 3 "0x03: green" 4 "0x04: yellow" 5 "0x05: red" 6 "0x06: blue" 7 "0x07: reserved" ;
VAL_ 1210 DisplayedEgoSpeed 1 "0...254: set speed" 2 "255: reserved" ;
VAL_ 1210 DisplayedEgoSpeedColor 0 "0x00: no display" 1 "0x01: gray" 2 "0x02: white" 3 "0x03: green" 4 "0x04: yellow" 5 "0x05: red" 6 "0x06: blue" 7 "0x07: reserved" ;
VAL_ 1210 DisplayedLaneMarkingLeftType 0 "0x00: dashed line" 1 "0x01: solid line" 2 "0x02: neighboring lane blocked" 3 "0x03: reserved" ;
VAL_ 1210 DisplayedLaneMarkingLeftColor 0 "0x00: no display" 1 "0x01: gray" 2 "0x02: white" 3 "0x03: green" 4 "0x04: yellow" 5 "0x05: red" 6 "0x06: blue" 7 "0x07: red flashing" ;
VAL_ 1210 DisplayedLaneMarkingRightType 0 "0x00: dashed line" 1 "0x01: solid line" 2 "0x02: neighboring lane blocked" 3 "0x03: reserved" ;
VAL_ 1210 DisplayedLaneMarkingRightColor 0 "0x00: no display" 1 "0x01: gray" 2 "0x02: white" 3 "0x03: green" 4 "0x04: yellow" 5 "0x05: red" 6 "0x06: blue" 7 "0x07: red flashing" ;
VAL_ 1210 TimeGapSetValue 0 "0x00: time gap 0 (closest)" 1 "0x01: time gap 1" 2 "0x02: time gap 2" 3 "0x03: time gap 3" 4 "0x04: time gap 4" 5 "0x05: time gap 5 (farest)" 6 "0x06: reserved" 7 "0x07: reserved" ;
VAL_ 1210 TimeGapColor 0 "0x00: no display" 1 "0x01: gray" 2 "0x02: white" 3 "0x03: green" 4 "0x04: yellow" 5 "0x05: red" 6 "0x06: blue" 7 "0x07: red flashing" ;
VAL_ 1210 AdcStateInformation 0 "0x00: Off" 1 "0x01: Passive & Override" 2 "0x02: Active - No TO" 3 "0x03: Active - TO Detected" 4 "0x04: Active - TO Detected - Distance closer than threshold 1" 5 "0x05: Active - TO Detected - Distance closer than threshold 2" 6 "0x06: Take over request" 7 "0x07: Failure" ;
VAL_ 1210 EgoLaneChange 0 "0x00: normal driving" 1 "0x01: lane change intention" 2 "0x02: lane change in progress" 3 "0x03: lane change recommended" 4 "0x04: gap search in progress" 5 "0x05: reserved1" 6 "0x06: reserved2" 7 "0x07: driver override" ;
VAL_ 1210 DisplayedTextMessageId 0 "00: no display" 1 "01: Approaching unreleased highway section" 2 "02: Unreleased highway section" 3 "03: Approaching end of highway" 4 "04: Vehicle not on highway" 5 "05: Lane markings not present" 6 "06: Approaching end of lane" 7 "07: End of lane" 8 "08: Approaching narrow lane" 9 "09: Lane width too narrow" 10 "10: Approaching narrow curve" 11 "11: Narrow curve" 12 "12: Approaching tunnel" 13 "13: Tunnel" 14 "14: Approaching toll gate" 15 "15: Toll gates" 16 "16: Approaching highway exit" 17 "17: Highway exit" 18 "18: Please apply brakes!" 19 "19: Front vehicle too close" 20 "20: ESP intervention" 21 "21: ESP switched off" 22 "22: Sensor blocked" 23 "23: Reduce set speed" 24 "24: Above speed range" 25 "25: Wrong gear selected" 26 "26: Other driver assistance function active" 27 "27: Please focus on the road" 28 "28: Driver not focused on the road" 29 "29: Please take a break" 30 "30: Take a break" 31 "31: Camera unable to see face" 32 "32: Please fasten seatbelt!" 33 "33: Seatbelt unfastened" 34 "34: Open vehicle door" 35 "35: Please remain ready to intervene at all times" 36 "36: Driver must remain ready to intervene at all times" 37 "37: Please take over vehicle control" 38 "38: HWA handsfree not available" 39 "39: Vehicle stopping. Take over vehicle control!" 40 "40: Please put your hands on the wheel" 41 "41: Please put your hands on the wheel for lane change" 42 "42: SHWA not available" 43 "43: SHWA handsfree not available" 44 "44: Speed out of range remind" 45 "45: Please hold the steer" 46 "46: Welcome to HWA handsfree" 47 "47: Driver deactivation" 48 "48: HWA ready to activate" 49 "49: Handsfree not available due to prohibition" 50 "50: Neighbouring vehicle too close" 51 "51: Behave according to the intended system usage" 52 "52: Road condition insufficient" 53 "53: Video-Sensor blocked please clean windscreen" 54 "54: Adjacent lane obstructed! ALC disallowed" 55 "55: Activation conditions for ALC not fulfilled" 56 "56: ALC failure" 57 "57: Radar Sensor disturbed. Forward Safety functions not available" 58 "58: Radar Sensor blocked. Adaptive Cruise Control and Forward Safety Functions not available" 59 "59: Lane Systems Failure. - Please visit local car dealer." 60 "60: Safety and Comfort ADAS features not available. - Please clear windscreen." 61 "61: Lane Departure Warning active!" 62 "62: Emergency Lane Keeping - Road Edge Horizontal active!" 63 "63: Emergency Lane Keeping - Road Edge Vertical active!" 64 "64: Emergency Lane Keeping - Oncomming Vehicle active!" 65 "65: Emergency Lane Keeping - Road Edge Vertical active!" 66 "66: Emergency Lane Keeping - Overtaking Vehicle active!" 67 "67: Vehicle stopping in lane - Take over vehicle control!" 68 "68: Vehicle in near standstill - Take over vehicle control!" 69 "69: Vehicle secured in standstill - Take over vehicle control!" 70 "70: Frequent lane change area, - follow distance increased" 71 "71: Dynamic area passed, follow -  distance reset" 72 "72: BDA not available due to missing Video Sensor information" 73 "73: Strong Braking area, - follow distance increased" 74 "74: Roundabout ahead!" 75 "75: Lane change left\nTake over vehicle control!" 76 "76: Lane change right\nTake over vehicle control!" 77 "77: Stop sign ahead!\nDriver control might be required!" 78 "78: Speed bump ahead!\nDriver control might be required!" 79 "79: Traffic light ahead!\nDriver control might be required!" 80 "80: Railway crossing ahead!\nDriver control might be required!" 81 "81: Yield ahead!\nDriver control might be required!" 82 "82: Roundabout ahead!\nVehicle speed control in progress!" 83 "83: Friction change happened!" 84 "84: Cloud service not available for velocity control at highway zone!" 85 "85: Intersection with priority issue ahead!\nDriver control might be required!" 86 "86: Unknown warning ahead!\nDriver control might be required!" 87 "87: Pedestrian crossing ahead!\nDriver control might be required!" ;
VAL_ 1210 PopupTextMessage 0 "0x00: normal text notification (e.g. top middle of the cockpit screen)" 1 "0x01: displayed as prominent pop-up message in a box in the center of the cockpit" 2 "0x02: pop-up on the right side" 3 "0x03: pop-up on the left side" ;
VAL_ 1210 AudioNotificationId 0 "0x00: no sound notification" 1 "0x01: notification" 2 "0x02: warning" 3 "0x03: minimal risk maneuver (safe-stop)" ;
VAL_ 1210 AuxiliarySymbol 0 "no display" 1 "AEB symbol 1" 2 "AEB symbol 2" 3 "AEB symbol 3" 4 "AEB symbol 4" 5 "LADI symbol" 6 "Take over symbol" 7 "Take over symbol critical" 8 "ELK auxillary symbol left" 9 "ELK auxillary symbol right" 10 "Roundabout sign" 11 "Time gap far" 12 "Time gap close" 13 "Stop sign" 14 "Speed bump sign" 15 "Traffic light sign" 16 "Railway crossing sign" 17 "Yield sign" 18 "Friction icon" 19 "ACC+ cloud no connection" 20 "Intersection with priority sign" 21 "Unknown warning sign" 22 "Pedestrian crossing sign" ;
VAL_ 1210 EgoLaneAssignment 0 "0x00: emergeny lane" 1 "0x01: 1st next to emergency lane" 2 "0x02: 2nd next to emergency lane" 3 "0x03: 3rd next to emergency lane" ;
VAL_ 1210 TrafficLightDistance 0 "0m" 1 "10m" 2 "20m" 3 "30m" 4 "40m" 5 "50m" 6 "60m" 7 "70m" 8 "80m" 9 "90m" 10 "100m" 11 "150m" 12 "200m" 13 "250m" 14 "300m" 15 "no display" ;
VAL_ 262 ADAS_Meta_MsgType 0 "SNA" 1 "POSITION" 2 "SEGMENT" 3 "STUB" 4 "PROFILE_SHORT" 5 "PROFILE_LONG" 6 "META_DATA" 7 "RESERVED" ;
VAL_ 262 ADAS_Meta_MapProvider 0 "Unknown" 1 "NAVTEQ" 2 "TeleAtlas" 3 "Zenrin" 4 "Reserverd" 5 "Reserverd" 6 "Reserverd" 7 "SNA" ;
VAL_ 262 ADAS_Meta_HwVer 0 "Unknown" ;
VAL_ 262 ADAS_Meta_SpdUnits 0 "kilometers/hour" 1 "Miles/hour" ;
VAL_ 262 ADAS_Meta_DrvSide 0 "Left-side driving" 1 "Right-side driving" ;
VAL_ 262 ADAS_Meta_RegionCode 0 "Unknown" 32767 "SNA" ;
VAL_ 262 ADAS_Meta_CountryCode 0 "UNKNOWN" 276 "DEU" ;
VAL_ 257 ADAS_Posn_PosProbb 31 "Invalid" ;
VAL_ 257 ADAS_Posn_CurLane 0 "Unknown" 1 "Emergency lane" 2 "Single-lane road" 3 "Left-most lane" 4 "Right-most lane" 5 "Middle lane on 3+ lane road" 6 "Reserved" 7 "SNA" ;
VAL_ 257 ADAS_Posn_Spd 511 "UNKNOWN" ;
VAL_ 257 ADAS_Posn_RelHead 0 "In path direction" 1 "1.417 deg right from path dir" 126 "178.583 deg right" 127 "Opposite direction" 252 "178.583 deg left" 253 "1.417 deg left from path dir" 254 "Unknown" 255 "SNA" ;
VAL_ 257 ADAS_Posn_Age 510 "Older than 2545 ms" 511 "Invalid" ;
VAL_ 257 ADAS_Posn_PathIdx 0 "Unknown" 1 "Position not in digitized Area" 2 "Position not on-road" 3 "System not calibrated" 4 "Current Segment Attributes" 5 "Stub only" 6 "This Path" 7 "Reserved" ;
VAL_ 257 ADAS_Posn_Offset 8191 "invalid" ;
VAL_ 257 ADAS_Posn_MsgTyp 0 "SNA" 1 "POSITION" 2 "SEGMENT" 3 "STUB" 4 "PROFILE_SHORT" 5 "PROFILE_LONG" 6 "META_DATA" 7 "RESERVED" ;
VAL_ 261 ADAS_ProfLong_Update 0 "false" 1 "true" ;
VAL_ 261 ADAS_ProfLong_Retr 0 "false" 1 "true" ;
VAL_ 261 ADAS_ProfLong_PathIdx 0 "Unknown" 1 "Position not in digitized Area" 2 "Position not on-road" 3 "System not calibrated" 4 "Current Segment Attributes" 5 "Stub only" 6 "This Path" 7 "Reserved" ;
VAL_ 261 ADAS_ProfLong_Offset 8191 "invalid" ;
VAL_ 261 ADAS_ProfLong_MsgType 0 "SNA" 1 "POSITION" 2 "SEGMENT" 3 "STUB" 4 "PROFILE_SHORT" 5 "PROFILE_LONG" 6 "META_DATA" 7 "RESERVED" ;
VAL_ 261 ADAS_ProfLong_CtrlPoint 0 "false" 1 "true" ;
VAL_ 261 ADAS_ProfLong_ProfType 0 "Invalid" 1 "Longitude" 2 "Latitude" 3 "Reserved3" 4 "Reserved4" 5 "Reserved5" 6 "Reserved6" 7 "Reserved7" 8 "Reserved8" 9 "Reserved9" 10 "Reserved10" 11 "Reserved11" 12 "Reserved12" 13 "Reserved13" 14 "Reserved14" 15 "Reserved15" 16 "System_Specific" 17 "System_Specific" 18 "System_Specific" 19 "System_Specific" 20 "System_Specific" 21 "System_Specific" 22 "System_Specific" 23 "System_Specific" 24 "System_Specific" 25 "System_Specific" 26 "System_Specific" 27 "System_Specific" 28 "System_Specific" 29 "System_Specific" 30 "System_Specific" 31 "System_Specific" ;
VAL_ 260 ADAS_ProfShort_Update 0 "false" 1 "true" ;
VAL_ 260 ADAS_ProfShort_ProfType 0 "Invalid" 1 "Curvature" 2 "Route_Numbers" 3 "Slope_step" 4 "Slope_linear" 5 "Road_Accessibility_Bitfield" 6 "Road_Condition_Bitfield" 7 "Var_Spd_Sign_Posn_Bitfield" 8 "Heading_Change" 9 "Reserved9" 10 "Reserved10" 11 "Reserved11" 12 "Reserved12" 13 "Reserved13" 14 "Reserved14" 15 "Reserved15" 16 "System_Specific" 17 "System_Specific" 18 "System_Specific" 19 "System_Specific" 20 "System_Specific" 21 "System_Specific" 22 "System_Specific" 23 "System_Specific" 24 "System_Specific" 25 "System_Specific" 26 "System_Specific" 27 "System_Specific" 28 "System_Specific" 29 "System_Specific" 30 "System_Specific" 31 "System_Specific" ;
VAL_ 260 ADAS_ProfShort_Retr 0 "false" 1 "true" ;
VAL_ 260 ADAS_ProfShort_PathIdx 0 "Unknown" 1 "Position not in digitized Area" 2 "Position not on-road" 3 "System not calibrated" 4 "Current Segment Attributes" 5 "Stub only" 6 "This Path" 7 "Reserved" ;
VAL_ 260 ADAS_ProfShort_Offset 8191 "invalid" ;
VAL_ 260 ADAS_ProfShort_MsgType 0 "SNA" 1 "POSITION" 2 "SEGMENT" 3 "STUB" 4 "PROFILE_SHORT" 5 "PROFILE_LONG" 6 "META_DATA" 7 "RESERVED" ;
VAL_ 260 ADAS_ProfShort_Dist1 0 "no other profile values are defi" ;
VAL_ 260 ADAS_ProfShort_CtrlPoint 0 "false" 1 "true" ;
VAL_ 258 ADAS_Seg_PartOfCalcRoute 0 "False" 1 "True" 2 "Unknown" 3 "Invalid" ;
VAL_ 258 ADAS_Seg_RelProbb 0 "Turn not allowed" 31 "Unknown" ;
VAL_ 258 ADAS_Seg_Offset 8191 "invalid" ;
VAL_ 258 ADAS_Seg_Retr 0 "false" 1 "true" ;
VAL_ 258 ADAS_Seg_PathIdx 0 "Unknown" 1 "Position not in digitized Area" 2 "Position not on-road" 3 "System not calibrated" 4 "Current Segment Attributes" 5 "Stub only" 6 "This Path" 7 "Reserved" ;
VAL_ 258 ADAS_Seg_MsgType 0 "SNA" 1 "POSITION" 2 "SEGMENT" 3 "STUB" 4 "PROFILE_SHORT" 5 "PROFILE_LONG" 6 "META_DATA" 7 "RESERVED" ;
VAL_ 258 ADAS_Seg_FormOfWay 0 "Unknown" 1 "Freeway without Slip Roads" 2 "Multiply Carriageway" 3 "Single Carriageway" 4 "Roundabout" 5 "Special Traffic Figure" 6 "Reserved6" 7 "Reserved7" 8 "Parallel Road" 9 "Slip Road on Freeway" 10 "Slip Road not on Freeway" 11 "Service or Frontage Road" 12 "Entrance to or Exit of Car Park" 13 "Entrance to or Exit to Service" 14 "Pedestrian Zone" 15 "SNA" ;
VAL_ 258 ADAS_Seg_CmplxInsct 0 "False" 1 "True" 2 "Unknown" 3 "Invalid" ;
VAL_ 258 ADAS_Seg_BuildUpArea 0 "False" 1 "True" 2 "Unknown" 3 "Invalid" ;
VAL_ 258 ADAS_Seg_DividedRoad 0 "False" 1 "True" 2 "Unknown" 3 "Invalid" ;
VAL_ 258 ADAS_Seg_Bridge 0 "False" 1 "True" 2 "Unknown" 3 "Invalid" ;
VAL_ 258 ADAS_Seg_Tunnel 0 "False" 1 "True" 2 "Unknown" 3 "Invalid" ;
VAL_ 258 ADAS_Seg_NumOfLaneOppDir 0 "One direction road" 1 "One lane only" 2 "Two or more lanes" 3 "Unknown" ;
VAL_ 258 ADAS_Seg_NumOfLaneDrvDir 0 "Wrong direction" 6 "6 or more lanes" 7 "Unknown" ;
VAL_ 258 ADAS_Seg_EffSpdLmtType 0 "Implicit" 1 "Explicit_on_sign" 2 "Explicit_by_night" 3 "Explicit_by_day" 4 "Explicit_time_of_day" 5 "Explicit_rain" 6 "Explicit_snow" 7 "Unknown" ;
VAL_ 258 ADAS_Seg_EffSpdLmt 0 "Unknown" 1 "5 kmph or mph" 2 "7 kmph or mph" 3 "10 kmph or mph" 4 "15 kmph or mph" 5 "20 kmph or mph" 6 "25 kmph or mph" 7 "30 kmph or mph" 8 "35 kmph or mph" 9 "40 kmph or mph" 10 "45 kmph or mph" 11 "50 kmph or mph" 12 "55 kmph or mph" 13 "60 kmph or mph" 14 "65 kmph or mph" 15 "70 kmph or mph" 16 "75 kmph or mph" 17 "80 kmph or mph" 18 "85 kmph or mph" 19 "90 kmph or mph" 20 "95 kmph or mph" 21 "100 kmph or mph" 22 "105 kmph or mph" 23 "110 kmph or mph" 24 "115 kmph or mph" 25 "120 kmph or mph" 26 "130 kmph or mph" 27 "140 kmph or mph" 28 "150 kmph or mph" 29 "160 kmph or mph" 30 "Unlimited" 31 "SNA" ;
VAL_ 258 ADAS_Seg_FuncRoadClass 0 "Unknown" 7 "SNA" ;
VAL_ 258 ADAS_Seg_Update 0 "false" 1 "true" ;
VAL_ 259 ADAS_Stub_PartOfCalcRoute 0 "false" 1 "true" ;
VAL_ 259 ADAS_Stub_FuncRoadClass 0 "Unknown" 7 "SNA" ;
VAL_ 259 ADAS_Stub_LastStub 255 "Unknown" ;
VAL_ 259 ADAS_Stub_Update 0 "false" 1 "true" ;
VAL_ 259 ADAS_Stub_SubPathIdx 0 "Unknown" 1 "Position not in digitized Area" 2 "Position not on-road" 3 "System not calibrated" 4 "Current Segment Attributes" 5 "Stub only" 6 "This Path" 7 "Reserved" ;
VAL_ 259 ADAS_Stub_Retr 0 "false" 1 "true" ;
VAL_ 259 ADAS_Stub_PathIdx 0 "Unknown" 1 "Position not in digitized Area" 2 "Position not on-road" 3 "System not calibrated" 4 "Current Segment Attributes" 5 "Stub only" 6 "This Path" 7 "Reserved" ;
VAL_ 259 ADAS_Stub_Offset 8191 "invalid" ;
VAL_ 259 ADAS_Stub_NumOfLaneOppDir 0 "One direction road" 1 "One lane only" 2 "Two or more lanes" 3 "Unknown" ;
VAL_ 259 ADAS_Stub_NumOfLaneDrvDir 0 "Wrong direction" 6 "6 or more lanes" 7 "Unknown" ;
VAL_ 259 ADAS_Stub_MsgType 0 "SNA" 1 "POSITION" 2 "SEGMENT" 3 "STUB" 4 "PROFILE_SHORT" 5 "PROFILE_LONG" 6 "META_DATA" 7 "RESERVED" ;
VAL_ 259 ADAS_Stub_FormOfWay 0 "Unknown" 1 "Freeway without Slip Roads" 2 "Multiply Carriageway" 3 "Single Carriageway" 4 "Roundabout" 5 "Special Traffic Figure" 6 "Reserved6" 7 "Reserved7" 8 "Parallel Road" 9 "Slip Road on Freeway" 10 "Slip Road not on Freeway" 11 "Service or Frontage Road" 12 "Entrance to or Exit of Car Park" 13 "Entrance to or Exit to Service" 14 "Pedestrian Zone" 15 "SNA" ;
VAL_ 259 ADAS_Stub_RtOfWay 0 "Path has rt-of-way over sub-path" 1 "Sub-path has rt-of-way over path" 2 "Unknown" 3 "Invalid" ;
VAL_ 259 ADAS_Stub_CmplxInsct 0 "False" 1 "True" 2 "Unknown" 3 "Invalid" ;
VAL_ 259 ADAS_Stub_RelProbb 0 "Turn not allowed" 31 "Unknown" ;
VAL_ 259 ADAS_Stub_TurnAngl 0 "In path direction" 1 "1.417 deg right from path dir" 126 "178.583 deg right" 127 "Opposite direction" 128 "178.583 deg left" 253 "1.417 deg left from path dir" 254 "Unknown" 255 "SNA" ;
VAL_ 449 DADCSteerTqReqActive 0 "SteeringTorque req not active" 1 "HO SteeringTorque request active" 2 "HF SteeringTorque request active" ;
VAL_ 449 ADAS_RdWhlAgReqActive 0 "RdWhlAgReq not active" 1 "HO RdWhlAgReq active" 2 "HF RdWhl AgReq active" ;
VAL_ 272 ADASLONG_Mux_MsgTyp 0 "SNA" 1 "POSITION" 2 "SEGMENT" 3 "STUB" 4 "PROFILE_SHORT" 5 "PROFILE_LONG" 6 "META_DATA" 7 "RESERVED" ;
VAL_ 443 ShiftInProgress 0 "no shift" 1 "shift in progress" ;
VAL_ 432 APA_Sts 0 "Not Active" 1 "Background Scanning" 2 "Active Scanning" 3 "Selecting" 4 "Confirming" 5 "Manoeuvering" 6 "Paused" 7 "Finishing" 8 "Ended/Cancel" 9 "Failured" 10 "Reserved" 11 "Reserved" 12 "Reserved" 13 "Reserved" 14 "Reserved" 15 "Reserved" ;
VAL_ 658 APA_CrtPrkgTyp 0 "None" 1 "Automated" 2 "Remote" 3 "Reserved" ;
VAL_ 672 APA_FMEBSts 0 "OFF" 1 "Inactive" 2 "Ready" 3 "PreFill" 4 "AEB Active" 5 "Standstill" 6 "Secure" 7 "Finished With Override" 8 "Finished Without Override" 9 "Error" 10 "Reserved" 11 "Reserved" 12 "Reserved" 13 "Reserved" 14 "Reserved" 15 "Reserved" ;
VAL_ 672 APA_RMEBSts 0 "Off" 1 "Inactive" 2 "Ready" 3 "PreFill" 4 "AEB Active" 5 "Standstill" 6 "Secure" 7 "Finished With Override" 8 "Finished Without Override" 9 "Error" 10 "Reserved" 11 "Reserved" 12 "Reserved" 13 "Reserved" 14 "Reserved" 15 "Reserved" ;
VAL_ 1368 APA_Sts_PAS 0 "Disable" 1 "Enable" 2 "Active" 3 "Failed" ;
VAL_ 821 BCM_ReFogLampSwtSts 0 "Inactive" 1 "Active" ;
VAL_ 821 BCM_DangerAlrmLampSwtSts 0 "Off" 1 "On" ;
VAL_ 821 BCM_LeTrunLampOutpCmd 0 "Off" 1 "On" ;
VAL_ 821 BCM_RiTrunLampOutpCmd 0 "Off" 1 "On" ;
VAL_ 821 BCM_ReWiprOutpCmd 0 "Off" 1 "On" ;
VAL_ 821 BCM_HiBeamOutpCmd 0 "Off" 1 "On" ;
VAL_ 821 BCM_LoBeamOutpCmd 0 "Off" 1 "On" ;
VAL_ 835 BCM_TrailerConnection 0 "Trailer not connected" 1 "Trailer connected" ;
VAL_ 835 BCM_FrntHoodLidSts 0 "Closed" 1 "Open" ;
VAL_ 835 BCM_LeFrntDoorSts 0 "Closed" 1 "Open" ;
VAL_ 835 BCM_RiFrntDoorSts 0 "Closed" 1 "Open" ;
VAL_ 835 BCM_RiReDoorSts 0 "Closed" 1 "Open" ;
VAL_ 835 BCM_LeReDoorSts 0 "Closed" 1 "Open" ;
VAL_ 784 CIM_MainSwitchCC 0 "Not pressed" 1 "Pressed" ;
VAL_ 784 CIM_MainSwitchLimiter 0 "Not pressed" 1 "Pressed" ;
VAL_ 784 CIM_TurnLampSwtSts 0 "Default" 1 "Turn Left indicator" 2 "Turn Right indicator" 3 "Invalid" ;
VAL_ 784 CIM_HiBeamSwtSts 0 "Neutral" 1 "Flash" 2 "Toggle" 3 "Invalid" ;
VAL_ 784 CIM_FrntWshrSwtSts 0 "Off" 1 "On" 2 "Reserved" 3 "Invalid" ;
VAL_ 784 CIM_ReWshrSwtSts 0 "Off" 1 "On" 2 "Reserved" 3 "Invalid" ;
VAL_ 784 CIM_FrntWiprSwtSts 0 "Off" 1 "AutoLow" 2 "AutoHigh" 3 "Low" 4 "High" 5 "Reserved" 6 "Reserved" 7 "Invalid" ;
VAL_ 784 CIM_Swt_ADAS 0 "Not Pressed" 1 "ACC Set" 2 "LKS Switch" 3 "ACC Resume" ;
VAL_ 784 CIM_Cncl_ADAS 0 "Not Pressed" 1 "Pressed" 2 "Reserved" 3 "Invalid" ;
VAL_ 784 CIM_SpdRgln_ADAS 0 "Inactive/Default" 1 "Set speed +1" 2 "Reserved - Set speed +5" 3 "Set speed -1" 4 "Reserved - Set speed -5" 5 "Reserved" 6 "Reserved" 7 "Invalid" ;
VAL_ 784 CIM_DstWithCarFrntAdj 0 "Inactive/Default" 1 "Gap -" 2 "Gap +" 3 "Reserved" 4 "Reserved" 5 "Reserved" 6 "Reserved" 7 "Invalid" ;
VAL_ 784 CIM_SpdLim_ADAS 0 "Not Pressed" 1 "Pressed" 2 "Reserved" 3 "Invalid" ;
VAL_ 784 CIM_SwtVld_ADAS 0 "Initializing" 1 "Valid" 2 "Invalid" 3 "Reserved" ;
VAL_ 784 CIM_SpdRglnVld_ADAS 0 "Initializing" 1 "Valid" 2 "Invalid" 3 "Reserved" ;
VAL_ 604 CMRR_FL_FrntLeSnsrFlt 0 "No Failure" 1 "Reversible Failure" 2 "Irrversible Failure" 3 "Reserved" ;
VAL_ 604 CMRR_FL_FrntLeSnsrBli 0 "No Blind" 1 "Blind" 2 "Reserved" 3 "Reserved" ;
VAL_ 604 CMRR_FL_SDASts 0 "Default" 1 "No Fault" 2 "Fault" 3 "Dynamic calibration running" ;
VAL_ 604 CMRR_FL_SDAWarn 0 "Inactive" 1 "Active" ;
VAL_ 606 CMRR_FR_FrntLeSnsrFlt 0 "No Failure" 1 "Reversible Failure" 2 "Irrversible Failure" 3 "Reserved" ;
VAL_ 606 CMRR_FR_FrntLeSnsrBli 0 "No Blind" 1 "Blind" 2 "Reserved" 3 "Reserved" ;
VAL_ 606 CMRR_FR_SDASts 0 "Default" 1 "No Fault" 2 "Fault" 3 "Dynamic calibration running" ;
VAL_ 606 CMRR_FR_SDAWarn 0 "Inactive" 1 "Active" ;
VAL_ 824 CMRR_RL_LeWarn_LCA 0 "No Warning" 1 "Warning Level 1" 2 "Warning Level 2" 3 "Reserved" ;
VAL_ 824 CMRR_RL_SnsrFlt 0 "No Failure" 1 "Reversible Failure" 2 "Irrversible Failure" 3 "Reserved" ;
VAL_ 824 CMRR_RL_SnsrBli 0 "No Blind" 1 "Blind" 2 "Reserved" 3 "Reserved" ;
VAL_ 824 CMRR_RL_LeWarn_LCA_ELK 0 "No Warning" 1 "Warning Level 1" 2 "Warning Level 2" 3 "Reserved" ;
VAL_ 824 CMRR_RL_SDASts 0 "Default" 1 "No Fault" 2 "Fault" 3 "Dynamic calibration running" ;
VAL_ 824 CMRR_RL_SDAWarn 0 "Inactive" 1 "Active" ;
VAL_ 826 CMRR_RR_RiWarn_LCA 0 "No Warning" 1 "Warning Level 1" 2 "Warning Level 2" 3 "Reserved" ;
VAL_ 826 CMRR_RR_SnsrFlt 0 "No Failure" 1 "Reversible Failure" 2 "Irrversible Failure" 3 "Reserved" ;
VAL_ 826 CMRR_RR_SnsrBli 0 "No Blind" 1 "Blind" 2 "Reserved" 3 "Reserved" ;
VAL_ 826 CMRR_RR_LCASwtFb 0 "Default" 1 "Switch Off" 2 "Switch On" 3 "Fault" ;
VAL_ 826 CMRR_RR_RiWarn_LCA_ELK 0 "No Warning" 1 "Warning Level 1" 2 "Warning Level 2" 3 "Reserved" ;
VAL_ 826 CMRR_RR_SDAWarn 0 "Inactive" 1 "Active" ;
VAL_ 826 CMRR_RR_SDASts 0 "Default" 1 "No Fault" 2 "Fault" 3 "Dynamic calibration running" ;
VAL_ 800 DMSAdoWrnngDspCmdHSC4 0 "Unavailable" 1 "Off" 2 "On" ;
VAL_ 800 DMSAudReqHSC4 0 "Unavailable" 1 "Off" 2 "On" ;
VAL_ 800 DMSDspCmdHSC4 0 "Unavailable" 1 "Off" 2 "On" ;
VAL_ 800 DMSHapticWrnngDspCmdHSC4 0 "Unavailable" 1 "Off" 2 "On" ;
VAL_ 800 DMSStsHSC4 0 "Off" 1 "Standby" 2 "Active" 3 "Fault" 4 "Camera Blocked" 5 "Initialization" ;
VAL_ 800 DMSVbnLvlReqHSC4 0 "Unavailable" 1 "Off" 2 "On" ;
VAL_ 800 DMSWrnngReqHSC4 0 "No request" 1 "Fatigue request" 2 "Distraction request" ;
VAL_ 800 DrvrAbnormBehvorHSC4 0 "Unknown" 1 "No abnormal behaviour" 2 "Telephone calls" 3 "Smoking" 4 "Drinking water" 5 "Eating" 6 "Reserved" 7 "Reserved" 8 "Reserved" 9 "Reserved" 10 "Reserved" 11 "Reserved" 12 "Reserved" 13 "Reserved" 14 "Reserved" 15 "Reserved" ;
VAL_ 800 DrvrDstcnStsHSC4 0 "Unknown" 1 "No distraction" 2 "Low level distraction" 3 "Middle level distraction" 4 "High level distraction" 5 "Reserve" 6 "Reserve" 7 "Reserve" ;
VAL_ 800 DrvrFtgLvlHSC4 0 "Unknown" 1 "No Drowsiness" 2 "Low level Drowsiness" 3 "Middle level Drowsiness" 4 "High level Drowsiness" 5 "Reserve" 6 "Reserve" 7 "Reserve" ;
VAL_ 800 DrvrGazeRgnHSC4 0 "Init/Unknown" 1 "Driver Side of Windscreen" 2 "Copilot Side of Windscreen" 3 "Left Rear View Mirror" 4 "Right Rear View Mirror" 5 "Left Side Window" 6 "Right Side Window" 7 "Central Rear View Mirror" 8 "Central driver's Instrument Cluster(speed gauge,etc.)" 9 "Head-up display" 10 "Navigation Display" 11 "Middle Instrument Cluster(A/C,radio,etc.)" 12 "Steering Wheel(e.g.button area)" 13 "Left Seat Foot Area" 14 "Right Seat Foot Area &Workbench" 15 "Left Side door area" 16 "Right Side door area" 17 "reserved" 18 "reserved" 19 "reserved" 20 "reserved" 21 "reserved" 22 "reserved" 23 "reserved" 24 "reserved" 25 "reserved" 26 "reserved" 27 "reserved" 28 "reserved" 29 "reserved" 30 "reserved" 31 "reserved" ;
VAL_ 800 DrvrPrstHSC4 0 "Unknown" 1 "Driver Not Presence" 2 "Driver  Presence" ;
VAL_ 800 EyeOnRoadHSC4 0 "Unavailable" 1 "Eyes On Road" 2 "Eyes Off Road - driving task related region" 3 "Eyes Off Road - non-driving task related region" ;
VAL_ 800 SpfngDetHSC4 0 "Unknown" 1 "Not Detected" 2 "Detected" ;
VAL_ 883 ECC_OutdT 255 "Invalid" ;
VAL_ 883 ECC_OutdTVld 0 "Initializing" 1 "Valid" 2 "Invalid" 3 "Reserved" ;
VAL_ 1410 ECC_InsdT 255 "Invalid" ;
VAL_ 1228 Ego_Lane_Map_Status 0 "INVALID" 1 "VALID" ;
VAL_ 1228 Ego_Lane_CurrentSpeedLimit_Type 0 "EFFECTIVE" 1 "IMPLICIT" 2 "UNKNOWN" 3 "RESERVED" ;
VAL_ 1228 Ego_Lane_NextSpeedLimit_Type_1 0 "EFFECTIVE" 1 "IMPLICIT" 2 "UNKNOWN" 3 "RESERVED" ;
VAL_ 1228 Ego_Lane_NextSpeedLimit_Type_2 0 "EFFECTIVE" 1 "IMPLICIT" 2 "UNKNOWN" 3 "RESERVED" ;
VAL_ 1228 Ego_Lane_NextSpeedLimit_Type_3 0 "EFFECTIVE" 1 "IMPLICIT" 2 "UNKNOWN" 3 "RESERVED" ;
VAL_ 1228 Ego_Lane_NextSpeedLimit_Type_4 0 "EFFECTIVE" 1 "IMPLICIT" 2 "UNKNOWN" 3 "RESERVED" ;
VAL_ 1228 Ego_Lane_NextTopoType_1 0 "UNKNOWN" 1 "OPENING" 2 "CLOSING" 3 "MERGING" 4 "SPLITTING" 5 "ROAD_MERGING" 6 "ROAD_SPLITTING" ;
VAL_ 1228 Ego_Lane_NextTopoSide_1 0 "LEFT" 1 "RIGHT" ;
VAL_ 1228 Ego_Lane_NextTopoType_2 0 "UNKNOWN" 1 "OPENING" 2 "CLOSING" 3 "MERGING" 4 "SPLITTING" 5 "ROAD_MERGING" 6 "ROAD_SPLITTING" ;
VAL_ 1228 Ego_Lane_NextTopoSide_2 0 "LEFT" 1 "RIGHT" ;
VAL_ 1228 Ego_Lane_NextTopoType_3 0 "UNKNOWN" 1 "OPENING" 2 "CLOSING" 3 "MERGING" 4 "SPLITTING" 5 "ROAD_MERGING" 6 "ROAD_SPLITTING" ;
VAL_ 1228 Ego_Lane_NextTopoSide_3 0 "LEFT" 1 "RIGHT" ;
VAL_ 1228 Ego_Lane_NextTopoType_4 0 "UNKNOWN" 1 "OPENING" 2 "CLOSING" 3 "MERGING" 4 "SPLITTING" 5 "ROAD_MERGING" 6 "ROAD_SPLITTING" ;
VAL_ 1228 Ego_Lane_NextTopoSide_4 0 "LEFT" 1 "RIGHT" ;
VAL_ 1228 Ego_Lane_CurrBoundary_Type_R 0 "TYPE_SOLID_LINE" 1 "TYPE_DASHED_LINE" 2 "TYPE_DOUBLE_DASHED_DASHED" 3 "TYPE_DOUBLE_DASHED_SOLID" 4 "TYPE_DOUBLE_SOLID_DASHED" 5 "TYPE_DOUBLE_SOLID_SOLID" 6 "TYPE_MULTIPLE" 7 "TYPE_MULTIPLE_WARNING" 8 "TYPE_CAR_POOL" 9 "TYPE_ASPHALT_JOIN" 10 "TYPE_BOTTS_DOTS" 11 "TYPE_ROAD_EDGE" 12 "TYPE_GUARDRAIL" 13 "TYPE_CURBSTONE" 14 "TYPE_WALL" 15 "TYPE_TRAFFIC_CONE" 16 "TYPE_DELINEATOR_POST" 17 "TYPE_PARKING_CAR" 18 "TYPE_UNKNOWN_RAISED" 19 "TYPE_UNKNOWN" ;
VAL_ 1228 Ego_Lane_NextBoundary_Type_R_1 0 "TYPE_SOLID_LINE" 1 "TYPE_DASHED_LINE" 2 "TYPE_DOUBLE_DASHED_DASHED" 3 "TYPE_DOUBLE_DASHED_SOLID" 4 "TYPE_DOUBLE_SOLID_DASHED" 5 "TYPE_DOUBLE_SOLID_SOLID" 6 "TYPE_MULTIPLE" 7 "TYPE_MULTIPLE_WARNING" 8 "TYPE_CAR_POOL" 9 "TYPE_ASPHALT_JOIN" 10 "TYPE_BOTTS_DOTS" 11 "TYPE_ROAD_EDGE" 12 "TYPE_GUARDRAIL" 13 "TYPE_CURBSTONE" 14 "TYPE_WALL" 15 "TYPE_TRAFFIC_CONE" 16 "TYPE_DELINEATOR_POST" 17 "TYPE_PARKING_CAR" 18 "TYPE_UNKNOWN_RAISED" 19 "TYPE_UNKNOWN" ;
VAL_ 1228 Ego_Lane_NextBoundary_Type_R_2 0 "TYPE_SOLID_LINE" 1 "TYPE_DASHED_LINE" 2 "TYPE_DOUBLE_DASHED_DASHED" 3 "TYPE_DOUBLE_DASHED_SOLID" 4 "TYPE_DOUBLE_SOLID_DASHED" 5 "TYPE_DOUBLE_SOLID_SOLID" 6 "TYPE_MULTIPLE" 7 "TYPE_MULTIPLE_WARNING" 8 "TYPE_CAR_POOL" 9 "TYPE_ASPHALT_JOIN" 10 "TYPE_BOTTS_DOTS" 11 "TYPE_ROAD_EDGE" 12 "TYPE_GUARDRAIL" 13 "TYPE_CURBSTONE" 14 "TYPE_WALL" 15 "TYPE_TRAFFIC_CONE" 16 "TYPE_DELINEATOR_POST" 17 "TYPE_PARKING_CAR" 18 "TYPE_UNKNOWN_RAISED" 19 "TYPE_UNKNOWN" ;
VAL_ 1228 Ego_Lane_NextBoundary_Type_R_3 0 "TYPE_SOLID_LINE" 1 "TYPE_DASHED_LINE" 2 "TYPE_DOUBLE_DASHED_DASHED" 3 "TYPE_DOUBLE_DASHED_SOLID" 4 "TYPE_DOUBLE_SOLID_DASHED" 5 "TYPE_DOUBLE_SOLID_SOLID" 6 "TYPE_MULTIPLE" 7 "TYPE_MULTIPLE_WARNING" 8 "TYPE_CAR_POOL" 9 "TYPE_ASPHALT_JOIN" 10 "TYPE_BOTTS_DOTS" 11 "TYPE_ROAD_EDGE" 12 "TYPE_GUARDRAIL" 13 "TYPE_CURBSTONE" 14 "TYPE_WALL" 15 "TYPE_TRAFFIC_CONE" 16 "TYPE_DELINEATOR_POST" 17 "TYPE_PARKING_CAR" 18 "TYPE_UNKNOWN_RAISED" 19 "TYPE_UNKNOWN" ;
VAL_ 1228 Ego_Lane_NextBoundary_Type_R_4 0 "TYPE_SOLID_LINE" 1 "TYPE_DASHED_LINE" 2 "TYPE_DOUBLE_DASHED_DASHED" 3 "TYPE_DOUBLE_DASHED_SOLID" 4 "TYPE_DOUBLE_SOLID_DASHED" 5 "TYPE_DOUBLE_SOLID_SOLID" 6 "TYPE_MULTIPLE" 7 "TYPE_MULTIPLE_WARNING" 8 "TYPE_CAR_POOL" 9 "TYPE_ASPHALT_JOIN" 10 "TYPE_BOTTS_DOTS" 11 "TYPE_ROAD_EDGE" 12 "TYPE_GUARDRAIL" 13 "TYPE_CURBSTONE" 14 "TYPE_WALL" 15 "TYPE_TRAFFIC_CONE" 16 "TYPE_DELINEATOR_POST" 17 "TYPE_PARKING_CAR" 18 "TYPE_UNKNOWN_RAISED" 19 "TYPE_UNKNOWN" ;
VAL_ 1228 Ego_Lane_CurrBoundary_Type_L 0 "TYPE_SOLID_LINE" 1 "TYPE_DASHED_LINE" 2 "TYPE_DOUBLE_DASHED_DASHED" 3 "TYPE_DOUBLE_DASHED_SOLID" 4 "TYPE_DOUBLE_SOLID_DASHED" 5 "TYPE_DOUBLE_SOLID_SOLID" 6 "TYPE_MULTIPLE" 7 "TYPE_MULTIPLE_WARNING" 8 "TYPE_CAR_POOL" 9 "TYPE_ASPHALT_JOIN" 10 "TYPE_BOTTS_DOTS" 11 "TYPE_ROAD_EDGE" 12 "TYPE_GUARDRAIL" 13 "TYPE_CURBSTONE" 14 "TYPE_WALL" 15 "TYPE_TRAFFIC_CONE" 16 "TYPE_DELINEATOR_POST" 17 "TYPE_PARKING_CAR" 18 "TYPE_UNKNOWN_RAISED" 19 "TYPE_UNKNOWN" ;
VAL_ 1228 Ego_Lane_NextBoundary_Type_L_1 0 "TYPE_SOLID_LINE" 1 "TYPE_DASHED_LINE" 2 "TYPE_DOUBLE_DASHED_DASHED" 3 "TYPE_DOUBLE_DASHED_SOLID" 4 "TYPE_DOUBLE_SOLID_DASHED" 5 "TYPE_DOUBLE_SOLID_SOLID" 6 "TYPE_MULTIPLE" 7 "TYPE_MULTIPLE_WARNING" 8 "TYPE_CAR_POOL" 9 "TYPE_ASPHALT_JOIN" 10 "TYPE_BOTTS_DOTS" 11 "TYPE_ROAD_EDGE" 12 "TYPE_GUARDRAIL" 13 "TYPE_CURBSTONE" 14 "TYPE_WALL" 15 "TYPE_TRAFFIC_CONE" 16 "TYPE_DELINEATOR_POST" 17 "TYPE_PARKING_CAR" 18 "TYPE_UNKNOWN_RAISED" 19 "TYPE_UNKNOWN" ;
VAL_ 1228 Ego_Lane_NextBoundary_Type_L_2 0 "TYPE_SOLID_LINE" 1 "TYPE_DASHED_LINE" 2 "TYPE_DOUBLE_DASHED_DASHED" 3 "TYPE_DOUBLE_DASHED_SOLID" 4 "TYPE_DOUBLE_SOLID_DASHED" 5 "TYPE_DOUBLE_SOLID_SOLID" 6 "TYPE_MULTIPLE" 7 "TYPE_MULTIPLE_WARNING" 8 "TYPE_CAR_POOL" 9 "TYPE_ASPHALT_JOIN" 10 "TYPE_BOTTS_DOTS" 11 "TYPE_ROAD_EDGE" 12 "TYPE_GUARDRAIL" 13 "TYPE_CURBSTONE" 14 "TYPE_WALL" 15 "TYPE_TRAFFIC_CONE" 16 "TYPE_DELINEATOR_POST" 17 "TYPE_PARKING_CAR" 18 "TYPE_UNKNOWN_RAISED" 19 "TYPE_UNKNOWN" ;
VAL_ 1228 Ego_Lane_NextBoundary_Type_L_3 0 "TYPE_SOLID_LINE" 1 "TYPE_DASHED_LINE" 2 "TYPE_DOUBLE_DASHED_DASHED" 3 "TYPE_DOUBLE_DASHED_SOLID" 4 "TYPE_DOUBLE_SOLID_DASHED" 5 "TYPE_DOUBLE_SOLID_SOLID" 6 "TYPE_MULTIPLE" 7 "TYPE_MULTIPLE_WARNING" 8 "TYPE_CAR_POOL" 9 "TYPE_ASPHALT_JOIN" 10 "TYPE_BOTTS_DOTS" 11 "TYPE_ROAD_EDGE" 12 "TYPE_GUARDRAIL" 13 "TYPE_CURBSTONE" 14 "TYPE_WALL" 15 "TYPE_TRAFFIC_CONE" 16 "TYPE_DELINEATOR_POST" 17 "TYPE_PARKING_CAR" 18 "TYPE_UNKNOWN_RAISED" 19 "TYPE_UNKNOWN" ;
VAL_ 1228 Ego_Lane_NextBoundary_Type_L_4 0 "TYPE_SOLID_LINE" 1 "TYPE_DASHED_LINE" 2 "TYPE_DOUBLE_DASHED_DASHED" 3 "TYPE_DOUBLE_DASHED_SOLID" 4 "TYPE_DOUBLE_SOLID_DASHED" 5 "TYPE_DOUBLE_SOLID_SOLID" 6 "TYPE_MULTIPLE" 7 "TYPE_MULTIPLE_WARNING" 8 "TYPE_CAR_POOL" 9 "TYPE_ASPHALT_JOIN" 10 "TYPE_BOTTS_DOTS" 11 "TYPE_ROAD_EDGE" 12 "TYPE_GUARDRAIL" 13 "TYPE_CURBSTONE" 14 "TYPE_WALL" 15 "TYPE_TRAFFIC_CONE" 16 "TYPE_DELINEATOR_POST" 17 "TYPE_PARKING_CAR" 18 "TYPE_UNKNOWN_RAISED" 19 "TYPE_UNKNOWN" ;
VAL_ 1229 Ego_Lane_NextHotspot_Type_1 0 "HOTSPOT_NONE" 1 "HOTSPOT_BRAKE" 2 "HOTSPOT_LC_IN" 3 "HOTSPOT_LC_OUT" 4 "HOTSPOT_STOP" 5 "RESERVED" 6 "RESERVED" 7 "RESERVED" ;
VAL_ 1229 Ego_Lane_NextHotspot_Side_1 0 "LEFT" 1 "RIGHT" ;
VAL_ 1229 Ego_Lane_NextHotspot_Type_2 0 "HOTSPOT_NONE" 1 "HOTSPOT_BRAKE" 2 "HOTSPOT_LC_IN" 3 "HOTSPOT_LC_OUT" 4 "HOTSPOT_STOP" 5 "RESERVED" 6 "RESERVED" 7 "RESERVED" ;
VAL_ 1229 Ego_Lane_NextHotspot_Side_2 0 "LEFT" 1 "RIGHT" ;
VAL_ 1229 Ego_Lane_NextHotspot_Type_3 0 "HOTSPOT_NONE" 1 "HOTSPOT_BRAKE" 2 "HOTSPOT_LC_IN" 3 "HOTSPOT_LC_OUT" 4 "HOTSPOT_STOP" 5 "RESERVED" 6 "RESERVED" 7 "RESERVED" ;
VAL_ 1229 Ego_Lane_NextHotspot_Side_3 0 "LEFT" 1 "RIGHT" ;
VAL_ 1229 Ego_Lane_NextHotspot_Type_4 0 "HOTSPOT_NONE" 1 "HOTSPOT_BRAKE" 2 "HOTSPOT_LC_IN" 3 "HOTSPOT_LC_OUT" 4 "HOTSPOT_STOP" 5 "RESERVED" 6 "RESERVED" 7 "RESERVED" ;
VAL_ 1229 Ego_Lane_NextHotspot_Side_4 0 "LEFT" 1 "RIGHT" ;
VAL_ 1230 Left_CurrentSpeedLimit_Type 0 "EFFECTIVE" 1 "IMPLICIT" 2 "UNKNOWN" 3 "RESERVED" ;
VAL_ 1230 Left_NextSpeedLimit_Type_1 0 "EFFECTIVE" 1 "IMPLICIT" 2 "UNKNOWN" 3 "RESERVED" ;
VAL_ 1230 Left_NextSpeedLimit_Type_2 0 "EFFECTIVE" 1 "IMPLICIT" 2 "UNKNOWN" 3 "RESERVED" ;
VAL_ 1230 Left_NextSpeedLimit_Type_3 0 "EFFECTIVE" 1 "IMPLICIT" 2 "UNKNOWN" 3 "RESERVED" ;
VAL_ 1230 Left_NextSpeedLimit_Type_4 0 "EFFECTIVE" 1 "IMPLICIT" 2 "UNKNOWN" 3 "RESERVED" ;
VAL_ 1230 Left_NextTopo_Type_1 0 "UNKNOWN" 1 "OPENING" 2 "CLOSING" 3 "MERGING" 4 "SPLITTING" 5 "ROAD_MERGING" 6 "ROAD_SPLITTING" ;
VAL_ 1230 Left_NextTopo_Side_1 0 "LEFT" 1 "RIGHT" ;
VAL_ 1230 Left_NextTopo_Type_2 0 "UNKNOWN" 1 "OPENING" 2 "CLOSING" 3 "MERGING" 4 "SPLITTING" 5 "ROAD_MERGING" 6 "ROAD_SPLITTING" ;
VAL_ 1230 Left_NextTopo_Side_2 0 "LEFT" 1 "RIGHT" ;
VAL_ 1230 Left_NextTopo_Type_3 0 "UNKNOWN" 1 "OPENING" 2 "CLOSING" 3 "MERGING" 4 "SPLITTING" 5 "ROAD_MERGING" 6 "ROAD_SPLITTING" ;
VAL_ 1230 Left_NextTopo_Side_3 0 "LEFT" 1 "RIGHT" ;
VAL_ 1230 Left_NextTopo_Type_4 0 "UNKNOWN" 1 "OPENING" 2 "CLOSING" 3 "MERGING" 4 "SPLITTING" 5 "ROAD_MERGING" 6 "ROAD_SPLITTING" ;
VAL_ 1230 Left_NextTopo_Side_4 0 "LEFT" 1 "RIGHT" ;
